VERSION "12.2.7"

NS_ :

BS_:

BU_: AMP CPD EASC HUD MHU XGW_Info PAS_Info PAS_LITE FCAM_Info

BO_ 387 VCU_FS_B: 8 XGW_Info
  SG_ VCU_FS_B_1 : 0|1@0+ (1,0) [0|1] "" MHU
  SG_ VCU_FS_B_2 : 1|1@0+ (1,0) [0|1] "" MHU
  SG_ VCU_FS_B_3 : 2|1@0+ (1,0) [0|1] "" MHU
  SG_ VCU_FS_B_4 : 3|1@0+ (1,0) [0|1] "" MHU
  SG_ VCU_FS_B_5 : 4|1@0+ (1,0) [0|1] "" MHU
  SG_ VCU_FS_B_6 : 5|1@0+ (1,0) [0|1] "" MHU
  SG_ VCU_FS_B_7 : 6|1@0+ (1,0) [0|1] "" MHU
  SG_ VCU_FS_B_8 : 7|1@0+ (1,0) [0|1] "" MHU
  SG_ VCU_FS_B_9 : 8|1@0+ (1,0) [0|1] "" MHU
  SG_ VCU_FS_B_10 : 9|1@0+ (1,0) [0|1] "" MHU
  SG_ VCU_FS_B_11 : 10|1@0+ (1,0) [0|1] "" MHU
  SG_ VCU_FS_B_12 : 11|1@0+ (1,0) [0|1] "" MHU
  SG_ VCU_FS_B_13 : 12|1@0+ (1,0) [0|1] "" MHU
  SG_ VCU_FS_B_14 : 13|1@0+ (1,0) [0|1] "" MHU
  SG_ VCU_FS_B_15 : 14|1@0+ (1,0) [0|1] "" MHU
  SG_ VCU_FS_B_16 : 15|1@0+ (1,0) [0|1] "" MHU
  SG_ VCU_FS_B_17 : 16|1@0+ (1,0) [0|1] "" MHU
  SG_ VCU_FS_B_18 : 17|1@0+ (1,0) [0|1] "" MHU
  SG_ VCU_FS_B_19 : 18|1@0+ (1,0) [0|1] "" MHU
  SG_ VCU_FS_B_20 : 19|1@0+ (1,0) [0|1] "" MHU
  SG_ VCU_FS_B_21 : 20|1@0+ (1,0) [0|1] "" MHU
  SG_ VCU_FS_B_22 : 21|1@0+ (1,0) [0|1] "" MHU
  SG_ VCU_FS_B_23 : 22|1@0+ (1,0) [0|1] "" MHU
  SG_ VCU_FS_B_24 : 23|1@0+ (1,0) [0|1] "" MHU
  SG_ VCU_FS_B_25 : 24|1@0+ (1,0) [0|1] "" MHU
  SG_ VCU_FS_B_26 : 25|1@0+ (1,0) [0|1] "" MHU
  SG_ VCU_FS_B_27 : 26|1@0+ (1,0) [0|1] "" MHU
  SG_ VCU_FS_B_28 : 27|1@0+ (1,0) [0|1] "" MHU
  SG_ VCU_FS_B_29 : 28|1@0+ (1,0) [0|1] "" MHU
  SG_ VCU_FS_B_30 : 29|1@0+ (1,0) [0|1] "" MHU
  SG_ VCU_FS_B_31 : 30|1@0+ (1,0) [0|1] "" MHU
  SG_ VCU_FS_B_32 : 31|1@0+ (1,0) [0|1] "" MHU
  SG_ VCU_FS_B_33 : 32|1@0+ (1,0) [0|1] "" MHU
  SG_ VCU_FS_B_34 : 33|1@0+ (1,0) [0|1] "" MHU
  SG_ VCU_FS_B_35 : 34|1@0+ (1,0) [0|1] "" MHU
  SG_ VCU_FS_B_36 : 35|1@0+ (1,0) [0|1] "" MHU
  SG_ VCU_FS_B_37 : 36|1@0+ (1,0) [0|1] "" MHU
  SG_ VCU_FS_B_38 : 37|1@0+ (1,0) [0|1] "" MHU
  SG_ VCU_FS_B_39 : 38|1@0+ (1,0) [0|1] "" MHU
  SG_ VCU_FS_B_40 : 39|1@0+ (1,0) [0|1] "" MHU
  SG_ VCU_FS_B_41 : 40|1@0+ (1,0) [0|1] "" MHU
  SG_ VCU_FS_B_42 : 41|1@0+ (1,0) [0|1] "" MHU
  SG_ VCU_FS_B_43 : 42|1@0+ (1,0) [0|1] "" MHU
  SG_ VCU_FS_B_44 : 43|1@0+ (1,0) [0|1] "" MHU
  SG_ VCU_FS_B_45 : 44|1@0+ (1,0) [0|1] "" MHU
  SG_ VCU_FS_B_46 : 45|1@0+ (1,0) [0|1] "" MHU
  SG_ VCU_FS_B_47 : 46|1@0+ (1,0) [0|1] "" MHU
  SG_ VCU_FS_B_48 : 47|1@0+ (1,0) [0|1] "" MHU
  SG_ VCU_FS_B_49 : 48|1@0+ (1,0) [0|1] "" MHU
  SG_ VCU_FS_B_50 : 49|1@0+ (1,0) [0|1] "" MHU
  SG_ VCU_FS_B_51 : 50|1@0+ (1,0) [0|1] "" MHU
  SG_ VCU_FS_B_52 : 51|1@0+ (1,0) [0|1] "" MHU
  SG_ VCU_FS_B_53 : 52|1@0+ (1,0) [0|1] "" MHU
  SG_ VCU_FS_B_54 : 53|1@0+ (1,0) [0|1] "" MHU
  SG_ VCU_FS_B_55 : 54|1@0+ (1,0) [0|1] "" MHU
  SG_ VCU_FS_B_56 : 55|1@0+ (1,0) [0|1] "" MHU
  SG_ VCU_FS_B_57 : 56|1@0+ (1,0) [0|1] "" MHU
  SG_ VCU_FS_B_58 : 57|1@0+ (1,0) [0|1] "" MHU
  SG_ VCU_FS_B_59 : 58|1@0+ (1,0) [0|1] "" MHU
  SG_ VCU_FS_B_60 : 59|1@0+ (1,0) [0|1] "" MHU
  SG_ VCU_FS_B_61 : 60|1@0+ (1,0) [0|1] "" MHU
  SG_ VCU_FS_B_62 : 61|1@0+ (1,0) [0|1] "" MHU
  SG_ VCU_FS_B_63 : 62|1@0+ (1,0) [0|1] "" MHU
  SG_ VCU_FS_B_64 : 63|1@0+ (1,0) [0|1] "" MHU

BO_ 388 FCAM_BCM_Status: 8 FCAM_Info
 SG_ CHKSM_FCAM_BCM_Status : 7|8@0+ (1,0) [0|255] ""  XGW_Info
 SG_ ALIVE_FCAM_BCM_Status : 11|4@0+ (1,0) [0|14] ""  XGW_Info
 SG_ FCAM_BCM_IndicatorlightReq : 15|3@0+ (1,0) [0|7] ""  XGW_Info
 SG_ SECCAN_FCAM_BCM_Sts : 63|8@0+ (1,0) [0|255] ""  XGW_Info

BO_ 389 VCU_FS_C: 8 XGW_Info
SG_ VCU_FS_C_1 : 0|1@0+ (1,0) [0|1] ""  MHU
SG_ VCU_FS_C_2 : 1|1@0+ (1,0) [0|1] ""  MHU
SG_ VCU_FS_C_3 : 2|1@0+ (1,0) [0|1] ""  MHU
SG_ VCU_FS_C_4 : 3|1@0+ (1,0) [0|1] ""  MHU
SG_ VCU_FS_C_5 : 4|1@0+ (1,0) [0|1] ""  MHU
SG_ VCU_FS_C_6 : 5|1@0+ (1,0) [0|1] ""  MHU
SG_ VCU_FS_C_7 : 6|1@0+ (1,0) [0|1] ""  MHU
SG_ VCU_FS_C_8 : 7|1@0+ (1,0) [0|1] ""  MHU
SG_ VCU_FS_C_9 : 8|1@0+ (1,0) [0|1] ""  MHU
SG_ VCU_FS_C_10 : 9|1@0+ (1,0) [0|1] ""  MHU
SG_ VCU_FS_C_11 : 10|1@0+ (1,0) [0|1] ""  MHU
SG_ VCU_FS_C_12 : 11|1@0+ (1,0) [0|1] ""  MHU
SG_ VCU_FS_C_13 : 12|1@0+ (1,0) [0|1] ""  MHU
SG_ VCU_FS_C_14 : 13|1@0+ (1,0) [0|1] ""  MHU
SG_ VCU_FS_C_15 : 14|1@0+ (1,0) [0|1] ""  MHU
SG_ VCU_FS_C_16 : 15|1@0+ (1,0) [0|1] ""  MHU
SG_ VCU_FS_C_17 : 16|1@0+ (1,0) [0|1] ""  MHU
SG_ VCU_FS_C_18 : 17|1@0+ (1,0) [0|1] ""  MHU
SG_ VCU_FS_C_19 : 18|1@0+ (1,0) [0|1] ""  MHU
SG_ VCU_FS_C_20 : 19|1@0+ (1,0) [0|1] ""  MHU
SG_ VCU_FS_C_21 : 20|1@0+ (1,0) [0|1] ""  MHU
SG_ VCU_FS_C_22 : 21|1@0+ (1,0) [0|1] ""  MHU
SG_ VCU_FS_C_23 : 22|1@0+ (1,0) [0|1] ""  MHU
SG_ VCU_FS_C_24 : 23|1@0+ (1,0) [0|1] ""  MHU
SG_ VCU_FS_C_25 : 24|1@0+ (1,0) [0|1] ""  MHU
SG_ VCU_FS_C_26 : 25|1@0+ (1,0) [0|1] ""  MHU
SG_ VCU_FS_C_27 : 26|1@0+ (1,0) [0|1] ""  MHU
SG_ VCU_FS_C_28 : 27|1@0+ (1,0) [0|1] ""  MHU
SG_ VCU_FS_C_29 : 28|1@0+ (1,0) [0|1] ""  MHU
SG_ VCU_FS_C_30 : 29|1@0+ (1,0) [0|1] ""  MHU
SG_ VCU_FS_C_31 : 30|1@0+ (1,0) [0|1] ""  MHU
SG_ VCU_FS_C_32 : 31|1@0+ (1,0) [0|1] ""  MHU
SG_ VCU_FS_C_33 : 32|1@0+ (1,0) [0|1] ""  MHU
SG_ VCU_FS_C_34 : 33|1@0+ (1,0) [0|1] ""  MHU
SG_ VCU_FS_C_35 : 34|1@0+ (1,0) [0|1] ""  MHU
SG_ VCU_FS_C_36 : 35|1@0+ (1,0) [0|1] ""  MHU
SG_ VCU_FS_C_37 : 36|1@0+ (1,0) [0|1] ""  MHU
SG_ VCU_FS_C_38 : 37|1@0+ (1,0) [0|1] ""  MHU
SG_ VCU_FS_C_39 : 38|1@0+ (1,0) [0|1] ""  MHU
SG_ VCU_FS_C_40 : 39|1@0+ (1,0) [0|1] ""  MHU
SG_ VCU_FS_C_41 : 40|1@0+ (1,0) [0|1] ""  MHU
SG_ VCU_FS_C_42 : 41|1@0+ (1,0) [0|1] ""  MHU
SG_ VCU_FS_C_43 : 42|1@0+ (1,0) [0|1] ""  MHU
SG_ VCU_FS_C_44 : 43|1@0+ (1,0) [0|1] ""  MHU
SG_ VCU_FS_C_45 : 44|1@0+ (1,0) [0|1] ""  MHU
SG_ VCU_FS_C_46 : 45|1@0+ (1,0) [0|1] ""  MHU
SG_ VCU_FS_C_47 : 46|1@0+ (1,0) [0|1] ""  MHU
SG_ VCU_FS_C_48 : 47|1@0+ (1,0) [0|1] ""  MHU
SG_ VCU_FS_C_49 : 48|1@0+ (1,0) [0|1] ""  MHU
SG_ VCU_FS_C_50 : 49|1@0+ (1,0) [0|1] ""  MHU
SG_ VCU_FS_C_51 : 50|1@0+ (1,0) [0|1] ""  MHU
SG_ VCU_FS_C_52 : 51|1@0+ (1,0) [0|1] ""  MHU
SG_ VCU_FS_C_53 : 52|1@0+ (1,0) [0|1] ""  MHU
SG_ VCU_FS_C_54 : 53|1@0+ (1,0) [0|1] ""  MHU
SG_ VCU_FS_C_55 : 54|1@0+ (1,0) [0|1] ""  MHU
SG_ VCU_FS_C_56 : 55|1@0+ (1,0) [0|1] ""  MHU
SG_ VCU_FS_C_57 : 56|1@0+ (1,0) [0|1] ""  MHU
SG_ VCU_FS_C_58 : 57|1@0+ (1,0) [0|1] ""  MHU
SG_ VCU_FS_C_59 : 58|1@0+ (1,0) [0|1] ""  MHU
SG_ VCU_FS_C_60 : 59|1@0+ (1,0) [0|1] ""  MHU
SG_ VCU_FS_C_61 : 60|1@0+ (1,0) [0|1] ""  MHU
SG_ VCU_FS_C_62 : 61|1@0+ (1,0) [0|1] ""  MHU
SG_ VCU_FS_C_63 : 62|1@0+ (1,0) [0|1] ""  MHU
SG_ VCU_FS_C_64 : 63|1@0+ (1,0) [0|1] ""  MHU

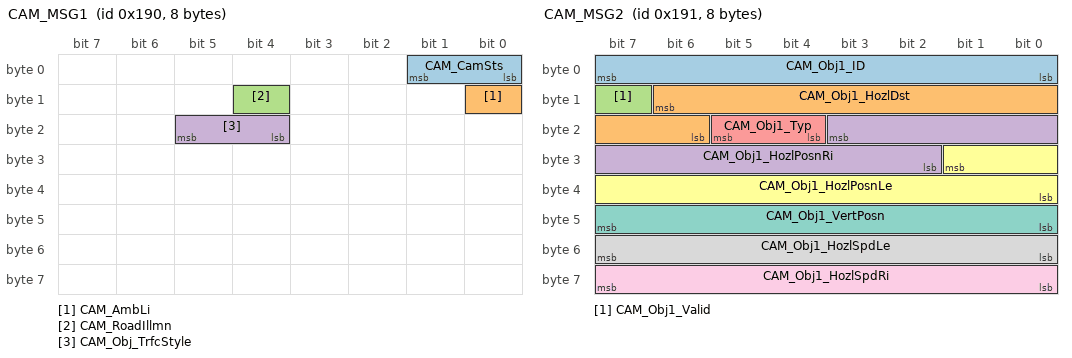
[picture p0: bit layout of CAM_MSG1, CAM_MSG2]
BO_ 400 CAM_MSG1: 8 FCAM_Info
  SG_ CAM_CamSts : 1|2@0+ (1,0) [0|3] ""  XGW_Info
  SG_ CAM_AmbLi : 8|1@0+ (1,0) [0|1] ""  XGW_Info
  SG_ CAM_RoadIllmn : 12|1@0+ (1,0) [0|1] ""  XGW_Info
  SG_ CAM_Obj_TrfcStyle : 21|2@0+ (1,0) [0|3] ""  XGW_Info

BO_ 401 CAM_MSG2: 8 FCAM_Info
  SG_ CAM_Obj1_ID : 7|8@0+ (1,0) [0|255] ""  XGW_Info
  SG_ CAM_Obj1_HozlDst : 14|9@0+ (1,0) [0|511] "m"  XGW_Info
  SG_ CAM_Obj1_Valid : 15|1@0+ (1,0) [0|1] ""  XGW_Info
  SG_ CAM_Obj1_HozlPosnRi : 19|10@0+ (0.08,-40) [-40|40] "degree"  XGW_Info
  SG_ CAM_Obj1_Typ : 21|2@0+ (1,0) [0|3] ""  XGW_Info
  SG_ CAM_Obj1_HozlPosnLe : 25|10@0+ (0.08,-40) [-40|40] "degree"  XGW_Info
  SG_ CAM_Obj1_VertPosn : 47|8@0+ (0.1,-12) [-12|12] "degree"  XGW_Info
  SG_ CAM_Obj1_HozlSpdLe : 55|8@0+ (0.5,-64) [-64|63.5] "degree/s"  XGW_Info
  SG_ CAM_Obj1_HozlSpdRi : 63|8@0+ (0.5,-64) [-64|63.5] "degree/s"  XGW_Info

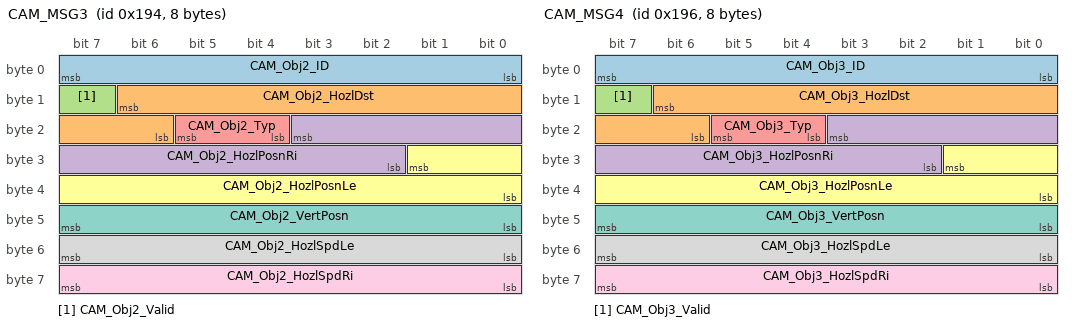
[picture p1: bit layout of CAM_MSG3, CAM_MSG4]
BO_ 404 CAM_MSG3: 8 FCAM_Info
  SG_ CAM_Obj2_ID : 7|8@0+ (1,0) [0|255] ""  XGW_Info
  SG_ CAM_Obj2_HozlDst : 14|9@0+ (1,0) [0|511] "m"  XGW_Info
  SG_ CAM_Obj2_Valid : 15|1@0+ (1,0) [0|1] ""  XGW_Info
  SG_ CAM_Obj2_HozlPosnRi : 19|10@0+ (0.08,-40) [-40|40] "degree"  XGW_Info
  SG_ CAM_Obj2_Typ : 21|2@0+ (1,0) [0|3] ""  XGW_Info
  SG_ CAM_Obj2_HozlPosnLe : 25|10@0+ (0.08,-40) [-40|40] "degree"  XGW_Info
  SG_ CAM_Obj2_VertPosn : 47|8@0+ (0.1,-12) [-12|12] "degree"  XGW_Info
  SG_ CAM_Obj2_HozlSpdLe : 55|8@0+ (0.5,-64) [-64|63.5] "degree/s"  XGW_Info
  SG_ CAM_Obj2_HozlSpdRi : 63|8@0+ (0.5,-64) [-64|63.5] "degree/s"  XGW_Info

BO_ 406 CAM_MSG4: 8 FCAM_Info
  SG_ CAM_Obj3_ID : 7|8@0+ (1,0) [0|255] ""  XGW_Info
  SG_ CAM_Obj3_HozlDst : 14|9@0+ (1,0) [0|511] "m"  XGW_Info
  SG_ CAM_Obj3_Valid : 15|1@0+ (1,0) [0|1] ""  XGW_Info
  SG_ CAM_Obj3_HozlPosnRi : 19|10@0+ (0.08,-40) [-40|40] "degree"  XGW_Info
  SG_ CAM_Obj3_Typ : 21|2@0+ (1,0) [0|3] ""  XGW_Info
  SG_ CAM_Obj3_HozlPosnLe : 25|10@0+ (0.08,-40) [-40|40] "degree"  XGW_Info
  SG_ CAM_Obj3_VertPosn : 47|8@0+ (0.1,-12) [-12|12] "degree"  XGW_Info
  SG_ CAM_Obj3_HozlSpdLe : 55|8@0+ (0.5,-64) [-64|63.5] "degree/s"  XGW_Info
  SG_ CAM_Obj3_HozlSpdRi : 63|8@0+ (0.5,-64) [-64|63.5] "degree/s"  XGW_Info

BO_ 409 VCU_Sts1: 8 XGW_Info
  SG_ CHSKM_VCU_Sts1 : 7|8@0+ (1,0) [0|255] "" MHU
  SG_ ALV_VCU_Sts1 : 11|4@0+ (1,0) [0|14] "" MHU
  SG_ VCU_BMS_HVOnOff_REQ : 19|2@0+ (1,0) [0|1] "" MHU

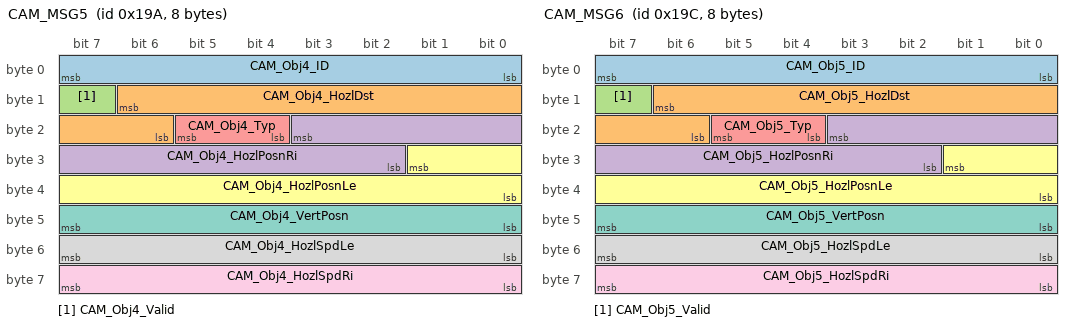
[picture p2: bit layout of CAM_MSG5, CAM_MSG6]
BO_ 410 CAM_MSG5: 8 FCAM_Info
  SG_ CAM_Obj4_ID : 7|8@0+ (1,0) [0|255] ""  XGW_Info
  SG_ CAM_Obj4_HozlDst : 14|9@0+ (1,0) [0|511] "m"  XGW_Info
  SG_ CAM_Obj4_Valid : 15|1@0+ (1,0) [0|1] ""  XGW_Info
  SG_ CAM_Obj4_HozlPosnRi : 19|10@0+ (0.08,-40) [-40|40] "degree"  XGW_Info
  SG_ CAM_Obj4_Typ : 21|2@0+ (1,0) [0|3] ""  XGW_Info
  SG_ CAM_Obj4_HozlPosnLe : 25|10@0+ (0.08,-40) [-40|40] "degree"  XGW_Info
  SG_ CAM_Obj4_VertPosn : 47|8@0+ (0.1,-12) [-12|12] "degree"  XGW_Info
  SG_ CAM_Obj4_HozlSpdLe : 55|8@0+ (0.5,-64) [-64|63.5] "degree/s"  XGW_Info
  SG_ CAM_Obj4_HozlSpdRi : 63|8@0+ (0.5,-64) [-64|63.5] "degree/s"  XGW_Info

BO_ 412 CAM_MSG6: 8 FCAM_Info
  SG_ CAM_Obj5_ID : 7|8@0+ (1,0) [0|255] ""  XGW_Info
  SG_ CAM_Obj5_HozlDst : 14|9@0+ (1,0) [0|511] "m"  XGW_Info
  SG_ CAM_Obj5_Valid : 15|1@0+ (1,0) [0|1] ""  XGW_Info
  SG_ CAM_Obj5_HozlPosnRi : 19|10@0+ (0.08,-40) [-40|40] "degree"  XGW_Info
  SG_ CAM_Obj5_Typ : 21|2@0+ (1,0) [0|3] ""  XGW_Info
  SG_ CAM_Obj5_HozlPosnLe : 25|10@0+ (0.08,-40) [-40|40] "degree"  XGW_Info
  SG_ CAM_Obj5_VertPosn : 47|8@0+ (0.1,-12) [-12|12] "degree"  XGW_Info
  SG_ CAM_Obj5_HozlSpdLe : 55|8@0+ (0.5,-64) [-64|63.5] "degree/s"  XGW_Info
  SG_ CAM_Obj5_HozlSpdRi : 63|8@0+ (0.5,-64) [-64|63.5] "degree/s"  XGW_Info

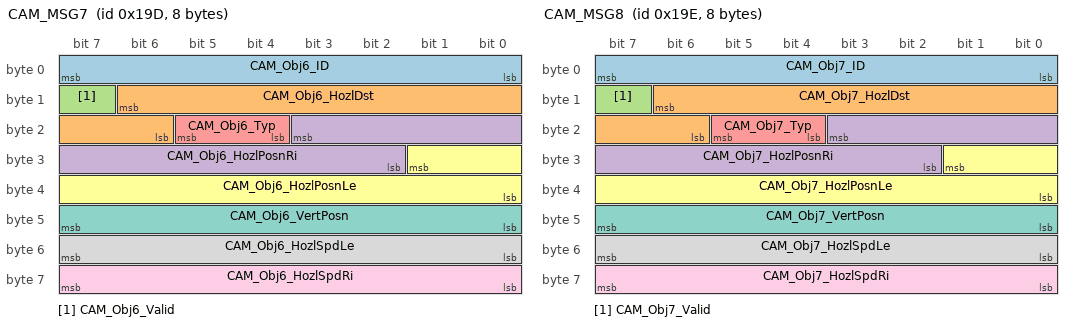
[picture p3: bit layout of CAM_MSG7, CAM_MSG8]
BO_ 413 CAM_MSG7: 8 FCAM_Info
  SG_ CAM_Obj6_ID : 7|8@0+ (1,0) [0|255] ""  XGW_Info
  SG_ CAM_Obj6_HozlDst : 14|9@0+ (1,0) [0|511] "m"  XGW_Info
  SG_ CAM_Obj6_Valid : 15|1@0+ (1,0) [0|1] ""  XGW_Info
  SG_ CAM_Obj6_HozlPosnRi : 19|10@0+ (0.08,-40) [-40|40] "degree"  XGW_Info
  SG_ CAM_Obj6_Typ : 21|2@0+ (1,0) [0|3] ""  XGW_Info
  SG_ CAM_Obj6_HozlPosnLe : 25|10@0+ (0.08,-40) [-40|40] "degree"  XGW_Info
  SG_ CAM_Obj6_VertPosn : 47|8@0+ (0.1,-12) [-12|12] "degree"  XGW_Info
  SG_ CAM_Obj6_HozlSpdLe : 55|8@0+ (0.5,-64) [-64|63.5] "degree/s"  XGW_Info
  SG_ CAM_Obj6_HozlSpdRi : 63|8@0+ (0.5,-64) [-64|63.5] "degree/s"  XGW_Info

BO_ 414 CAM_MSG8: 8 FCAM_Info
  SG_ CAM_Obj7_ID : 7|8@0+ (1,0) [0|255] ""  XGW_Info
  SG_ CAM_Obj7_HozlDst : 14|9@0+ (1,0) [0|511] "m"  XGW_Info
  SG_ CAM_Obj7_Valid : 15|1@0+ (1,0) [0|1] ""  XGW_Info
  SG_ CAM_Obj7_HozlPosnRi : 19|10@0+ (0.08,-40) [-40|40] "degree"  XGW_Info
  SG_ CAM_Obj7_Typ : 21|2@0+ (1,0) [0|3] ""  XGW_Info
  SG_ CAM_Obj7_HozlPosnLe : 25|10@0+ (0.08,-40) [-40|40] "degree"  XGW_Info
  SG_ CAM_Obj7_VertPosn : 47|8@0+ (0.1,-12) [-12|12] "degree"  XGW_Info
  SG_ CAM_Obj7_HozlSpdLe : 55|8@0+ (0.5,-64) [-64|63.5] "degree/s"  XGW_Info
  SG_ CAM_Obj7_HozlSpdRi : 63|8@0+ (0.5,-64) [-64|63.5] "degree/s"  XGW_Info

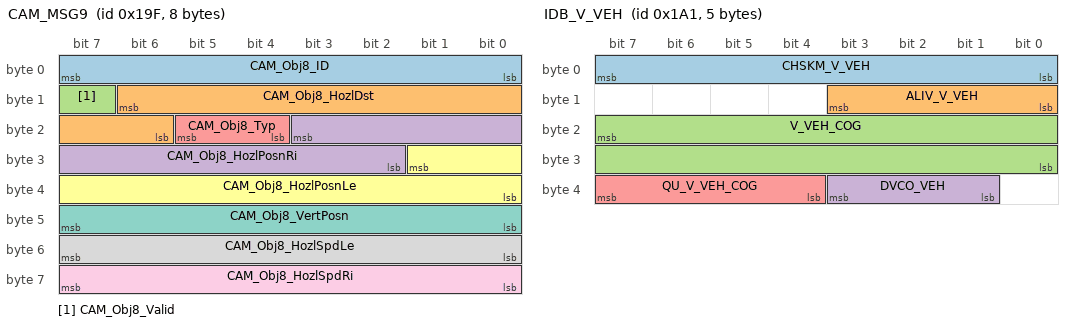
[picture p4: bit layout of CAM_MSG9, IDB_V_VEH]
BO_ 415 CAM_MSG9: 8 FCAM_Info
  SG_ CAM_Obj8_ID : 7|8@0+ (1,0) [0|255] ""  XGW_Info
  SG_ CAM_Obj8_HozlDst : 14|9@0+ (1,0) [0|511] "m"  XGW_Info
  SG_ CAM_Obj8_Valid : 15|1@0+ (1,0) [0|1] ""  XGW_Info
  SG_ CAM_Obj8_HozlPosnRi : 19|10@0+ (0.08,-40) [-40|40] "degree"  XGW_Info
  SG_ CAM_Obj8_Typ : 21|2@0+ (1,0) [0|3] ""  XGW_Info
  SG_ CAM_Obj8_HozlPosnLe : 25|10@0+ (0.08,-40) [-40|40] "degree"  XGW_Info
  SG_ CAM_Obj8_VertPosn : 47|8@0+ (0.1,-12) [-12|12] "degree"  XGW_Info
  SG_ CAM_Obj8_HozlSpdLe : 55|8@0+ (0.5,-64) [-64|63.5] "degree/s"  XGW_Info
  SG_ CAM_Obj8_HozlSpdRi : 63|8@0+ (0.5,-64) [-64|63.5] "degree/s"  XGW_Info

BO_ 417 IDB_V_VEH: 5 XGW_Info
 SG_ CHSKM_V_VEH : 7|8@0+ (1,0) [0|255] ""  MHU,PAS_LITE
 SG_ ALIV_V_VEH : 11|4@0+ (1,0) [0|14] ""  MHU,PAS_LITE
 SG_ V_VEH_COG : 23|16@0+ (0.015625,0) [0|350] "km/h"  MHU
 SG_ DVCO_VEH : 35|3@0+ (1,0) [0|7] ""  MHU,PAS_Info,PAS_LITE
 SG_ QU_V_VEH_COG : 39|4@0+ (1,0) [0|15] ""  MHU

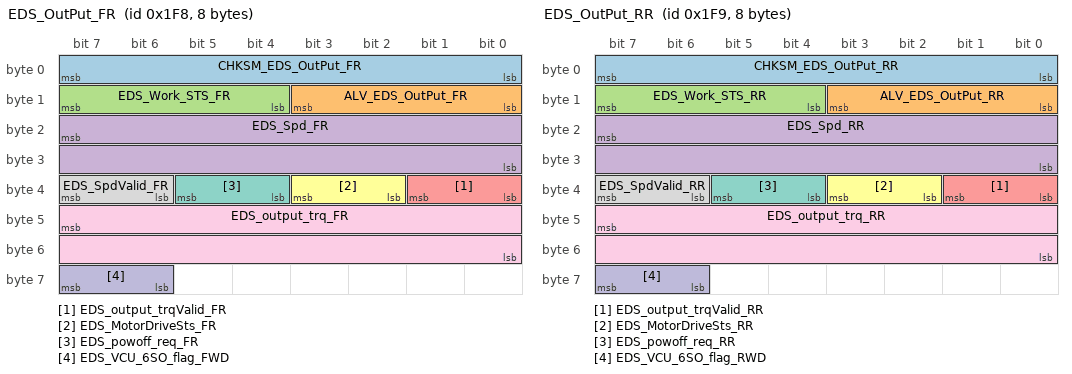
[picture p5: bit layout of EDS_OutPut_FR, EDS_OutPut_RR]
BO_ 504 EDS_OutPut_FR: 8 XGW_Info
  SG_ CHKSM_EDS_OutPut_FR : 7|8@0+ (1,0) [0|255] "" Vector__XXX,AMP,CPD,EASC,HUD,MHU,PAS_Info
  SG_ ALV_EDS_OutPut_FR : 11|4@0+ (1,0) [0|14] "" Vector__XXX,AMP,CPD,EASC,HUD,MHU,PAS_Info
  SG_ EDS_Work_STS_FR : 15|4@0+ (1,0) [0|15] "-" Vector__XXX,AMP,CPD,EASC,HUD,MHU,PAS_Info
  SG_ EDS_Spd_FR : 23|16@0+ (1,-20000) [-20000|20000] "rpm" Vector__XXX,AMP,CPD,EASC,HUD,MHU,PAS_Info
  SG_ EDS_output_trqValid_FR : 33|2@0+ (1,0) [0|1] "" Vector__XXX,AMP,CPD,EASC,HUD,MHU,PAS_Info
  SG_ EDS_MotorDriveSts_FR : 35|2@0+ (1,0) [0|3] "" Vector__XXX,AMP,CPD,EASC,HUD,MHU,PAS_Info
  SG_ EDS_powoff_req_FR : 37|2@0+ (1,0) [0|1] "" Vector__XXX,AMP,CPD,EASC,HUD,MHU,PAS_Info
  SG_ EDS_SpdValid_FR : 39|2@0+ (1,0) [0|1] "" Vector__XXX,AMP,CPD,EASC,HUD,MHU,PAS_Info
  SG_ EDS_output_trq_FR : 47|16@0+ (1,-2000) [-2000|2000] "Nm" Vector__XXX,AMP,CPD,EASC,HUD,MHU,PAS_Info
  SG_ EDS_VCU_6SO_flag_FWD : 63|2@0+ (1,0) [0|1] "" Vector__XXX,AMP,CPD,EASC,HUD,MHU,PAS_Info

BO_ 505 EDS_OutPut_RR: 8 XGW_Info
  SG_ CHKSM_EDS_OutPut_RR : 7|8@0+ (1,0) [0|255] "" Vector__XXX,AMP,CPD,EASC,HUD,MHU,PAS_Info
  SG_ ALV_EDS_OutPut_RR : 11|4@0+ (1,0) [0|14] "" Vector__XXX,AMP,CPD,EASC,HUD,MHU,PAS_Info
  SG_ EDS_Work_STS_RR : 15|4@0+ (1,0) [0|15] "-" Vector__XXX,AMP,CPD,EASC,HUD,MHU,PAS_Info
  SG_ EDS_Spd_RR : 23|16@0+ (1,-20000) [-20000|20000] "rpm" Vector__XXX,AMP,CPD,EASC,HUD,MHU,PAS_Info
  SG_ EDS_output_trqValid_RR : 33|2@0+ (1,0) [0|1] "" Vector__XXX,AMP,CPD,EASC,HUD,MHU,PAS_Info
  SG_ EDS_MotorDriveSts_RR : 35|2@0+ (1,0) [0|3] "" Vector__XXX,AMP,CPD,EASC,HUD,MHU,PAS_Info
  SG_ EDS_powoff_req_RR : 37|2@0+ (1,0) [0|1] "" Vector__XXX,AMP,CPD,EASC,HUD,MHU,PAS_Info
  SG_ EDS_SpdValid_RR : 39|2@0+ (1,0) [0|1] "" Vector__XXX,AMP,CPD,EASC,HUD,MHU,PAS_Info
  SG_ EDS_output_trq_RR : 47|16@0+ (1,-2000) [-2000|2000] "Nm" Vector__XXX,AMP,CPD,EASC,HUD,MHU,PAS_Info
  SG_ EDS_VCU_6SO_flag_RWD : 63|2@0+ (1,0) [0|1] "-" Vector__XXX,AMP,CPD,EASC,HUD,MHU,PAS_Info

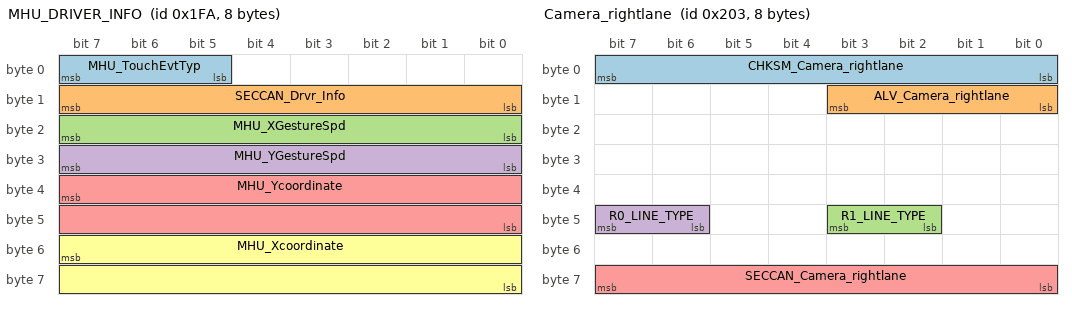
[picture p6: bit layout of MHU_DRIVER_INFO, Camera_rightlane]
BO_ 506 MHU_DRIVER_INFO: 8 MHU
  SG_ MHU_TouchEvtTyp : 7|3@0+ (1,0) [0|7] "-" Vector__XXX,PAS_Info
  SG_ SECCAN_Drvr_Info : 15|8@0+ (1,0) [0|255] "" Vector__XXX,PAS_Info
  SG_ MHU_XGestureSpd : 23|8@0+ (1,0) [0|255] "-" Vector__XXX
  SG_ MHU_YGestureSpd : 31|8@0+ (1,0) [0|255] "-" Vector__XXX
  SG_ MHU_Ycoordinate : 39|16@0+ (1,0) [0|65535] "-" Vector__XXX,PAS_Info
  SG_ MHU_Xcoordinate : 55|16@0+ (1,0) [0|65535] "-" Vector__XXX,PAS_Info

BO_ 515 Camera_rightlane: 8 FCAM_Info
  SG_ CHKSM_Camera_rightlane : 7|8@0+ (1,0) [0|255] "" MHU
  SG_ ALV_Camera_rightlane : 11|4@0+ (1,0) [0|14] "" MHU
  SG_ R1_LINE_TYPE : 43|2@0+ (1,0) [0|3] "-" MHU
  SG_ R0_LINE_TYPE : 47|2@0+ (1,0) [0|3] "-" MHU
  SG_ SECCAN_Camera_rightlane : 63|8@0+ (1,0) [0|255] "" MHU

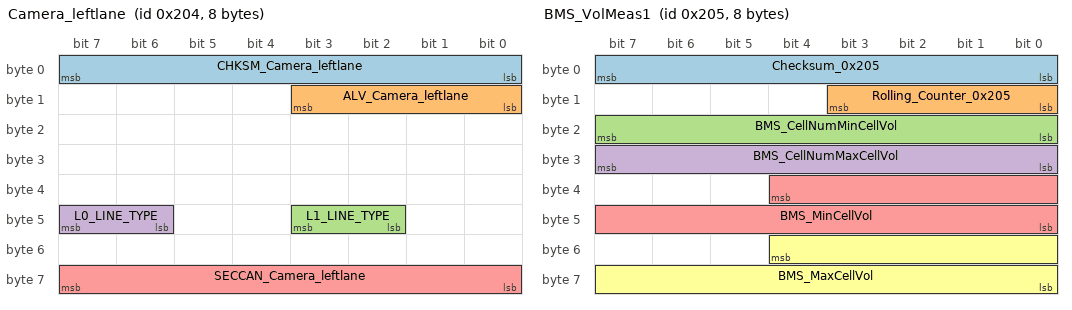
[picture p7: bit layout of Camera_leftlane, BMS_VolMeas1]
BO_ 516 Camera_leftlane: 8 FCAM_Info
  SG_ CHKSM_Camera_leftlane : 7|8@0+ (1,0) [0|255] "" MHU
  SG_ ALV_Camera_leftlane : 11|4@0+ (1,0) [0|14] "" MHU
  SG_ L1_LINE_TYPE : 43|2@0+ (1,0) [0|3] "-" MHU
  SG_ L0_LINE_TYPE : 47|2@0+ (1,0) [0|3] "-" MHU
  SG_ SECCAN_Camera_leftlane : 63|8@0+ (1,0) [0|255] "" MHU

BO_ 517 BMS_VolMeas1: 8 XGW_Info
  SG_ Checksum_0x205 : 7|8@0+ (1,0) [0|255] "" MHU
  SG_ Rolling_Counter_0x205 : 11|4@0+ (1,0) [0|14] "" MHU
  SG_ BMS_CellNumMinCellVol : 23|8@0+ (1,0) [0|255] "" MHU
  SG_ BMS_CellNumMaxCellVol : 31|8@0+ (1,0) [0|255] "" MHU
  SG_ BMS_MinCellVol : 36|13@0+ (0.001,0) [0|6] "V" MHU
  SG_ BMS_MaxCellVol : 52|13@0+ (0.001,0) [0|6] "V" MHU

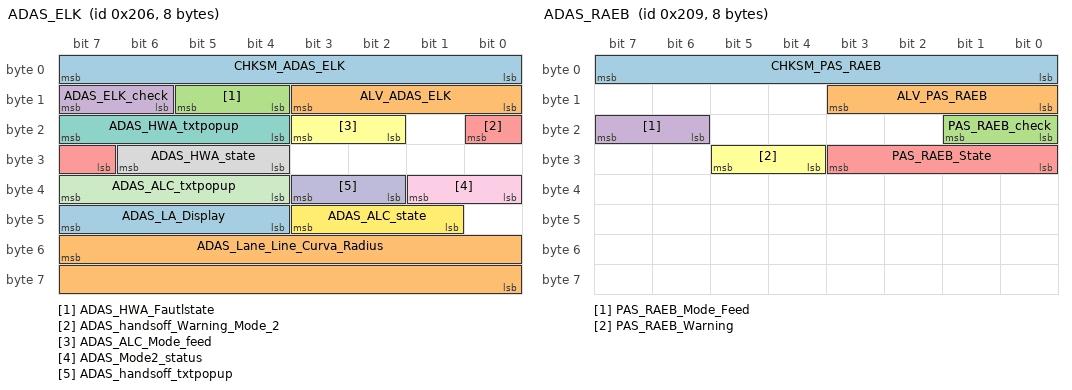
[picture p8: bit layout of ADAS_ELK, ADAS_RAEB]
BO_ 518 ADAS_ELK: 8 FCAM_Info
  SG_ CHKSM_ADAS_ELK : 7|8@0+ (1,0) [0|255] "" HUD,MHU,PAS_Info,XGW_Info
  SG_ ALV_ADAS_ELK : 11|4@0+ (1,0) [0|14] "" HUD,MHU,PAS_Info,XGW_Info
  SG_ ADAS_HWA_Fautlstate : 13|2@0+ (1,0) [0|3] "-" HUD,MHU,XGW_Info
  SG_ ADAS_ELK_check : 15|2@0+ (1,0) [0|3] "-" HUD,MHU,XGW_Info
  SG_ ADAS_handsoff_Warning_Mode_2 : 16|2@0+ (1,0) [0|3] "-" HUD,MHU,XGW_Info
  SG_ ADAS_ALC_Mode_feed : 19|2@0+ (1,0) [0|3] "-" HUD,MHU,XGW_Info
  SG_ ADAS_HWA_txtpopup : 23|4@0+ (1,0) [0|15] "-" HUD,MHU,XGW_Info
  SG_ ADAS_HWA_state : 30|3@0+ (1,0) [0|7] "-" HUD,MHU,XGW_Info,PAS_Info
  SG_ ADAS_Mode2_status : 33|2@0+ (1,0) [0|3] ""  HUD,MHU,XGW_Info
  SG_ ADAS_handsoff_txtpopup : 35|2@0+ (1,0) [0|3] "-" HUD,MHU,XGW_Info
  SG_ ADAS_ALC_txtpopup : 39|4@0+ (1,0) [0|15] "-" HUD,MHU,XGW_Info
  SG_ ADAS_ALC_state : 43|3@0+ (1,0) [0|7] "-" HUD,MHU,XGW_Info
  SG_ ADAS_LA_Display : 47|4@0+ (1,0) [0|15] "-" HUD,MHU,XGW_Info
  SG_ ADAS_Lane_Line_Curva_Radius : 55|16@0- (1,0) [-32768|32767] "m" HUD,MHU,XGW_Info

BO_ 519 BCM_SunroofSts: 8 XGW_Info
  SG_ SR_Undervoltage_Fault_Sts : 0|1@0+ (1,0) [0|1] "" MHU
  SG_ SR_Overvoltage_Fault_Sts : 1|1@0+ (1,0) [0|1] "" MHU
  SG_ SR_SLEEP_RQ : 2|1@0+ (1,0) [0|1] "-" MHU
  SG_ SR_Position : 5|3@0+ (1,0) [0|7] "" CPD,MHU
  SG_ SR_Motor_Running_Sts : 7|2@0+ (1,0) [0|3] "" MHU
  SG_ SR_MotorReverse_Fault_Sts : 8|1@0+ (1,0) [0|1] "" MHU
  SG_ SR_Hall_Fault_Sts : 9|1@0+ (1,0) [0|1] "" MHU
  SG_ SR_Normalisation_Sts : 10|1@0+ (1,0) [0|1] "" MHU
  SG_ SR_Relay_Fault : 11|1@0+ (1,0) [0|1] "" MHU
  SG_ SR_Commu_Fault_Sts : 12|1@0+ (1,0) [0|1] "" MHU
  SG_ SR_Initialisation_Status : 13|1@0+ (1,0) [0|1] "" MHU
  SG_ SR_Ctrl_Result : 15|2@0+ (1,0) [0|3] "" MHU
  SG_ SR_ThermalProtection_Fault_Sts : 16|1@0+ (1,0) [0|1] "-" MHU
  SG_ SR_Posit_Percentage : 23|7@0+ (1,0) [0|100] "%" CPD,MHU
  SG_ SR_Operation_Stat : 27|4@0+ (1,0) [0|8] "-" MHU
  SG_ SR_Error_RSP : 28|1@0+ (1,0) [0|1] "" MHU
  SG_ BCM_AutoSunroof_Sts : 30|2@0+ (1,0) [0|3] ""  MHU

BO_ 520 BCM_SunshadeSts: 8 XGW_Info
  SG_ SS_MotorReverse_Fault_Status : 0|1@0+ (1,0) [0|1] "" MHU
  SG_ SS_Motor_Running_Status : 2|2@0+ (1,0) [0|3] "" MHU
  SG_ SS_Position : 5|3@0+ (1,0) [0|7] "" MHU
  SG_ SS_SLEEP_RQ : 6|1@0+ (1,0) [0|1] "-" MHU
  SG_ SS_Undervoltage_Fault_Status : 7|1@0+ (1,0) [0|1] "" MHU
  SG_ SS_Ctrl_Result : 9|2@0+ (1,0) [0|3] "" MHU
  SG_ SS_Overvoltage_Fault_Status : 10|1@0+ (1,0) [0|1] "" MHU
  SG_ SS_Relay_Fault : 11|1@0+ (1,0) [0|1] "" MHU
  SG_ SS_Normalisation_Status : 12|1@0+ (1,0) [0|1] "" MHU
  SG_ SS_Hall_Fault_Status : 13|1@0+ (1,0) [0|1] "" MHU
  SG_ SS_Commu_Fault_Status : 14|1@0+ (1,0) [0|1] "" MHU
  SG_ SS_Initialisation_Status : 15|1@0+ (1,0) [0|1] "" MHU
  SG_ SS_Posit_Percentage : 22|7@0+ (1,0) [0|100] "%" MHU
  SG_ SS_ThermalProtection_Flt_Sts : 23|1@0+ (1,0) [0|1] "" MHU
  SG_ SS_Operation_State : 31|3@0+ (1,0) [0|7] "" MHU
  SG_ SECCAN_SunshadeSts : 55|8@0+ (1,0) [0|255] "" MHU
  SG_ SS_Error_RSP : 63|1@0+ (1,0) [0|1] "" MHU

BO_ 521 ADAS_RAEB: 8 PAS_Info
 SG_ CHKSM_PAS_RAEB : 7|8@0+ (1,0) [0|255] ""  FCAM_Info,HUD,MHU,XGW_Info
 SG_ ALV_PAS_RAEB : 11|4@0+ (1,0) [0|14] ""  FCAM_Info,HUD,MHU,XGW_Info
 SG_ PAS_RAEB_check : 17|2@0+ (1,0) [0|3] ""  HUD,MHU,XGW_Info
 SG_ PAS_RAEB_Mode_Feed : 23|2@0+ (1,0) [0|3] ""  HUD,MHU
 SG_ PAS_RAEB_State : 27|4@0+ (1,0) [0|15] ""  FCAM_Info,HUD,MHU,XGW_Info
 SG_ PAS_RAEB_Warning : 29|2@0+ (1,0) [0|3] ""  HUD,MHU,XGW_Info

BO_ 522 ETG_STATUS: 8 XGW_Info
  SG_ ETG_Lift_Gate_Status : 2|3@0+ (1,0) [0|7] "-" MHU
  SG_ ETG_Power_Latch_Status : 5|3@0+ (1,0) [0|7] "-" MHU
  SG_ ETG_Latch_Segment : 7|2@0+ (1,0) [0|3] "" MHU
  SG_ ETG_Opening_Percentage : 15|8@0+ (1,0) [0|100] "%" MHU
  SG_ ETG_DSW_Status : 16|1@0+ (1,0) [0|1] "" MHU
  SG_ ETG_GSW_Status : 17|1@0+ (1,0) [0|1] "" MHU
  SG_ ETG_LTS_Status : 18|1@0+ (1,0) [0|1] "-" MHU
  SG_ ETG_RTS_Status : 19|1@0+ (1,0) [0|1] "-" MHU
  SG_ ETG_HAL_Status : 20|1@0+ (1,0) [0|1] "-" MHU
  SG_ ETG_FUL_Status : 21|1@0+ (1,0) [0|1] "-" MHU
  SG_ ETG_AJR_Status : 22|1@0+ (1,0) [0|1] "" MHU
  SG_ ETG_NTL_Status : 23|1@0+ (1,0) [0|1] "-" MHU
  SG_ ETG_ERR_Voltage : 25|2@0+ (1,0) [0|3] "-" MHU
  SG_ ETG_ERR_Left_Motor : 27|2@0+ (1,0) [0|3] "" MHU
  SG_ ETG_ERR_Right_Motor : 29|2@0+ (1,0) [0|3] "-" MHU
  SG_ ETG_ERR_Latch : 31|2@0+ (1,0) [0|3] "-" MHU
  SG_ ETG_ERR_Hall : 33|2@0+ (1,0) [0|3] "" MHU
  SG_ ETG_Lift_Motor_Stall : 34|1@0+ (1,0) [0|1] "" MHU
  SG_ ETG_Lift_Motor_AntiPinch : 35|1@0+ (1,0) [0|1] "-" MHU
  SG_ ETG_Lift_Motor_Thermal : 36|1@0+ (1,0) [0|1] "" MHU
  SG_ ETG_Power_Latch_Thermal : 37|1@0+ (1,0) [0|1] "-" MHU
  SG_ ETG_Abuse_Protection : 38|1@0+ (1,0) [0|1] "" MHU

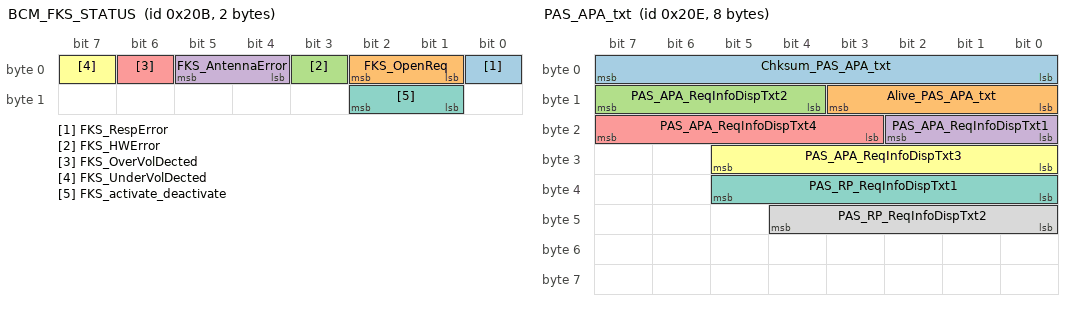
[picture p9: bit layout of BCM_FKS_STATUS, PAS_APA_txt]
BO_ 523 BCM_FKS_STATUS: 2 XGW_Info
  SG_ FKS_RespError : 0|1@0+ (1,0) [0|1] "-" MHU
  SG_ FKS_OpenReq : 2|2@0+ (1,0) [0|3] "" MHU
  SG_ FKS_HWError : 3|1@0+ (1,0) [0|1] "-" MHU
  SG_ FKS_AntennaError : 5|2@0+ (1,0) [0|3] "-" MHU
  SG_ FKS_OverVolDected : 6|1@0+ (1,0) [0|1] "-" MHU
  SG_ FKS_UnderVolDected : 7|1@0+ (1,0) [0|1] "-" MHU
  SG_ FKS_activate_deactivate : 10|2@0+ (1,0) [0|3] "-" MHU

BO_ 524 IC_ODO: 8 MHU
  SG_ CHKSM_IC_ODO : 7|8@0+ (1,0) [0|255] "" HUD,XGW_Info,FCAM_Info,PAS_LITE
  SG_ ALIV_IC_ODO : 11|4@0+ (1,0) [0|14] "" HUD,XGW_Info,FCAM_Info,PAS_LITE
  SG_ MHU_Odometer_IC : 23|20@0+ (1,0) [0|999999] "km" HUD,XGW_Info,FCAM_Info,PAS_LITE

BO_ 525 IDB_STATUS: 8 XGW_Info
  SG_ CHKSM_IDB_STATUS : 7|8@0+ (1,0) [0|255] "" Vector__XXX,AMP,CPD,EASC,HUD,MHU,PAS_LITE
  SG_ ALV_IDB_STATUS : 11|4@0+ (1,0) [0|14] "" Vector__XXX,AMP,CPD,EASC,HUD,MHU,PAS_LITE
  SG_ ESPTransRequestType : 13|2@0+ (1,0) [0|3] "" Vector__XXX,AMP,CPD,EASC,HUD,MHU
  SG_ ABSFault : 14|1@0+ (1,0) [0|1] "" Vector__XXX,AMP,CPD,EASC,HUD,MHU
  SG_ ABSActive : 15|1@0+ (1,0) [0|1] "" Vector__XXX,AMP,CPD,EASC,HUD,MHU
  SG_ VehicleSpd : 23|13@0+ (0.05625,0) [0|300] "km/h" Vector__XXX,AMP,CPD,EASC,HUD,MHU,PAS_LITE
  SG_ ESC_VehicleStandstill : 24|1@0+ (1,0) [0|1] "" Vector__XXX,AMP,CPD,EASC,HUD,MHU
  SG_ MCPressureSts : 25|1@0+ (1,0) [0|1] "" Vector__XXX,AMP,CPD,EASC,HUD,MHU
  SG_ VehicleSpdSts : 26|1@0+ (1,0) [0|1] "" Vector__XXX,AMP,CPD,EASC,HUD,MHU,PAS_LITE
  SG_ MCPressure : 39|8@0+ (2,-42.5) [-42.5|465.5] "bar" Vector__XXX,AMP,CPD,EASC,HUD,MHU
  SG_ ESC_Braking_effort : 40|1@0+ (1,0) [0|1] "" Vector__XXX,AMP,CPD,EASC,HUD,MHU
  SG_ BRAKE_LightonRequestEPBi : 42|2@0+ (1,0) [0|3] "" Vector__XXX,AMP,CPD,EASC,HUD,MHU
  SG_ VDCActive : 43|1@0+ (1,0) [0|1] "" Vector__XXX,AMP,CPD,EASC,HUD,MHU
  SG_ TCSActive : 44|1@0+ (1,0) [0|1] "" Vector__XXX,AMP,CPD,EASC,HUD,MHU
  SG_ TCSAvailable : 45|1@0+ (1,0) [0|1] "" Vector__XXX,AMP,CPD,EASC,HUD,MHU
  SG_ IDBActive : 46|1@0+ (1,0) [0|1] "" Vector__XXX,AMP,CPD,EASC,HUD,MHU
  SG_ IDBFault : 47|1@0+ (1,0) [0|1] "" Vector__XXX,AMP,CPD,EASC,HUD,MHU
  SG_ ESC_VehicleHoldStat : 51|2@0+ (1,0) [0|3] "" Vector__XXX,AMP,CPD,EASC,HUD,MHU
  SG_ IDB_Power_Stage : 55|4@0+ (1,0) [0|15] "" Vector__XXX,AMP,CPD,EASC,HUD,MHU
  SG_ ESC_BrakeReleasedFailsafe : 56|1@0+ (1,0) [0|1] "" Vector__XXX,AMP,CPD,EASC,HUD,MHU

BO_ 526 PAS_APA_txt: 8 PAS_Info
  SG_ Chksum_PAS_APA_txt : 7|8@0+ (1,0) [0|255] ""  MHU
  SG_ Alive_PAS_APA_txt : 11|4@0+ (1,0) [0|14] ""  MHU
  SG_ PAS_APA_ReqInfoDispTxt2 : 15|4@0+ (1,0) [0|15] ""  MHU
  SG_ PAS_APA_ReqInfoDispTxt1 : 18|3@0+ (1,0) [0|7] ""  MHU
  SG_ PAS_APA_ReqInfoDispTxt4 : 23|5@0+ (1,0) [0|31] ""  MHU
  SG_ PAS_APA_ReqInfoDispTxt3 : 29|6@0+ (1,0) [0|63] ""  MHU
  SG_ PAS_RP_ReqInfoDispTxt1 : 37|6@0+ (1,0) [0|63] ""  MHU
  SG_ PAS_RP_ReqInfoDispTxt2 : 44|5@0+ (1,0) [0|31] ""  MHU

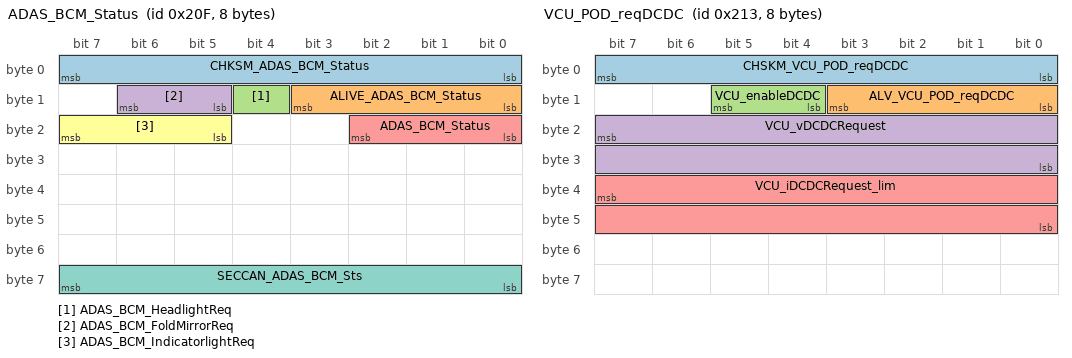
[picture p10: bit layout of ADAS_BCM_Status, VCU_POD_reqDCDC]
BO_ 527 ADAS_BCM_Status: 8 PAS_Info
  SG_ CHKSM_ADAS_BCM_Status : 7|8@0+ (1,0) [0|255] ""  XGW_Info
  SG_ ALIVE_ADAS_BCM_Status : 11|4@0+ (1,0) [0|14] ""  XGW_Info
  SG_ ADAS_BCM_HeadlightReq : 12|1@0+ (1,0) [0|1] ""  XGW_Info
  SG_ ADAS_BCM_FoldMirrorReq : 14|2@0+ (1,0) [0|3] ""  XGW_Info
  SG_ ADAS_BCM_Status : 18|3@0+ (1,0) [0|7] ""  XGW_Info
  SG_ ADAS_BCM_IndicatorlightReq : 23|3@0+ (1,0) [0|7] ""  XGW_Info
  SG_ SECCAN_ADAS_BCM_Sts : 63|8@0+ (1,0) [0|255] ""  XGW_Info

BO_ 531 VCU_POD_reqDCDC: 8 XGW_Info
  SG_ CHSKM_VCU_POD_reqDCDC : 7|8@0+ (1,0) [0|255] "" MHU
  SG_ ALV_VCU_POD_reqDCDC : 11|4@0+ (1,0) [0|14] "" MHU
  SG_ VCU_enableDCDC : 13|2@0+ (1,0) [0|3] "" MHU
  SG_ VCU_vDCDCRequest : 23|16@0+ (0.0625,0) [9|16] "V" MHU
  SG_ VCU_iDCDCRequest_lim : 39|16@0+ (0.0625,0) [0|300] "A" MHU

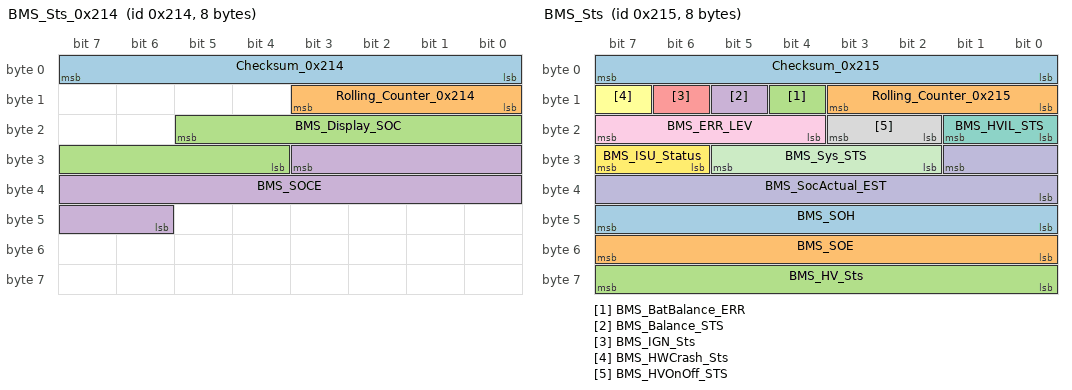
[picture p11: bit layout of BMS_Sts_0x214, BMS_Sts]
BO_ 532 BMS_Sts_0x214: 8 XGW_Info
  SG_ Checksum_0x214 : 7|8@0+ (1,0) [0|255] "" MHU
  SG_ Rolling_Counter_0x214 : 11|4@0+ (1,0) [0|14] "" MHU
  SG_ BMS_Display_SOC : 21|10@0+ (0.1,0) [0|100] "%" MHU
  SG_ BMS_SOCE : 27|14@0+ (0.01,0) [0|100] "%" MHU

BO_ 533 BMS_Sts: 8 XGW_Info
  SG_ Checksum_0x215 : 7|8@0+ (1,0) [0|255] "" HUD,MHU
  SG_ Rolling_Counter_0x215 : 11|4@0+ (1,0) [0|14] "" HUD,MHU
  SG_ BMS_BatBalance_ERR : 12|1@0+ (1,0) [0|1] "" HUD,MHU
  SG_ BMS_Balance_STS : 13|1@0+ (1,0) [0|1] "" HUD,MHU
  SG_ BMS_IGN_Sts : 14|1@0+ (1,0) [0|1] "" HUD,MHU
  SG_ BMS_HWCrash_Sts : 15|1@0+ (1,0) [0|1] "" HUD,MHU
  SG_ BMS_HVIL_STS : 17|2@0+ (1,0) [0|3] "" HUD,MHU
  SG_ BMS_HVOnOff_STS : 19|2@0+ (1,0) [0|3] "" HUD,MHU
  SG_ BMS_ERR_LEV : 23|4@0+ (1,0) [0|7] "-" HUD,MHU
  SG_ BMS_SocActual_EST : 25|10@0+ (0.1,0) [0|100] "%" HUD,MHU
  SG_ BMS_Sys_STS : 29|4@0+ (1,0) [0|15] "" HUD,MHU
  SG_ BMS_ISU_Status : 31|2@0+ (1,0) [0|3] "" HUD,MHU
  SG_ BMS_SOH : 47|8@0+ (0.5,0) [0|100] "%" HUD,MHU
  SG_ BMS_SOE : 55|8@0+ (0.5,0) [0|100] "%" HUD,MHU
  SG_ BMS_HV_Sts : 63|8@0+ (1,0) [0|255] "" HUD,MHU

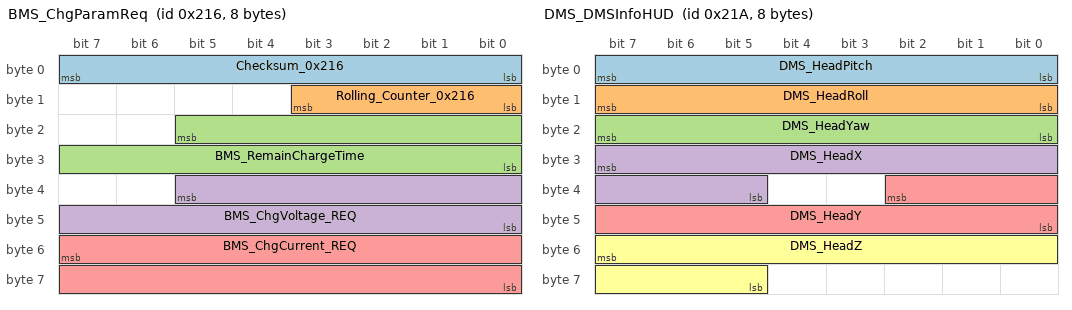
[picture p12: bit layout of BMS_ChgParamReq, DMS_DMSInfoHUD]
BO_ 534 BMS_ChgParamReq: 8 XGW_Info
  SG_ Checksum_0x216 : 7|8@0+ (1,0) [0|255] "" MHU
  SG_ Rolling_Counter_0x216 : 11|4@0+ (1,0) [0|14] "" MHU
  SG_ BMS_RemainChargeTime : 21|14@0+ (1,0) [0|16383] "min" MHU
  SG_ BMS_ChgVoltage_REQ : 37|14@0+ (0.1,0) [0|800] "V" MHU
  SG_ BMS_ChgCurrent_REQ : 55|16@0+ (0.1,0) [0|1500] "A" MHU

BO_ 538 DMS_DMSInfoHUD: 8 MHU
 SG_ DMS_HeadPitch : 7|8@0+ (1,0) [-45|45] "degree"  Vector__XXX
 SG_ DMS_HeadRoll : 15|8@0+ (1,0) [-45|45] "degree"  Vector__XXX
 SG_ DMS_HeadYaw : 23|8@0+ (1,0) [-75|180] "degree"  Vector__XXX
 SG_ DMS_HeadX : 31|11@0+ (1,0) [-500|1547] "mm"  Vector__XXX
 SG_ DMS_HeadY : 34|11@0+ (1,0) [-500|1547] "mm"  Vector__XXX
 SG_ DMS_HeadZ : 55|11@0+ (1,0) [-500|1547] "mm"  Vector__XXX

BO_ 539 BMS_FaultInfo: 8 XGW_Info
 SG_ BMS_faultnumber : 7|64@0+ (1,0) [0|1.84467E+019] ""  MHU

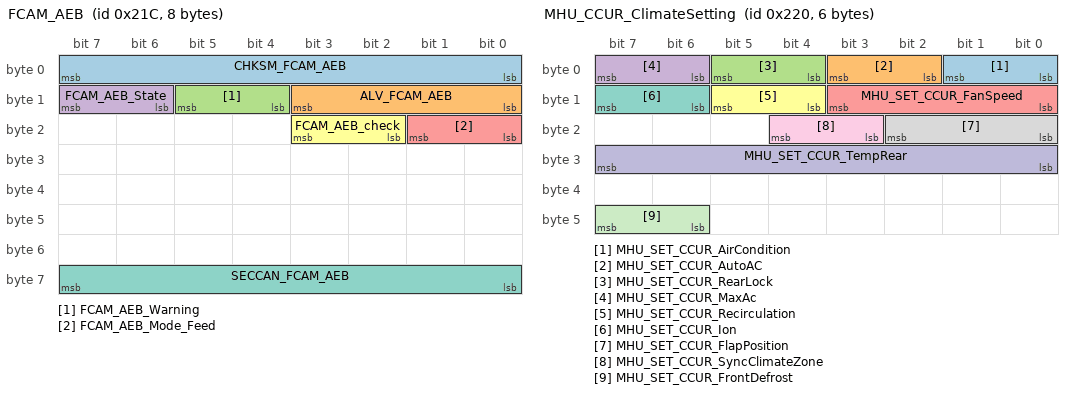
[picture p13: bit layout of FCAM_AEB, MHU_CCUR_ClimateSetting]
BO_ 540 FCAM_AEB: 8 FCAM_Info
 SG_ CHKSM_FCAM_AEB : 7|8@0+ (1,0) [0|255] ""  HUD,MHU
 SG_ ALV_FCAM_AEB : 11|4@0+ (1,0) [0|14] ""  HUD,MHU
 SG_ FCAM_AEB_Warning : 13|2@0+ (1,0) [0|3] ""  HUD,MHU,XGW_Info
 SG_ FCAM_AEB_State : 15|2@0+ (1,0) [0|3] ""  HUD,MHU,PAS_Info,XGW_Info
 SG_ FCAM_AEB_Mode_Feed : 17|2@0+ (1,0) [0|3] ""  HUD,MHU
 SG_ FCAM_AEB_check : 19|2@0+ (1,0) [0|3] ""  HUD,MHU,XGW_Info
 SG_ SECCAN_FCAM_AEB : 63|8@0+ (1,0) [0|255] ""  HUD,MHU

BO_ 544 MHU_CCUR_ClimateSetting: 6 MHU
  SG_ MHU_SET_CCUR_AirCondition : 1|2@0+ (1,0) [0|3] "-" XGW_Info
  SG_ MHU_SET_CCUR_AutoAC : 3|2@0+ (1,0) [0|3] "-" XGW_Info
  SG_ MHU_SET_CCUR_RearLock : 5|2@0+ (1,0) [0|3] "-" XGW_Info
  SG_ MHU_SET_CCUR_MaxAc : 7|2@0+ (1,0) [0|3] "" XGW_Info
  SG_ MHU_SET_CCUR_FanSpeed : 11|4@0+ (1,0) [0|7] "-" XGW_Info
  SG_ MHU_SET_CCUR_Recirculation : 13|2@0+ (1,0) [0|3] "-" XGW_Info
  SG_ MHU_SET_CCUR_Ion : 15|2@0+ (1,0) [0|3] "" XGW_Info
  SG_ MHU_SET_CCUR_FlapPosition : 18|3@0+ (1,0) [0|7] "-" XGW_Info
  SG_ MHU_SET_CCUR_SyncClimateZone : 20|2@0+ (1,0) [0|3] "-" XGW_Info
  SG_ MHU_SET_CCUR_TempRear : 31|8@0+ (0.5,0) [16|32] "Degree C" XGW_Info
  SG_ MHU_SET_CCUR_FrontDefrost : 47|2@0+ (1,0) [0|3] "" XGW_Info

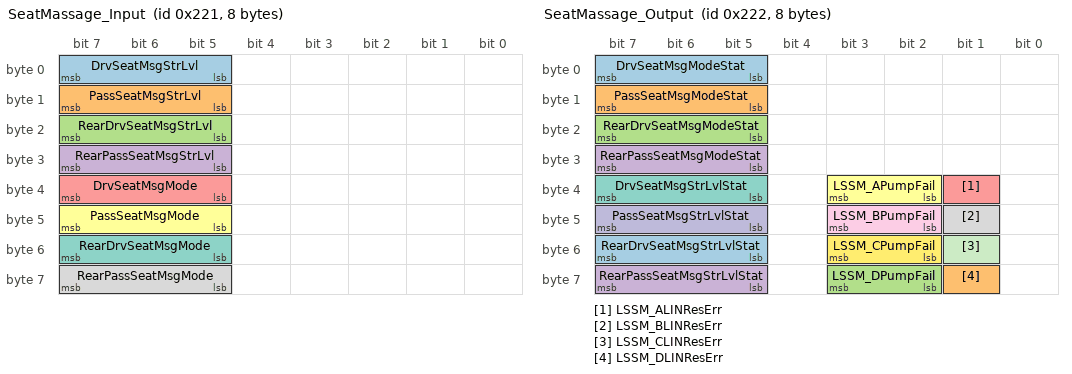
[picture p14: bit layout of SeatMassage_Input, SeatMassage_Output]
BO_ 545 SeatMassage_Input: 8 MHU
  SG_ DrvSeatMsgStrLvl : 7|3@0+ (1,0) [0|7] "" XGW_Info
  SG_ PassSeatMsgStrLvl : 15|3@0+ (1,0) [0|7] "" XGW_Info
  SG_ RearDrvSeatMsgStrLvl : 23|3@0+ (1,0) [0|7] "-" XGW_Info
  SG_ RearPassSeatMsgStrLvl : 31|3@0+ (1,0) [0|7] "" XGW_Info
  SG_ DrvSeatMsgMode : 39|3@0+ (1,0) [0|7] "" XGW_Info
  SG_ PassSeatMsgMode : 47|3@0+ (1,0) [0|7] "" XGW_Info
  SG_ RearDrvSeatMsgMode : 55|3@0+ (1,0) [0|7] "" XGW_Info
  SG_ RearPassSeatMsgMode : 63|3@0+ (1,0) [0|7] "-" XGW_Info

BO_ 546 SeatMassage_Output: 8 XGW_Info
  SG_ DrvSeatMsgModeStat : 7|3@0+ (1,0) [0|7] "" MHU
  SG_ PassSeatMsgModeStat : 15|3@0+ (1,0) [0|7] "" MHU
  SG_ RearDrvSeatMsgModeStat : 23|3@0+ (1,0) [0|7] "" MHU
  SG_ RearPassSeatMsgModeStat : 31|3@0+ (1,0) [0|7] "" MHU
  SG_ LSSM_ALINResErr : 33|1@0+ (1,0) [0|1] "" MHU
  SG_ LSSM_APumpFail : 35|2@0+ (1,0) [0|3] "" MHU
  SG_ DrvSeatMsgStrLvlStat : 39|3@0+ (1,0) [0|7] "" MHU
  SG_ LSSM_BLINResErr : 41|1@0+ (1,0) [0|1] "" MHU
  SG_ LSSM_BPumpFail : 43|2@0+ (1,0) [0|3] "" MHU
  SG_ PassSeatMsgStrLvlStat : 47|3@0+ (1,0) [0|7] "-" MHU
  SG_ LSSM_CLINResErr : 49|1@0+ (1,0) [0|1] "" MHU
  SG_ LSSM_CPumpFail : 51|2@0+ (1,0) [0|3] "-" MHU
  SG_ RearDrvSeatMsgStrLvlStat : 55|3@0+ (1,0) [0|7] "-" MHU
  SG_ LSSM_DLINResErr : 57|1@0+ (1,0) [0|1] "" MHU
  SG_ LSSM_DPumpFail : 59|2@0+ (1,0) [0|3] "-" MHU
  SG_ RearPassSeatMsgStrLvlStat : 63|3@0+ (1,0) [0|7] "" MHU

BO_ 549 BMS_FaultMgr_0x225: 8 XGW_Info
  SG_ Checksum_0x225 : 7|8@0+ (1,0) [0|255] "" MHU
  SG_ Rolling_Counter_0x225 : 11|4@0+ (1,0) [0|14] "" MHU
  SG_ CDM_bAcvCanComStblMon : 12|1@0+ (1,0) [0|1] "" MHU
  SG_ FRMo_bErrHvbatStReqExtMon : 13|1@0+ (1,0) [0|1] "" MHU
  SG_ FRMo_bErrChrgnAllwdExtMon : 14|1@0+ (1,0) [0|1] "" MHU
  SG_ FRMo_bErrVehCrashStExtMon : 15|1@0+ (1,0) [0|1] "" MHU
  SG_ CDM_bErrComctnLossCanMon : 16|1@0+ (1,0) [0|1] "" MHU
  SG_ CTCMon_bErrCtctrSopcMon : 17|1@0+ (1,0) [0|1] "" MHU
  SG_ CTCMon_bInvldCtctrHisdIFbMon : 18|1@0+ (1,0) [0|1] "" MHU
  SG_ CTCMon_bInvldCtctrLosdUFbMon : 19|1@0+ (1,0) [0|1] "" MHU
  SG_ CTM_bErrCellTDifMaxMon : 20|1@0+ (1,0) [0|1] "" MHU
  SG_ CTM_bErrCellTMaxMon : 21|1@0+ (1,0) [0|1] "" MHU
  SG_ CTM_bErrCellTMinMon : 22|1@0+ (1,0) [0|1] "" MHU
  SG_ CTM_bErrThrwyPredMon : 23|1@0+ (1,0) [0|1] "" MHU
  SG_ CUM_bErrCellUDifMaxMon : 24|1@0+ (1,0) [0|1] "" MHU
  SG_ CUM_bErrCellUMaxMon : 25|1@0+ (1,0) [0|1] "" MHU
  SG_ CUM_bErrCellUMinMon : 26|1@0+ (1,0) [0|1] "" MHU
  SG_ CUM_bErrCellUProtnMaxNvMon : 27|1@0+ (1,0) [0|1] "" MHU
  SG_ CUM_bErrCellUProtnMinNvMon : 28|1@0+ (1,0) [0|1] "" MHU
  SG_ CUM_bErrPackUImplyMon : 29|1@0+ (1,0) [0|1] "" MHU
  SG_ EHPMon_bRdyHvilMon : 30|1@0+ (1,0) [0|1] "" MHU
  SG_ EHPMon_bErrWlddNegNvMon : 31|1@0+ (1,0) [0|1] "" MHU
  SG_ EHPMon_bErrWlddPosNvMon : 32|1@0+ (1,0) [0|1] "" MHU
  SG_ EHPMon_bErrWlddPrechNvMon : 33|1@0+ (1,0) [0|1] "" MHU
  SG_ EHPMon_bErrHvilMon : 34|1@0+ (1,0) [0|1] "" MHU
  SG_ EHPMon_bErrHvilShoMon : 35|1@0+ (1,0) [0|1] "" MHU
  SG_ EHPMon_bErrPackIslnRNvMon : 36|1@0+ (1,0) [0|1] "" MHU
  SG_ EHPMon_bErrVehCrashNvMon : 37|1@0+ (1,0) [0|1] "" MHU
  SG_ EHPMon_bErrVehIslnRNvMon : 38|1@0+ (1,0) [0|1] "" MHU
  SG_ FRMo_bErrMemStorgNvMon : 39|1@0+ (1,0) [0|1] "" MHU
  SG_ L1IM_bErrClmp30MaxMonInp : 40|1@0+ (1,0) [0|1] "" MHU
  SG_ L1IM_bErrClmp30MinMonInp : 41|1@0+ (1,0) [0|1] "" MHU
  SG_ L1IM_bErrCtctrDtrtMonInp : 42|1@0+ (1,0) [0|1] "" MHU
  SG_ L1IM_bErrUActImplyMonInp : 43|1@0+ (1,0) [0|1] "" MHU
  SG_ MCCM_bAcvMdulCtlrStsMon : 44|1@0+ (1,0) [0|1] "" MHU
  SG_ MCCM_bErrLntecSngFltMon : 45|1@0+ (1,0) [0|1] "" MHU
  SG_ MCCM_bErrLntecLtntFltMon : 46|1@0+ (1,0) [0|1] "" MHU
  SG_ MCCM_bErrMdulCellSnsrCfgMon : 47|1@0+ (1,0) [0|1] "" MHU
  SG_ MCCM_bErrMdulCtlrComMon : 48|1@0+ (1,0) [0|1] "" MHU
  SG_ MCCM_bErrSnsrTEltlMon : 49|1@0+ (1,0) [0|1] "" MHU
  SG_ MCCM_bWarnSnsrTEltlMon : 50|1@0+ (1,0) [0|1] "" MHU
  SG_ PCM_bRdySnsrIMon : 51|1@0+ (1,0) [0|1] "" MHU
  SG_ PCM_bErrPackEFlowMaxLimMon : 52|1@0+ (1,0) [0|1] "" MHU
  SG_ PCM_bErrPackIChDchaMaxLimMon : 53|1@0+ (1,0) [0|1] "" MHU
  SG_ PCM_bErrSnsrIImplyMon : 54|1@0+ (1,0) [0|1] "" MHU
  SG_ FRMo_bErrSnsrI1ExtMon : 55|1@0+ (1,0) [0|1] "" MHU
  SG_ PCM_bInvldSnsrI1Mon : 56|1@0+ (1,0) [0|1] "" MHU
  SG_ PCM_bInvldSnsrI2Mon : 57|1@0+ (1,0) [0|1] "" MHU
  SG_ FRMo_bErrSopcLvl3Mon : 58|1@0+ (1,0) [0|1] "" MHU
  SG_ BMS_FRMo_Reserved_1 : 59|1@0+ (1,0) [0|1] "" MHU
  SG_ BMS_FRMo_Reserved_2 : 60|1@0+ (1,0) [0|1] "" MHU
  SG_ BMS_FRMo_Reserved_3 : 61|1@0+ (1,0) [0|1] "" MHU
  SG_ BMS_FRMo_Reserved_4 : 62|1@0+ (1,0) [0|1] "" MHU
  SG_ BMS_FRMo_Reserved_5 : 63|1@0+ (1,0) [0|1] "" MHU

BO_ 561 DoorFLStatus: 8 XGW_Info
  SG_ NDoorFLOutsideHandleFailure : 26|3@0+ (1,0) [0|7] "" MHU
  SG_ NDoorLatchFLFailure : 55|6@0+ (1,0) [0|63] "" MHU

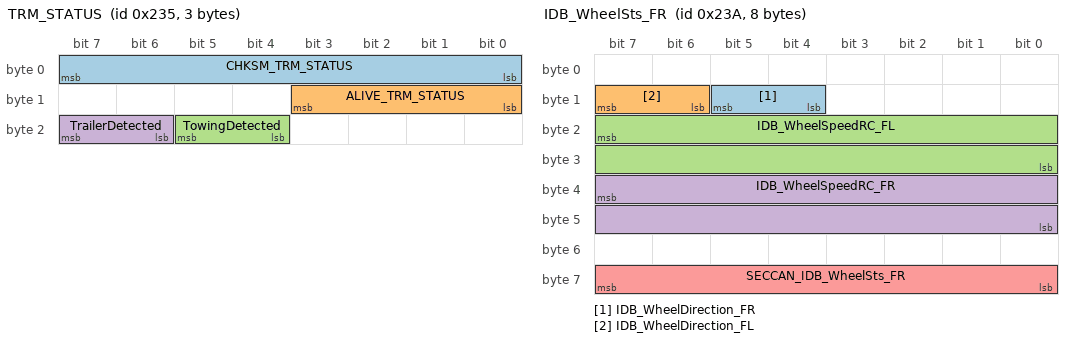
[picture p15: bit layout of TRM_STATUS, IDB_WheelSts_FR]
BO_ 565 TRM_STATUS: 3 XGW_Info
  SG_ CHKSM_TRM_STATUS : 7|8@0+ (1,0) [0|255] "" HUD,MHU,PAS_Info,FCAM_Info,PAS_LITE
  SG_ ALIVE_TRM_STATUS : 11|4@0+ (1,0) [0|14] "" HUD,MHU,PAS_Info,FCAM_Info,PAS_LITE
  SG_ TowingDetected : 21|2@0+ (1,0) [0|3] "" HUD,MHU,PAS_Info,FCAM_Info,PAS_LITE
  SG_ TrailerDetected : 23|2@0+ (1,0) [0|3] "" HUD,MHU,PAS_Info,FCAM_Info,PAS_LITE

BO_ 569 DoorRRStatus: 8 XGW_Info
  SG_ NDoorRROutsideHandleFailure : 26|3@0+ (1,0) [0|7] "" MHU
  SG_ NDoorLatchRRFailure : 55|6@0+ (1,0) [0|63] "" MHU

BO_ 570 IDB_WheelSts_FR: 8 XGW_Info
 SG_ IDB_WheelDirection_FR : 13|2@0+ (1,0) [0|3] ""  PAS_LITE
 SG_ IDB_WheelDirection_FL : 15|2@0+ (1,0) [0|3] ""  PAS_LITE
 SG_ IDB_WheelSpeedRC_FL : 23|16@0+ (1,0) [0|65534] ""  PAS_LITE
 SG_ IDB_WheelSpeedRC_FR : 39|16@0+ (1,0) [0|65534] ""  PAS_LITE
 SG_ SECCAN_IDB_WheelSts_FR : 63|8@0+ (1,0) [0|255] ""  Vector__XXX

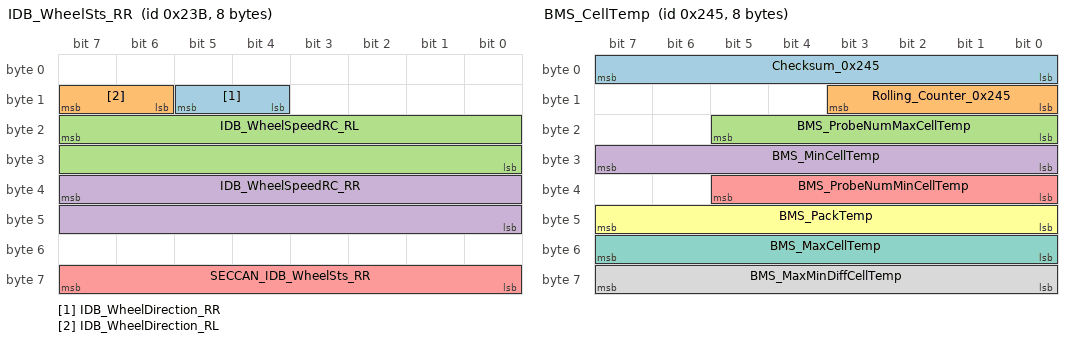
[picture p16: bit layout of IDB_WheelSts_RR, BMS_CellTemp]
BO_ 571 IDB_WheelSts_RR: 8 XGW_Info
 SG_ IDB_WheelDirection_RR : 13|2@0+ (1,0) [0|3] ""  PAS_LITE
 SG_ IDB_WheelDirection_RL : 15|2@0+ (1,0) [0|3] ""  PAS_LITE
 SG_ IDB_WheelSpeedRC_RL : 23|16@0+ (1,0) [0|65534] ""  PAS_LITE
 SG_ IDB_WheelSpeedRC_RR : 39|16@0+ (1,0) [0|65534] ""  PAS_LITE
 SG_ SECCAN_IDB_WheelSts_RR : 63|8@0+ (1,0) [0|255] ""  Vector__XXX

BO_ 581 BMS_CellTemp: 8 XGW_Info
  SG_ Checksum_0x245 : 7|8@0+ (1,0) [0|255] "" MHU
  SG_ Rolling_Counter_0x245 : 11|4@0+ (1,0) [0|14] "" MHU
  SG_ BMS_ProbeNumMaxCellTemp : 21|6@0+ (1,0) [0|63] "" MHU
  SG_ BMS_MinCellTemp : 31|8@0+ (1,-40) [-40|215] "°C" MHU
  SG_ BMS_ProbeNumMinCellTemp : 37|6@0+ (1,0) [0|63] "" MHU
  SG_ BMS_PackTemp : 47|8@0+ (1,-40) [-40|215] "°C" MHU
  SG_ BMS_MaxCellTemp : 55|8@0+ (1,-40) [-40|215] "°C" MHU
  SG_ BMS_MaxMinDiffCellTemp : 63|8@0+ (1,-40) [-40|215] "°C" MHU

BO_ 584 DoorFRStatus: 8 XGW_Info
  SG_ NDoorFROutsideHandleFailure : 26|3@0+ (1,0) [0|7] "" MHU
  SG_ NDoorLatchFRFailure : 55|6@0+ (1,0) [0|63] "" MHU

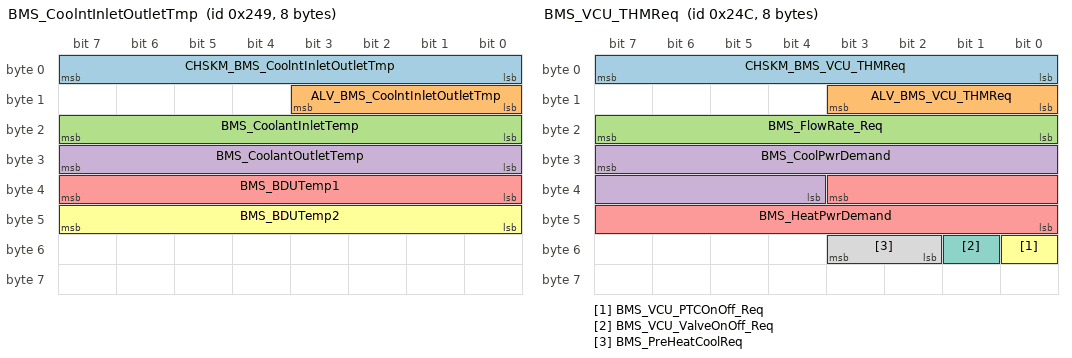
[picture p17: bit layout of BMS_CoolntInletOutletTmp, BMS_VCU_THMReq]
BO_ 585 BMS_CoolntInletOutletTmp: 8 XGW_Info
  SG_ CHSKM_BMS_CoolntInletOutletTmp : 7|8@0+ (1,0) [0|255] "" MHU
  SG_ ALV_BMS_CoolntInletOutletTmp : 11|4@0+ (1,0) [0|14] "" MHU
  SG_ BMS_CoolantInletTemp : 23|8@0+ (1,-40) [-40|215] "°C" MHU
  SG_ BMS_CoolantOutletTemp : 31|8@0+ (1,-40) [-40|215] "°C" MHU
  SG_ BMS_BDUTemp1 : 39|8@0+ (1,-40) [-40|215] "°C" MHU
  SG_ BMS_BDUTemp2 : 47|8@0+ (1,-40) [-40|215] "°C" Vector__XXX

BO_ 588 BMS_VCU_THMReq: 8 XGW_Info
  SG_ CHSKM_BMS_VCU_THMReq : 7|8@0+ (1,0) [0|255] "" MHU
  SG_ ALV_BMS_VCU_THMReq : 11|4@0+ (1,0) [0|14] "" MHU
  SG_ BMS_FlowRate_Req : 23|8@0+ (1,0) [0|50] "l/min"  Vector__XXX
  SG_ BMS_CoolPwrDemand : 31|12@0+ (0.1,0) [0|10] "kW" MHU
  SG_ BMS_HeatPwrDemand : 35|12@0+ (0.1,0) [0|10] "kW"  Vector__XXX
  SG_ BMS_VCU_PTCOnOff_Req : 48|1@0+ (1,0) [0|1] ""  Vector__XXX
  SG_ BMS_VCU_ValveOnOff_Req : 49|1@0+ (1,0) [0|1] ""  Vector__XXX
  SG_ BMS_PreHeatCoolReq : 51|2@0+ (1,0) [0|3] "" MHU

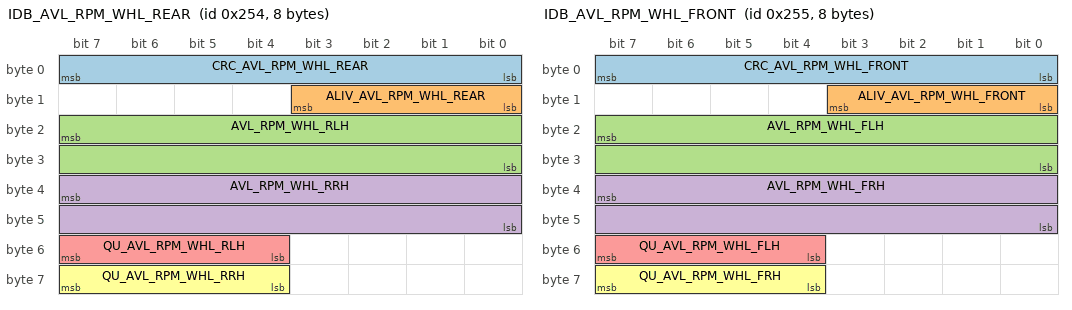
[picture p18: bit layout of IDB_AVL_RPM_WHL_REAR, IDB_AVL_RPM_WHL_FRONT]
BO_ 596 IDB_AVL_RPM_WHL_REAR: 8 XGW_Info
  SG_ CRC_AVL_RPM_WHL_REAR : 7|8@0+ (1,0) [0|255] "" MHU,PAS_LITE
  SG_ ALIV_AVL_RPM_WHL_REAR : 11|4@0+ (1,0) [0|14] "" MHU,PAS_LITE
  SG_ AVL_RPM_WHL_RLH : 23|16@0+ (0.0156,-511.9844) [-400|400] "rad/s" MHU
  SG_ AVL_RPM_WHL_RRH : 39|16@0+ (0.0156,-511.9844) [-400|400] "rad/s" MHU
  SG_ QU_AVL_RPM_WHL_RLH : 55|4@0+ (1,0) [0|15] "Bit" MHU,PAS_LITE
  SG_ QU_AVL_RPM_WHL_RRH : 63|4@0+ (1,0) [0|15] "Bit" MHU,PAS_LITE

BO_ 597 IDB_AVL_RPM_WHL_FRONT: 8 XGW_Info
  SG_ CRC_AVL_RPM_WHL_FRONT : 7|8@0+ (1,0) [0|255] "" MHU,PAS_LITE
  SG_ ALIV_AVL_RPM_WHL_FRONT : 11|4@0+ (1,0) [0|14] "" MHU,PAS_LITE
  SG_ AVL_RPM_WHL_FLH : 23|16@0+ (0.0156,-511.9844) [-400|400] "rad/s" MHU
  SG_ AVL_RPM_WHL_FRH : 39|16@0+ (0.0156,-511.9844) [-400|400] "rad/s" MHU
  SG_ QU_AVL_RPM_WHL_FLH : 55|4@0+ (1,0) [0|15] "Bit" MHU,PAS_LITE
  SG_ QU_AVL_RPM_WHL_FRH : 63|4@0+ (1,0) [0|15] "Bit" MHU,PAS_LITE

BO_ 620 HU_MEBSet_SecOC1: 8 MHU
 SG_ HU_PASDirSel : 15|4@0+ (1,0) [0|15] ""  PAS_Info
 SG_ HU_AutPrkgSlotSel : 18|3@0+ (1,0) [0|7] ""  PAS_Info

BO_ 640 ANRC_PSDisRi02: 8 PAS_Info
 SG_ ANRC_PrkgRiSlotDst2_Y : 7|12@0+ (1,-2047) [-2047|2047] "cm"  MHU
 SG_ ANRC_PrkgRiSlot2_VehAngal : 8|9@0+ (1,0) [0|511] "degree"  MHU
 SG_ ANRC_PrkgRiSlotDst2_X : 31|12@0+ (1,-2047) [-2047|2047] "cm"  MHU

BO_ 641 DoorRLStatus: 8 XGW_Info
  SG_ NDoorRLOutsideHandleFailure : 26|3@0+ (1,0) [0|7] "" MHU
  SG_ NDoorLatchRLFailure : 55|6@0+ (1,0) [0|63] "" MHU

BO_ 642 ANRC_PSDisLe01: 8 PAS_Info
 SG_ ANRC_PrkgLeSlotDst1_Y : 7|12@0+ (1,-2047) [-2047|2047] "cm"  MHU
 SG_ ANRC_PrkgLeSlot1_VehAngal : 8|9@0+ (1,0) [0|511] "degree"  MHU
 SG_ ANRC_PrkgLeSlotDst1_X : 31|12@0+ (1,-2047) [-2047|2047] "cm"  MHU

BO_ 643 ANRC_PSDisLe02: 8 PAS_Info
 SG_ ANRC_PrkgLeSlotDst2_Y : 7|12@0+ (1,-2047) [-2047|2047] "cm"  MHU
 SG_ ANRC_PrkgLeSlot2_VehAngal : 8|9@0+ (1,0) [0|511] "degree"  MHU
 SG_ ANRC_PrkgLeSlotDst2_X : 31|12@0+ (1,-2047) [-2047|2047] "cm"  MHU

BO_ 644 ANRC_PSDisRi03: 8 PAS_Info
 SG_ ANRC_PrkgRiSlotDst3_Y : 7|12@0+ (1,-2047) [-2047|2047] "cm"  MHU
 SG_ ANRC_PrkgRiSlot3_VehAngal : 8|9@0+ (1,0) [0|511] "degree"  MHU
 SG_ ANRC_PrkgRiSlotDst3_X : 31|12@0+ (1,-2047) [-2047|2047] "cm"  MHU

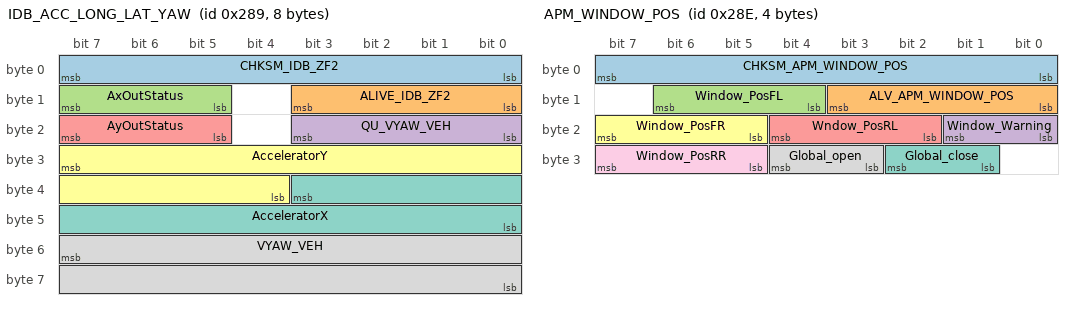
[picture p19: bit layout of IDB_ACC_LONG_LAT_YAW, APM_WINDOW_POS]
BO_ 649 IDB_ACC_LONG_LAT_YAW: 8 XGW_Info
 SG_ CHKSM_IDB_ZF2 : 7|8@0+ (1,0) [0|255] ""  MHU
 SG_ ALIVE_IDB_ZF2 : 11|4@0+ (1,0) [0|14] ""  MHU
 SG_ AxOutStatus : 15|3@0+ (1,0) [0|7] ""  MHU
 SG_ QU_VYAW_VEH : 19|4@0+ (1,0) [0|15] ""  Vector__XXX
 SG_ AyOutStatus : 23|3@0+ (1,0) [0|7] ""  MHU
 SG_ AcceleratorY : 31|12@0+ (0.02713,-21.5928) [-21.593|21.5928] "m/s²"  MHU
 SG_ AcceleratorX : 35|12@0+ (0.02713,-21.5928) [-21.593|21.5928] "m/s²"  MHU
 SG_ VYAW_VEH : 55|16@0+ (0.005,-163.84) [-163.84|163.83] "°/s"  MHU

BO_ 654 APM_WINDOW_POS: 4 XGW_Info
  SG_ CHKSM_APM_WINDOW_POS : 7|8@0+ (1,0) [0|255] "" CPD,MHU
  SG_ ALV_APM_WINDOW_POS : 11|4@0+ (1,0) [0|14] "" CPD,MHU
  SG_ Window_PosFL : 14|3@0+ (1,0) [0|7] "-" CPD,MHU
  SG_ Window_Warning : 17|2@0+ (1,0) [0|3] "" CPD,MHU
  SG_ Wndow_PosRL : 20|3@0+ (1,0) [0|7] "" CPD,MHU
  SG_ Window_PosFR : 23|3@0+ (1,0) [0|7] "" CPD,MHU
  SG_ Global_close : 26|2@0+ (1,0) [0|3] "" CPD,MHU
  SG_ Global_open : 28|2@0+ (1,0) [0|3] "" CPD,MHU
  SG_ Window_PosRR : 31|3@0+ (1,0) [0|7] "-" CPD,MHU

CM_ BO_ 400 "CAM_Status";
CM_ BO_ 401 "CAM Obj 1";
CM_ BO_ 404 "CAM_Obj2";
CM_ BO_ 406 "CAM_Obj3";
CM_ BO_ 409 "VCU Status 1";
CM_ BO_ 410 "CAM_Obj4";
CM_ BO_ 412 "CAM_Obj5";
CM_ BO_ 413 "CAM_Obj6";
CM_ BO_ 414 "CAM_Obj7";
CM_ BO_ 415 "CAM_Obj8";
CM_ BO_ 417 "Vehicle speed";
CM_ BO_ 504 "MCU OutPut FR";
CM_ BO_ 505 "MCU OutPut RR";
CM_ BO_ 506 "MHU Driver info signals";
CM_ BO_ 515 "Camera right lane signals";
CM_ BO_ 516 "Camera Left lane signals";
CM_ BO_ 517 "BMS detail voltage 1";
CM_ BO_ 518 "ADAS_ELK";
CM_ BO_ 519 "Sunroof status";
CM_ BO_ 520 "Sunshade status";
CM_ BO_ 522 "Rear Lift Gate Status";
CM_ BO_ 523 "Foot Kick Senor Status";
CM_ BO_ 524 "IC ODO";
CM_ BO_ 525 "IDB status";
CM_ BO_ 531 "VCU Command";
CM_ BO_ 533 "BMS status";
CM_ BO_ 534 "BMS Charging profile";
CM_ BO_ 544 "MHU Climate Setting";
CM_ BO_ 545 "Drv Seat massage";
CM_ BO_ 546 "Drv Seat Mode Massage";
CM_ BO_ 549 "BMS Fault Management";
CM_ BO_ 561 "Door Front Latch Status";
CM_ BO_ 565 "Trailer Status";
CM_ BO_ 569 "Door Front Right Latch Status";
CM_ BO_ 570 "IDB Front Wheel Status";
CM_ BO_ 571 "IDB Rear Wheel Status";
CM_ BO_ 581 "BMS Temperature";
CM_ BO_ 584 "Door Front Right Latch Status";
CM_ BO_ 585 "BMS Coolant water temperature";
CM_ BO_ 588 "BMS thermal request";
CM_ BO_ 596 "Wheel Speed Rear";
CM_ BO_ 597 "Wheel Speed Front";
CM_ BO_ 641 "Door Front Right Latch Status";
CM_ BO_ 649 "Acc Long Lat yaw";
CM_ BO_ 654 "APM window position";
CM_ SG_ 387 VCU_FS_B_1 "L2 Rear EDS power off request Confirmed Error";
CM_ SG_ 387 VCU_FS_B_2 "L2 Front EDS HVIL Status Confirmed Error during driving";
CM_ SG_ 387 VCU_FS_B_3 "L2 Front EDS HVIL Status Confirmed Error during charging";
CM_ SG_ 387 VCU_FS_B_4 "L2 Front EDS HVIL Status Confirmed Error during standstill";
CM_ SG_ 387 VCU_FS_B_5 "L2 Rear EDS HVIL Status Confirmed Error during driving";
CM_ SG_ 387 VCU_FS_B_6 "L2 Rear EDS HVIL Status Confirmed Error during charging";
CM_ SG_ 387 VCU_FS_B_7 "L2 Rear EDS HVIL Status Confirmed Error during standstill";
CM_ SG_ 387 VCU_FS_B_8 "L2 Front EDS Discharge Status Confirmed Error";
CM_ SG_ 387 VCU_FS_B_9 "L2 Rear EDS Discharge Status Confirmed Error";
CM_ SG_ 387 VCU_FS_B_10 "L2 Front EDS FuSa and Epark Status Confirmed Error";
CM_ SG_ 387 VCU_FS_B_11 "L2 Rear EDS FuSa and Epark Status Confirmed Error";
CM_ SG_ 387 VCU_FS_B_12 "L2 Front EDS FuSa and Epark Confirmed Error";
CM_ SG_ 387 VCU_FS_B_13 "L2 Rear EDS FuSa and Epark Confirmed Error";
CM_ SG_ 387 VCU_FS_B_14 "L2 Front EDS Epark confirmed error";
CM_ SG_ 387 VCU_FS_B_15 "L2 Rear EDS Epark confirmed error";
CM_ SG_ 387 VCU_FS_B_16 "L2 DCDC Output Voltage Confirmed Error";
CM_ SG_ 387 VCU_FS_B_17 "L2 DCDC Output Current Confirmed Error";
CM_ SG_ 387 VCU_FS_B_18 "L2 BMS Battery Voltage or Current Request Error During AC Charging Confirmed Error";
CM_ SG_ 387 VCU_FS_B_19 "L2 BMS Battery Voltage or Current Request Error During DC Charging Confirmed Error";
CM_ SG_ 387 VCU_FS_B_20 "L2 Front EDS Fail Grade Error 5 confirmed error";
CM_ SG_ 387 VCU_FS_B_21 "L2 Rear EDS Fail Grade Error 5 confirmed error";
CM_ SG_ 387 VCU_FS_B_22 "L2 AWD - Front EDS Fail Grade Error 4 confirmed error";
CM_ SG_ 387 VCU_FS_B_23 "L2 AWD - Rear EDS Fail Grade Error 4 confirmed error";
CM_ SG_ 387 VCU_FS_B_24 "L2 FWD EDS Fail Grade Error 4 confirmed error";
CM_ SG_ 387 VCU_FS_B_25 "L2 RWD EDS Fail Grade Error 4 confirmed error";
CM_ SG_ 387 VCU_FS_B_26 "L2 Front EDS Fail Grade Error 4 with ASC confirmed error";
CM_ SG_ 387 VCU_FS_B_27 "L2 Rear EDS Fail Grade Error 4 with ASC confirmed error";
CM_ SG_ 387 VCU_FS_B_28 "L2 Front EDS Fail Grade Error 4 confirmed error";
CM_ SG_ 387 VCU_FS_B_29 "L2 Rear EDS Fail Grade Error 4 confirmed error";
CM_ SG_ 387 VCU_FS_B_30 "L2 Front EDS Fail Grade or FuSa Error  confirmed error";
CM_ SG_ 387 VCU_FS_B_31 "L2 Rear EDS Fail Grade or FuSa Error  confirmed error";
CM_ SG_ 387 VCU_FS_B_32 "L2 BMS status confirmed error";
CM_ SG_ 387 VCU_FS_B_33 "L2 HV Power Monitoring confirmed error";
CM_ SG_ 387 VCU_FS_B_34 "L2 OBC Status confirmed error";
CM_ SG_ 387 VCU_FS_B_35 "L2 DCDC Fault confirmed error";
CM_ SG_ 387 VCU_FS_B_36 "L2 Invalid OBC status confirmed error";
CM_ SG_ 387 VCU_FS_B_37 "L2 Invalid OBC charger values confirmed error";
CM_ SG_ 387 VCU_FS_B_38 "L2 OBC Error level 3 charging confirmed error";
CM_ SG_ 387 VCU_FS_B_39 "L2 OBC Error level 4 charging confirmed error";
CM_ SG_ 387 VCU_FS_B_40 "L2 OBC Error level 5 charging confirmed error";
CM_ SG_ 387 VCU_FS_B_41 "L2 DCDC Error level 4 charging confirmed error";
CM_ SG_ 387 VCU_FS_B_42 "L2 DCDC Error level 5 charging confirmed error";
CM_ SG_ 387 VCU_FS_B_43 "L2 Fast Charge Contactor Welded Status Confirmed Error";
CM_ SG_ 387 VCU_FS_B_44 "L2 Fast Charge Contactor Not Available Status Confirmed Error";
CM_ SG_ 387 VCU_FS_B_45 "L2 Invalid DC Contactor Status Confirmed Error";
CM_ SG_ 387 VCU_FS_B_46 "L2 BMS maximum allowable charging current Confirmed Error during AC charging";
CM_ SG_ 387 VCU_FS_B_47 "L2 BMS maximum allowable charging current Confirmed Error during DC charging";
CM_ SG_ 387 VCU_FS_B_48 "L2 BMS maximum allowable charging current Confirmed Error during driving";
CM_ SG_ 387 VCU_FS_B_49 "L2 BMS System Status Confirmed Error during stationary";
CM_ SG_ 387 VCU_FS_B_50 "L2 BMS System Status Confirmed Error during driving";
CM_ SG_ 387 VCU_FS_B_51 "L2 BMS Error Message Confirmed Error during stationary";
CM_ SG_ 387 VCU_FS_B_52 "L2 BMS Error Message Confirmed Error during driving";
CM_ SG_ 387 VCU_FS_B_53 "L2 BMS System Status Confirmed Error during AC charging";
CM_ SG_ 387 VCU_FS_B_54 "L2 BMS System Status Confirmed Error during DC charging";
CM_ SG_ 387 VCU_FS_B_55 "L2 BMS Error Message Confirmed Error during AC charging";
CM_ SG_ 387 VCU_FS_B_56 "L2 BMS Error Message Confirmed Error during DC charging";
CM_ SG_ 387 VCU_FS_B_57 "L2 BMS System Status and Error Message Confirmed Error";
CM_ SG_ 387 VCU_FS_B_58 "L2 DCDC status 6 confirmed error";
CM_ SG_ 387 VCU_FS_B_59 "L2 DCDC status 5 confirmed error";
CM_ SG_ 387 VCU_FS_B_60 "L2 OBC status 6 confirmed error";
CM_ SG_ 387 VCU_FS_B_61 "L2 OBC status 5 confirmed error";
CM_ SG_ 387 VCU_FS_B_62 "L2 OBC status 4 confirmed error";
CM_ SG_ 387 VCU_FS_B_63 "L2 Accelerator pedal sensor 1 and 2 ADC confirmed error";
CM_ SG_ 387 VCU_FS_B_64 "L2 AC charge gun connection confirmed error";
CM_ SG_ 388 CHKSM_FCAM_BCM_Status "Checksum";
CM_ SG_ 388 ALIVE_FCAM_BCM_Status "Alive counter";
CM_ SG_ 388 FCAM_BCM_IndicatorlightReq "FCAM request BCM to light up these light";
CM_ SG_ 388 SECCAN_FCAM_BCM_Sts "Seed generated from Secure CAN algorithm";
CM_ SG_ 389 VCU_FS_C_1 "L2 DC charge gun connection confirmed error";
CM_ SG_ 389 VCU_FS_C_2 "L2 Cruise control activation confirmed error";
CM_ SG_ 389 VCU_FS_C_3 "L2 BCM door status invalid confirmed error";
CM_ SG_ 389 VCU_FS_C_4 "L2 MHU EV Settings confirmed error during driving";
CM_ SG_ 389 VCU_FS_C_5 "L2 MHU EV Settings confirmed error during charging";
CM_ SG_ 389 VCU_FS_C_6 "L2 Key invalid status confirmed error";
CM_ SG_ 389 VCU_FS_C_7 "L2 ESC Longitudinal acceleration invalid confirmed error";
CM_ SG_ 389 VCU_FS_C_8 "L2 Accelerator pedal sensors creep confirmed error";
CM_ SG_ 389 VCU_FS_C_9 "L2 Invalid BCM battery voltage confirmed error";
CM_ SG_ 389 VCU_FS_C_10 "L2 Below threshold BCM battery voltage confirmed error";
CM_ SG_ 389 VCU_FS_C_11 "L2 Powertrain Activation Comparison Confirmed Error during driving";
CM_ SG_ 389 VCU_FS_C_12 "L2 Front EDS Invalid HVIL status Confirmed Error during driving";
CM_ SG_ 389 VCU_FS_C_13 "L2 Front EDS Invalid HVIL status Confirmed Error during charging";
CM_ SG_ 389 VCU_FS_C_14 "L2 Front EDS Invalid HVIL status Confirmed Error during stationary";
CM_ SG_ 389 VCU_FS_C_15 "L2 Rear EDS Invalid HVIL status Confirmed Error during driving";
CM_ SG_ 389 VCU_FS_C_16 "L2 Rear EDS Invalid HVIL status Confirmed Error during charging";
CM_ SG_ 389 VCU_FS_C_17 "L2 Rear EDS Invalid HVIL status Confirmed Error during stationary";
CM_ SG_ 389 VCU_FS_C_18 "L2 DCDC invalid output values confirmed error during driving";
CM_ SG_ 389 VCU_FS_C_19 "L2 DCDC invalid output status confirmed error during driving";
CM_ SG_ 389 VCU_FS_C_20 "L2 DCFC Error Level 2 confirmed error";
CM_ SG_ 389 VCU_FS_C_21 "L2 DCFC Error Level 3 confirmed error";
CM_ SG_ 389 VCU_FS_C_22 "L2 EPB Invalid confirmed error";
CM_ SG_ 389 VCU_FS_C_23 "L2 EPB Parking Status Invalid";
CM_ SG_ 389 VCU_FS_C_24 "L2 EDS IGBT Invalid Driving confirmed error";
CM_ SG_ 389 VCU_FS_C_25 "L2 EDS IGBT Invalid confirmed error";
CM_ SG_ 389 VCU_FS_C_26 "L2 Vehicle Speed Invalid confirmed error";
CM_ SG_ 389 VCU_FS_C_27 "L2 Regen brake Invalid confirmed error";
CM_ SG_ 389 VCU_FS_C_28 "L2 Regen brake torque request confirmed error";
CM_ SG_ 389 VCU_FS_C_29 "L2 DCDC disable request comparison confirmed error";
CM_ SG_ 389 VCU_FS_C_30 "L2 DCDC not available status confirmed error";
CM_ SG_ 389 VCU_FS_C_31 "L2 DCDC enable request comparison confirmed error";
CM_ SG_ 389 VCU_FS_C_32 "L2 ESC torque intervention increase confirmed error";
CM_ SG_ 389 VCU_FS_C_33 "L2 ESC torque intervention decrease confirmed error";
CM_ SG_ 389 VCU_FS_C_34 "L2 IDB torque request increase stat confirmed error";
CM_ SG_ 389 VCU_FS_C_35 "L2 IDB torque request decrease drv confirmed error";
CM_ SG_ 389 VCU_FS_C_36 "L2 accelerator pedal sensor 1 intermittent confirmed error";
CM_ SG_ 389 VCU_FS_C_37 "L2 accelerator pedal sensor 2 intermittent confirmed error";
CM_ SG_ 389 VCU_FS_C_38 "L2 DCDC status comparison confirmed error";
CM_ SG_ 389 VCU_FS_C_39 "L2 ADAS - RP mode invalid message confirmed error";
CM_ SG_ 389 VCU_FS_C_40 "L2 Front EDS motor status confirmed error";
CM_ SG_ 389 VCU_FS_C_41 "L2 Rear EDS motor status confirmed error";
CM_ SG_ 389 VCU_FS_C_42 "L2 crash detection confirmed error during charging";
CM_ SG_ 389 VCU_FS_C_43 "L2 crash invalid status confirmed error";
CM_ SG_ 389 VCU_FS_C_44 "L2 DCDC error level failed confirmed error";
CM_ SG_ 389 VCU_FS_C_45 "L2 OBC error level failed confirmed error";
CM_ SG_ 389 VCU_FS_C_46 "L2 DCFC error level failed confirmed error";
CM_ SG_ 389 VCU_FS_C_47 "L2 Spare 1";
CM_ SG_ 389 VCU_FS_C_48 "L2 Spare 2";
CM_ SG_ 389 VCU_FS_C_49 "L2 Spare 3";
CM_ SG_ 389 VCU_FS_C_50 "L2 Spare 4";
CM_ SG_ 389 VCU_FS_C_51 "L2 Spare 5";
CM_ SG_ 389 VCU_FS_C_52 "L2 Spare 6";
CM_ SG_ 389 VCU_FS_C_53 "L2 Spare 7";
CM_ SG_ 389 VCU_FS_C_54 "L2 Spare 8";
CM_ SG_ 389 VCU_FS_C_55 "L2 Spare 9";
CM_ SG_ 389 VCU_FS_C_56 "L2 Spare 10";
CM_ SG_ 389 VCU_FS_C_57 "L2 Spare 11";
CM_ SG_ 389 VCU_FS_C_58 "L2 Spare 12";
CM_ SG_ 389 VCU_FS_C_59 "L2 Spare 13";
CM_ SG_ 389 VCU_FS_C_60 "L2 Spare 14";
CM_ SG_ 389 VCU_FS_C_61 "L2 Spare 15";
CM_ SG_ 389 VCU_FS_C_62 "L2 Spare 16";
CM_ SG_ 389 VCU_FS_C_63 "L2 Spare 17";
CM_ SG_ 389 VCU_FS_C_64 "L2 Spare 18";
CM_ SG_ 400 CAM_CamSts "Camera Status ";
CM_ SG_ 400 CAM_AmbLi "Ambient brightness";
CM_ SG_ 400 CAM_RoadIllmn "Road lamp detection";
CM_ SG_ 400 CAM_Obj_TrfcStyle "Traffic type ";
CM_ SG_ 401 CAM_Obj1_ID "ID of object 1
Light object ID. Range is 1-255, while 0 indicates that the field in unfilled.";
CM_ SG_ 401 CAM_Obj1_HozlDst "Horizontal distance in X axis direction  of object 1
0x000-0x1FE: valid
0x1FF: NotAvailable";
CM_ SG_ 401 CAM_Obj1_Valid "Valid of object 1";
CM_ SG_ 401 CAM_Obj1_HozlPosnRi "Horizontal right edge of object 1
0x000-0x3E8: valid
0x3E9-0x3FD: Reserved
0x3FF: NotAvailable";
CM_ SG_ 401 CAM_Obj1_Typ "Type of object 1";
CM_ SG_ 401 CAM_Obj1_HozlPosnLe "Horizontal left edge of object 1
0x000-0x3E8: valid
0x3E9-0x3FD: Reserved
0x3FF: NotAvailable";
CM_ SG_ 401 CAM_Obj1_VertPosn "Vertical lower boundary of object 1
-10 to 10 degree";
CM_ SG_ 401 CAM_Obj1_HozlSpdLe "Horizontal angular velocity of left edge of object 1 (Left��negative and Right positive )
";
CM_ SG_ 401 CAM_Obj1_HozlSpdRi "Horizontal angular velocity of right edge of object 1 (Left��negative and Right positive )
";
CM_ SG_ 404 CAM_Obj2_ID "ID of object 2
Light object ID. Range is 1-255, while 0 indicates that the field in unfilled.";
CM_ SG_ 404 CAM_Obj2_HozlDst "Horizontal distance in X axis direction  of object 2
0x000-0x1FE: valid
0x1FF: NotAvailable";
CM_ SG_ 404 CAM_Obj2_Valid "Valid of object 2";
CM_ SG_ 404 CAM_Obj2_HozlPosnRi "Horizontal right edge of object 2
0x000-0x3E8: valid
0x3E9-0x3FD: Reserved
0x3FF: NotAvailable";
CM_ SG_ 404 CAM_Obj2_Typ "Type of object 2";
CM_ SG_ 404 CAM_Obj2_HozlPosnLe "Horizontal left edge of object 2
0x000-0x3E8: valid
0x3E9-0x3FD: Reserved
0x3FF: NotAvailable";
CM_ SG_ 404 CAM_Obj2_VertPosn "Vertical lower boundary of object  2
-10 to 10 degree";
CM_ SG_ 404 CAM_Obj2_HozlSpdLe "Horizontal angular velocity of left edge of object 2 (Left��negative and Right positive )
";
CM_ SG_ 404 CAM_Obj2_HozlSpdRi "Horizontal angular velocity of right edge of object 2 (Left��negative and Right positive )
";
CM_ SG_ 406 CAM_Obj3_ID "ID of object 3
Light object ID. Range is 1-255, while 0 indicates that the field in unfilled.";
CM_ SG_ 406 CAM_Obj3_HozlDst "Horizontal distance in X axis direction  of object 3
0x000-0x1FE: valid
0x1FF: NotAvailable";
CM_ SG_ 406 CAM_Obj3_Valid "Valid of object 3";
CM_ SG_ 406 CAM_Obj3_HozlPosnRi "Horizontal right edge of object 3
0x000-0x3E8: valid
0x3E9-0x3FD: Reserved
0x3FF: NotAvailable";
CM_ SG_ 406 CAM_Obj3_Typ "Type of object 3";
CM_ SG_ 406 CAM_Obj3_HozlPosnLe "Horizontal left edge of object 3
0x000-0x3E8: valid
0x3E9-0x3FD: Reserved
0x3FF: NotAvailable";
CM_ SG_ 406 CAM_Obj3_VertPosn "Vertical lower boundary of object  3
-10 to 10 degree";
CM_ SG_ 406 CAM_Obj3_HozlSpdLe "Horizontal angular velocity of left edge of object 3 (Left��negative and Right positive )
";
CM_ SG_ 406 CAM_Obj3_HozlSpdRi "Horizontal angular velocity of right edge of object 3 (Left��negative and Right positive )
";
CM_ SG_ 409 CHSKM_VCU_Sts1 "Checksum";
CM_ SG_ 409 ALV_VCU_Sts1 "Alive Counter";
CM_ SG_ 409 VCU_BMS_HVOnOff_REQ "BMS decides whether to close or disconnect the primary and negative relays by judging this command";
CM_ SG_ 410 CAM_Obj4_ID "ID of object 4
Light object ID. Range is 1-255, while 0 indicates that the field in unfilled.";
CM_ SG_ 410 CAM_Obj4_HozlDst "Horizontal distance in X axis direction  of object 4
0x000-0x1FE: valid
0x1FF: NotAvailable";
CM_ SG_ 410 CAM_Obj4_Valid "Valid of object 4";
CM_ SG_ 410 CAM_Obj4_HozlPosnRi "Horizontal right edge of object 4
0x000-0x3E8: valid
0x3E9-0x3FD: Reserved
0x3FF: NotAvailable";
CM_ SG_ 410 CAM_Obj4_Typ "Type of object 4";
CM_ SG_ 410 CAM_Obj4_HozlPosnLe "Horizontal left edge of object 4
0x000-0x3E8: valid
0x3E9-0x3FD: Reserved
0x3FF: NotAvailable";
CM_ SG_ 410 CAM_Obj4_VertPosn "Vertical lower boundary of object  4
-10 to 10 degree";
CM_ SG_ 410 CAM_Obj4_HozlSpdLe "Horizontal angular velocity of left edge of object 4 (Left��negative and Right positive )
";
CM_ SG_ 410 CAM_Obj4_HozlSpdRi "Horizontal angular velocity of right edge of object 4 (Left��negative and Right positive )
";
CM_ SG_ 412 CAM_Obj5_ID "ID of object 5
Light object ID. Range is 1-255, while 0 indicates that the field in unfilled.";
CM_ SG_ 412 CAM_Obj5_HozlDst "Horizontal distance in X axis direction  of object 5
0x000-0x1FE: valid
0x1FF: NotAvailable";
CM_ SG_ 412 CAM_Obj5_Valid "Valid of object 5";
CM_ SG_ 412 CAM_Obj5_HozlPosnRi "Horizontal right edge of object 5
0x000-0x3E8: valid
0x3E9-0x3FD: Reserved
0x3FF: NotAvailable";
CM_ SG_ 412 CAM_Obj5_Typ "Type of object 5";
CM_ SG_ 412 CAM_Obj5_HozlPosnLe "Horizontal left edge of object 5
0x000-0x3E8: valid
0x3E9-0x3FD: Reserved
0x3FF: NotAvailable";
CM_ SG_ 412 CAM_Obj5_VertPosn "Vertical lower boundary of object  5
-10 to 10 degree";
CM_ SG_ 412 CAM_Obj5_HozlSpdLe "Horizontal angular velocity of left edge of object 5 (Left��negative and Right positive )
";
CM_ SG_ 412 CAM_Obj5_HozlSpdRi "Horizontal angular velocity of right edge of object 5 (Left��negative and Right positive )
";
CM_ SG_ 413 CAM_Obj6_ID "ID of object 6
Light object ID. Range is 1-255, while 0 indicates that the field in unfilled.";
CM_ SG_ 413 CAM_Obj6_HozlDst "Horizontal distance in X axis direction  of object 6
0x000-0x1FE: valid
0x1FF: NotAvailable";
CM_ SG_ 413 CAM_Obj6_Valid "Valid of object 6";
CM_ SG_ 413 CAM_Obj6_HozlPosnRi "Horizontal right edge of object 6
0x000-0x3E8: valid
0x3E9-0x3FD: Reserved
0x3FF: NotAvailable";
CM_ SG_ 413 CAM_Obj6_Typ "Type of object 6";
CM_ SG_ 413 CAM_Obj6_HozlPosnLe "Horizontal left edge of object 6
0x000-0x3E8: valid
0x3E9-0x3FD: Reserved
0x3FF: NotAvailable";
CM_ SG_ 413 CAM_Obj6_VertPosn "Vertical lower boundary of object  6
-10 to 10 degree";
CM_ SG_ 413 CAM_Obj6_HozlSpdLe "Horizontal angular velocity of left edge of object 6 (Left��negative and Right positive )
";
CM_ SG_ 413 CAM_Obj6_HozlSpdRi "Horizontal angular velocity of right edge of object 6 (Left��negative and Right positive )
";
CM_ SG_ 414 CAM_Obj7_ID "ID of object 7
Light object ID. Range is 1-255, while 0 indicates that the field in unfilled.";
CM_ SG_ 414 CAM_Obj7_HozlDst "Horizontal distance in X axis direction  of object 7
0x000-0x1FE: valid
0x1FF: NotAvailable";
CM_ SG_ 414 CAM_Obj7_Valid "Valid of object 7";
CM_ SG_ 414 CAM_Obj7_HozlPosnRi "Horizontal right edge of object 7
0x000-0x3E8: valid
0x3E9-0x3FD: Reserved
0x3FF: NotAvailable";
CM_ SG_ 414 CAM_Obj7_Typ "Type of object 7";
CM_ SG_ 414 CAM_Obj7_HozlPosnLe "Horizontal left edge of object 7
0x000-0x3E8: valid
0x3E9-0x3FD: Reserved
0x3FF: NotAvailable";
CM_ SG_ 414 CAM_Obj7_VertPosn "Vertical lower boundary of object  7
-10 to 10 degree";
CM_ SG_ 414 CAM_Obj7_HozlSpdLe "Horizontal angular velocity of left edge of object 7 (Left��negative and Right positive )
";
CM_ SG_ 414 CAM_Obj7_HozlSpdRi "Horizontal angular velocity of right edge of object 7 (Left��negative and Right positive )
";
CM_ SG_ 415 CAM_Obj8_ID "ID of object 8 Light object ID. Range is 1-255, while 0 indicates that the field in unfilled.";
CM_ SG_ 415 CAM_Obj8_HozlDst "Horizontal distance in X axis direction  of object 8
0x000-0x1FE: valid
0x1FF: NotAvailable";
CM_ SG_ 415 CAM_Obj8_Valid "Valid of object 8";
CM_ SG_ 415 CAM_Obj8_HozlPosnRi "Horizontal right edge of object 8
0x000-0x3E8: valid
0x3E9-0x3FD: Reserved
0x3FF: NotAvailable";
CM_ SG_ 415 CAM_Obj8_Typ "Type of object 8";
CM_ SG_ 415 CAM_Obj8_HozlPosnLe "Horizontal left edge of object 8
0x000-0x3E8: valid
0x3E9-0x3FD: Reserved
0x3FF: NotAvailable";
CM_ SG_ 415 CAM_Obj8_VertPosn "Vertical lower boundary of object 8 -10 to 10 degree";
CM_ SG_ 415 CAM_Obj8_HozlSpdLe "Horizontal angular velocity of left edge of object 8 (Left��negative and Right positive )";
CM_ SG_ 415 CAM_Obj8_HozlSpdRi "Horizontal angular velocity of right edge of object 8 (Left��negative and Right positive )";
CM_ SG_ 417 CHSKM_V_VEH "Checksum";
CM_ SG_ 417 ALIV_V_VEH "Alive counter";
CM_ SG_ 417 V_VEH_COG "Vehicle speed for powertrain";
CM_ SG_ 417 DVCO_VEH "Driving condition";
CM_ SG_ 417 QU_V_VEH_COG "Vehicle speed valid";
CM_ SG_ 504 CHKSM_EDS_OutPut_FR "Check sum";
CM_ SG_ 504 ALV_EDS_OutPut_FR "Alive Counter";
CM_ SG_ 504 EDS_Work_STS_FR "EDS Work status ";
CM_ SG_ 504 EDS_Spd_FR "Current motor speed";
CM_ SG_ 504 EDS_output_trqValid_FR "Indicate the valid flag of current motor torque";
CM_ SG_ 504 EDS_MotorDriveSts_FR "The drive state of EDS";
CM_ SG_ 504 EDS_powoff_req_FR "If there is a serious failure in the running process of EDS, the high voltage of VCU will be requested ";
CM_ SG_ 504 EDS_SpdValid_FR "Indicate the valid flag of current motor speed";
CM_ SG_ 504 EDS_output_trq_FR "Actual output torque of current EDS";
CM_ SG_ 504 EDS_VCU_6SO_flag_FWD "Indicate the valid flag of current front motor 6SO possible";
CM_ SG_ 505 CHKSM_EDS_OutPut_RR "Check sum";
CM_ SG_ 505 ALV_EDS_OutPut_RR "Alive Counter";
CM_ SG_ 505 EDS_Work_STS_RR "Rear EDS Work status ";
CM_ SG_ 505 EDS_Spd_RR "current rear motor speed";
CM_ SG_ 505 EDS_output_trqValid_RR "Indicate the valid flag of current rear motor torque";
CM_ SG_ 505 EDS_MotorDriveSts_RR "The drive state of rear EDS";
CM_ SG_ 505 EDS_powoff_req_RR " If there is a serious failure in the running process of rear EDS, the high voltage of VCU will be requested ";
CM_ SG_ 505 EDS_SpdValid_RR "Indicate the valid flag of current rear motor speed";
CM_ SG_ 505 EDS_output_trq_RR "Actual output torque of current Rear motor ";
CM_ SG_ 505 EDS_VCU_6SO_flag_RWD "Indicate the valid flag of current rear motor 6SO possible";
CM_ SG_ 506 MHU_TouchEvtTyp "touch screen event type";
CM_ SG_ 506 SECCAN_Drvr_Info "Seed portion from Secure CAN algorithm";
CM_ SG_ 506 MHU_XGestureSpd "MHU_XGestureSpd";
CM_ SG_ 506 MHU_YGestureSpd "MHU_YGestureSpd";
CM_ SG_ 506 MHU_Ycoordinate "MHU_Ycoordinate";
CM_ SG_ 506 MHU_Xcoordinate "MHU_Xcoordinate";
CM_ SG_ 515 CHKSM_Camera_rightlane "Checksum";
CM_ SG_ 515 ALV_Camera_rightlane "Alive Counter";
CM_ SG_ 515 R1_LINE_TYPE "Right right lane line type
";
CM_ SG_ 515 R0_LINE_TYPE "Right lane line type";
CM_ SG_ 515 SECCAN_Camera_rightlane "Secret portion from Secure CAN algorithm";
CM_ SG_ 516 CHKSM_Camera_leftlane "Checksum";
CM_ SG_ 516 ALV_Camera_leftlane "Alive Counter";
CM_ SG_ 516 L1_LINE_TYPE "Left letf lane line type
";
CM_ SG_ 516 L0_LINE_TYPE "Left lane line type";
CM_ SG_ 516 SECCAN_Camera_leftlane "Secret portion from Secure CAN algorithm";
CM_ SG_ 517 Checksum_0x205 "Checksum";
CM_ SG_ 517 Rolling_Counter_0x205 "Rolling Counter";
CM_ SG_ 517 BMS_CellNumMinCellVol "Cell Number of Min Cell Voltage ";
CM_ SG_ 517 BMS_CellNumMaxCellVol "Cell Number of Max Cell Voltage ";
CM_ SG_ 517 BMS_MinCellVol "Min Cell Voltage ";
CM_ SG_ 517 BMS_MaxCellVol "Max Cell Voltage ";
CM_ SG_ 518 CHKSM_ADAS_ELK "Checksum";
CM_ SG_ 518 ALV_ADAS_ELK "Alive Counter";
CM_ SG_ 518 ADAS_HWA_Fautlstate "HWA fault status";
CM_ SG_ 518 ADAS_ELK_check "Emergency Lane Keeping check";
CM_ SG_ 518 ADAS_handsoff_Warning_Mode_2 "Hands off warning level";
CM_ SG_ 518 ADAS_HWA_txtpopup "HWA Text Popups Based on system states- functional cases";
CM_ SG_ 518 ADAS_HWA_state "HWA state";
CM_ SG_ 518 ADAS_Mode2_status "System mode: Mode 1 & 2";
CM_ SG_ 518 ADAS_ALC_Mode_feed "ALCA feedback status";
CM_ SG_ 518 ADAS_handsoff_txtpopup "Hands off warning popup text";
CM_ SG_ 518 ADAS_ALC_txtpopup "ALC Text Popups Based on system states- functional cases";
CM_ SG_ 518 ADAS_ALC_state "ALC state";
CM_ SG_ 518 ADAS_LA_Display "Lane assist function and lane display ";
CM_ SG_ 518 ADAS_Lane_Line_Curva_Radius "Lane line curvature redius (minus for left curve, plus for right curve, radius > 1000m, display as straight curve";
CM_ SG_ 519 SR_Undervoltage_Fault_Sts "Sunroof under voltage status";
CM_ SG_ 519 SR_Overvoltage_Fault_Sts "Sunroof over voltage ";
CM_ SG_ 519 SR_SLEEP_RQ "Sunroof sleep request";
CM_ SG_ 519 SR_Position "Sunroof position";
CM_ SG_ 519 SR_Motor_Running_Sts "Sunroof motor running status";
CM_ SG_ 519 SR_MotorReverse_Fault_Sts "Sunroof motor reverse status";
CM_ SG_ 519 SR_Hall_Fault_Sts "SR Hall Fault Sts";
CM_ SG_ 519 SR_Normalisation_Sts "SR Normalisation Sts";
CM_ SG_ 519 SR_Relay_Fault "SR Relay Fault";
CM_ SG_ 519 SR_Commu_Fault_Sts "Sunroof comminication status";
CM_ SG_ 519 SR_Initialisation_Status "SR_Initialisation_Status";
CM_ SG_ 519 SR_Ctrl_Result "Sunroof control result";
CM_ SG_ 519 SR_ThermalProtection_Fault_Sts "Sunroof thermal protection status";
CM_ SG_ 519 SR_Posit_Percentage "Sunroof position in percentage";
CM_ SG_ 519 SR_Operation_Stat "Sunroof operating state ";
CM_ SG_ 519 SR_Error_RSP "Sunroof error";
CM_ SG_ 519 BCM_AutoSunroof_Sts "Auto Sunroof setting feedback";
CM_ SG_ 520 SS_MotorReverse_Fault_Status "Sunshade MotorReverse Fault Status";
CM_ SG_ 520 SS_Motor_Running_Status "Sunshade Motor Running Status";
CM_ SG_ 520 SS_Position "Sunshade Position";
CM_ SG_ 520 SS_SLEEP_RQ "Sunshade SLEEP RQ";
CM_ SG_ 520 SS_Undervoltage_Fault_Status "Sunshade Undervoltage Fault Status";
CM_ SG_ 520 SS_Ctrl_Result "Sunshade Ctrl Result";
CM_ SG_ 520 SS_Overvoltage_Fault_Status "Sunshade Overvoltage Fault Status";
CM_ SG_ 520 SS_Relay_Fault "SS_Relay_Fault";
CM_ SG_ 520 SS_Normalisation_Status "SS_Normalisation_Status";
CM_ SG_ 520 SS_Hall_Fault_Status "Sunshade Driver Fault Status";
CM_ SG_ 520 SS_Commu_Fault_Status "Sunshade Commu Fault Status";
CM_ SG_ 520 SS_Initialisation_Status "SS_Initialisation_Status";
CM_ SG_ 520 SS_Posit_Percentage "Sunshade Posit Percentage";
CM_ SG_ 520 SS_ThermalProtection_Flt_Sts "Sunshade ThermalProtection Fault Status";
CM_ SG_ 520 SS_Operation_State "Sunshade Operation State";
CM_ SG_ 520 SECCAN_SunshadeSts "Secret portion from Secure CAN algorithm";
CM_ SG_ 520 SS_Error_RSP "Sunshade Error RSP";
CM_ SG_ 521 CHKSM_PAS_RAEB "Checksum.";
CM_ SG_ 521 ALV_PAS_RAEB "Alive Counter.
";
CM_ SG_ 521 PAS_RAEB_check "Rear Automatic Emergency Brake Check.";
CM_ SG_ 521 PAS_RAEB_Mode_Feed "Rear Automatic Emergency Brake Mode select.";
CM_ SG_ 521 PAS_RAEB_State "Rear Automatic Emergency Brake State.";
CM_ SG_ 521 PAS_RAEB_Warning "Rear Automatic Emergency Brake warning.";
CM_ SG_ 522 ETG_Lift_Gate_Status "The working status of rear lift gate";
CM_ SG_ 522 ETG_Power_Latch_Status "The working status of power latch";
CM_ SG_ 522 ETG_Latch_Segment "The segment of power latch";
CM_ SG_ 522 ETG_Opening_Percentage "The opening percentage of rear lift gate";
CM_ SG_ 522 ETG_DSW_Status "The status of driver switch";
CM_ SG_ 522 ETG_GSW_Status "The status of gate switch";
CM_ SG_ 522 ETG_LTS_Status "The status of left touch sensor";
CM_ SG_ 522 ETG_RTS_Status "The status of right touch sensor";
CM_ SG_ 522 ETG_HAL_Status "The level status of latch's half switch";
CM_ SG_ 522 ETG_FUL_Status "The level status of latch's full switch";
CM_ SG_ 522 ETG_AJR_Status "The level status of latch's AJAR switch";
CM_ SG_ 522 ETG_NTL_Status "The level status of latch's neutral switch";
CM_ SG_ 522 ETG_ERR_Voltage "The error status of ETG voltage";
CM_ SG_ 522 ETG_ERR_Left_Motor "The error status of left lift motor";
CM_ SG_ 522 ETG_ERR_Right_Motor "The error status of right lift motor";
CM_ SG_ 522 ETG_ERR_Latch "The error status of power latch";
CM_ SG_ 522 ETG_ERR_Hall "The error status of hall signal";
CM_ SG_ 522 ETG_Lift_Motor_Stall "The stall protection status of lift motor";
CM_ SG_ 522 ETG_Lift_Motor_AntiPinch "The antipinch protection status of lift motor";
CM_ SG_ 522 ETG_Lift_Motor_Thermal "The thermal protection status of lift motor";
CM_ SG_ 522 ETG_Power_Latch_Thermal "The thermal protection status of power latch";
CM_ SG_ 522 ETG_Abuse_Protection "The abuse protection status of ETG";
CM_ SG_ 523 FKS_RespError "FMS Error Status";
CM_ SG_ 523 FKS_OpenReq "Hands Free Access Operation Request";
CM_ SG_ 523 FKS_HWError "HW Error is set if error in RAM, ROM or NVRAM is detected.";
CM_ SG_ 523 FKS_AntennaError "Error for Bottom and Top Electrode is set if electrode is not connected, connection is broken or electrod is shorted to GND/VSUP.";
CM_ SG_ 523 FKS_OverVolDected "Over voltage error";
CM_ SG_ 523 FKS_UnderVolDected "Under voltage error";
CM_ SG_ 523 FKS_activate_deactivate "feedback activate or deactivate ";
CM_ SG_ 524 CHKSM_IC_ODO "Checksum";
CM_ SG_ 524 ALIV_IC_ODO "Alive Counter";
CM_ SG_ 524 MHU_Odometer_IC "Odometer information.";
CM_ SG_ 525 CHKSM_IDB_STATUS "Checksum";
CM_ SG_ 525 ALV_IDB_STATUS "Alive counter";
CM_ SG_ 525 ESPTransRequestType "ESP Request Type";
CM_ SG_ 525 ABSFault "ABS Fault Status";
CM_ SG_ 525 ABSActive "Further details when which bit will be set are defined within attached Excel file: Functions_Interventions File is at the moment under review at Bosch IDB side";
CM_ SG_ 525 VehicleSpd "Vehicle Speed";
CM_ SG_ 525 ESC_VehicleStandstill "Vehicle stationary detected";
CM_ SG_ 525 MCPressureSts "Main Cilinder Pressure Status";
CM_ SG_ 525 VehicleSpdSts "Vehicle Speed Status";
CM_ SG_ 525 MCPressure "MC Pressure";
CM_ SG_ 525 ESC_Braking_effort "Status of braking effort on wheel (used to know when the ESC need to apply a brake effort to ensure the deceleration)";
CM_ SG_ 525 BRAKE_LightonRequestEPBi "Brake lights on equested by EPBi";
CM_ SG_ 525 VDCActive "Vehicle dynamic control activation";
CM_ SG_ 525 TCSActive "Traction control system activation";
CM_ SG_ 525 TCSAvailable "Traction control system available";
CM_ SG_ 525 IDBActive "IDB activation";
CM_ SG_ 525 IDBFault "IDB fault ";
CM_ SG_ 525 ESC_VehicleHoldStat "Set if vehicle stationary for ACC is detected";
CM_ SG_ 525 IDB_Power_Stage "interchange prevention signal ";
CM_ SG_ 525 ESC_BrakeReleasedFailsafe "ESC has detected a skidding away and as a consequence is releasing the brakes. Driver is to be informed to take control over.";
CM_ SG_ 526 Chksum_PAS_APA_txt "Checksum";
CM_ SG_ 526 Alive_PAS_APA_txt "Alive Counter";
CM_ SG_ 526 PAS_APA_ReqInfoDispTxt2 "Parking process text reminder";
CM_ SG_ 526 PAS_APA_ReqInfoDispTxt1 "the reason of APA can not Active";
CM_ SG_ 526 PAS_APA_ReqInfoDispTxt4 "searching progress infomation reminder";
CM_ SG_ 526 PAS_APA_ReqInfoDispTxt3 "Parking process abnormal reminder";
CM_ SG_ 526 PAS_RP_ReqInfoDispTxt1 "ADAS RP Req Info Txt1";
CM_ SG_ 526 PAS_RP_ReqInfoDispTxt2 "self check remind user";
CM_ BO_ 527 "ADAS_BCM_Status";
CM_ SG_ 527 CHKSM_ADAS_BCM_Status "Checksum";
CM_ SG_ 527 ALIVE_ADAS_BCM_Status "Alive counter";
CM_ SG_ 527 ADAS_BCM_HeadlightReq "ADAS_request BCM to light up headlight lowbeam";
CM_ SG_ 527 ADAS_BCM_FoldMirrorReq "ADAS_request BCM to fold rearview mirror";
CM_ SG_ 527 ADAS_BCM_Status "ADAS_Status";
CM_ SG_ 527 ADAS_BCM_IndicatorlightReq "ADAS_request BCM to light up these light";
CM_ SG_ 527 SECCAN_ADAS_BCM_Sts "Secret portion from Secure CAN algorithm";
CM_ SG_ 531 CHSKM_VCU_POD_reqDCDC "Check sum";
CM_ SG_ 531 ALV_VCU_POD_reqDCDC "Alive counter";
CM_ SG_ 531 VCU_enableDCDC "Requests DCDC to turn on";
CM_ SG_ 531 VCU_vDCDCRequest "voltage output request for DCDC";
CM_ SG_ 531 VCU_iDCDCRequest_lim "This signal indicates limit value for output current, calculated basing on 12V power management strategy and limitted by POD_DCDC_Max_Current_Out.";
CM_ SG_ 532 Checksum_0x214 "Checksum";
CM_ SG_ 532 Rolling_Counter_0x214 "Rolling Counter";
CM_ SG_ 532 BMS_Display_SOC "Display SOC ";
CM_ SG_ 532 BMS_SOCE "State of certified energy ";
CM_ SG_ 533 Checksum_0x215 "Checksum";
CM_ SG_ 533 Rolling_Counter_0x215 "Rolling Counter";
CM_ SG_ 533 BMS_BatBalance_ERR "Battery Balance Error indicates Balancing switch is short or open";
CM_ SG_ 533 BMS_Balance_STS "BMS Balance Status ";
CM_ SG_ 533 BMS_IGN_Sts "the ignition signal status (on/off)";
CM_ SG_ 533 BMS_HWCrash_Sts "Battery Pack Hardware Crash signal Status";
CM_ SG_ 533 BMS_HVIL_STS "The HVIL state of BMS";
CM_ SG_ 533 BMS_HVOnOff_STS "Status of the High Voltage";
CM_ SG_ 533 BMS_ERR_LEV "BMS requesting VCU to operate at the limited operating strategy (LOS)";
CM_ SG_ 533 BMS_SocActual_EST "Actual SOC ";
CM_ SG_ 533 BMS_Sys_STS "BMS_Status(Self-test after BMS wake-up) BMS VCU";
CM_ SG_ 533 BMS_ISU_Status "Pack Insulation Status";
CM_ SG_ 533 BMS_SOH "BMS State Of Health ";
CM_ SG_ 533 BMS_SOE "BMS State Of Enegy ";
CM_ SG_ 533 BMS_HV_Sts "HV Status";
CM_ SG_ 534 Checksum_0x216 "Checksum";
CM_ SG_ 534 Rolling_Counter_0x216 "Rolling Counter";
CM_ SG_ 534 BMS_RemainChargeTime "Remain Charge Time send to other ECU (XGW - IPC)";
CM_ SG_ 534 BMS_ChgVoltage_REQ "Charge Voltage Request";
CM_ SG_ 534 BMS_ChgCurrent_REQ "Charge Current Request";
CM_ SG_ 538 DMS_HeadPitch "Head pitch angle.";
CM_ SG_ 538 DMS_HeadRoll "Head roll angle.";
CM_ SG_ 538 DMS_HeadYaw "Head yaw angle.";
CM_ SG_ 538 DMS_HeadX "Distance of X axis between head and camera.";
CM_ SG_ 538 DMS_HeadY "Distance of Y axis between head and camera.";
CM_ SG_ 538 DMS_HeadZ "Distance of Z axis between head and camera.";
CM_ SG_ 540 CHKSM_FCAM_AEB "Checksum";
CM_ SG_ 540 ALV_FCAM_AEB "Alive Counter";
CM_ SG_ 540 FCAM_AEB_Warning "Automatic Emergency Brake Warning Mode ";
CM_ SG_ 540 FCAM_AEB_State "Automatic Emergency Brake State";
CM_ SG_ 540 FCAM_AEB_Mode_Feed "AEB Mode feedback";
CM_ SG_ 540 FCAM_AEB_check "Automatic Emergency Brake Check";
CM_ SG_ 540 SECCAN_FCAM_AEB "Seed generated from Secure CAN algorithm";
CM_ SG_ 544 MHU_SET_CCUR_AirCondition "On Off Air Condition";
CM_ SG_ 544 MHU_SET_CCUR_AutoAC "On Off Auto Air Condition";
CM_ SG_ 544 MHU_SET_CCUR_RearLock "Lock the Rear AC";
CM_ SG_ 544 MHU_SET_CCUR_MaxAc "On Off Max Air Condition for 2 zone";
CM_ SG_ 544 MHU_SET_CCUR_FanSpeed "Adjust Fan speed with 6 level";
CM_ SG_ 544 MHU_SET_CCUR_Recirculation "Change recirculation mode inside, ouside, auto";
CM_ SG_ 544 MHU_SET_CCUR_Ion "On Off Air ionizer";
CM_ SG_ 544 MHU_SET_CCUR_FlapPosition "Change Flap position Face, Feet, Front defrost";
CM_ SG_ 544 MHU_SET_CCUR_SyncClimateZone "On Off sync temperature between zone";
CM_ SG_ 544 MHU_SET_CCUR_TempRear "change rear zone temperature";
CM_ SG_ 544 MHU_SET_CCUR_FrontDefrost "Change Flap poition to Front Defrost";
CM_ SG_ 545 DrvSeatMsgStrLvl "Drv Seat Message Str Lvl";
CM_ SG_ 545 PassSeatMsgStrLvl "Pass Seat Message Str Lvl";
CM_ SG_ 545 RearDrvSeatMsgStrLvl "Rear Drv Sea tMessage St rLvl";
CM_ SG_ 545 RearPassSeatMsgStrLvl "Rear Pass Seat Message Str Lvl";
CM_ SG_ 545 DrvSeatMsgMode "DrvSeatMsgMode";
CM_ SG_ 545 PassSeatMsgMode "PassSeatMsgMode";
CM_ SG_ 545 RearDrvSeatMsgMode "RearDrvSeatMsgMode";
CM_ SG_ 545 RearPassSeatMsgMode "RearPassSeatMsgMode";
CM_ SG_ 546 DrvSeatMsgModeStat "DrvSeatMsgModeStat";
CM_ SG_ 546 PassSeatMsgModeStat "PassSeatMsgModeStat";
CM_ SG_ 546 RearDrvSeatMsgModeStat "RearDrvSeatMsgModeStat";
CM_ SG_ 546 RearPassSeatMsgModeStat "RearPassSeatMsgModeStat";
CM_ SG_ 546 LSSM_ALINResErr "LSSM_A DrvSeat LINResErr";
CM_ SG_ 546 LSSM_APumpFail "LSSM_A DrvSeat PumpFail";
CM_ SG_ 546 DrvSeatMsgStrLvlStat "DrvSeatMsgStrLvlStat";
CM_ SG_ 546 LSSM_BLINResErr "LSSM_B PassSeat LINResErr";
CM_ SG_ 546 LSSM_BPumpFail "LSSM_B PassSeat PumpFail";
CM_ SG_ 546 PassSeatMsgStrLvlStat "PassSeatMsgStrLvlStat";
CM_ SG_ 546 LSSM_CLINResErr "LSSM_C RearDrvSeat LINResErr";
CM_ SG_ 546 LSSM_CPumpFail "LSSM_C RearDrvSeat PumpFail";
CM_ SG_ 546 RearDrvSeatMsgStrLvlStat "RearDrvSeatMsgStrLvlStat";
CM_ SG_ 546 LSSM_DLINResErr "LSSM_D RearPassSeat LINResErr";
CM_ SG_ 546 LSSM_DPumpFail "LSSM_D RearPassSeat PumpFail";
CM_ SG_ 546 RearPassSeatMsgStrLvlStat "RearPassSeatMsgStrLvlStat";
CM_ SG_ 549 Checksum_0x225 "Checksum";
CM_ SG_ 549 Rolling_Counter_0x225 "Rolling Counter";
CM_ SG_ 549 CDM_bAcvCanComStblMon "Monitored flag indicating active stable CAN communication.";
CM_ SG_ 549 FRMo_bErrHvbatStReqExtMon "Collective error flag indicating HV battery state request E2E fault.";
CM_ SG_ 549 FRMo_bErrChrgnAllwdExtMon "Collective error flag indicating charging allowed E2E fault.";
CM_ SG_ 549 FRMo_bErrVehCrashStExtMon "Collective error flag indicating vehicle crash state E2E fault.";
CM_ SG_ 549 CDM_bErrComctnLossCanMon "Error flag indicating total loss of CAN communication fault";
CM_ SG_ 549 CTCMon_bErrCtctrSopcMon "Error flag indicating contactor switch-off path test fault.";
CM_ SG_ 549 CTCMon_bInvldCtctrHisdIFbMon "Error flag indicating high-side feedback current invalidity.";
CM_ SG_ 549 CTCMon_bInvldCtctrLosdUFbMon "Error flag indicating low-side feedback voltage invalidity.";
CM_ SG_ 549 CTM_bErrCellTDifMaxMon "Error flag indicating maximum cell temperature difference fault.";
CM_ SG_ 549 CTM_bErrCellTMaxMon "Error flag indicating maximum cell temperature limit fault.";
CM_ SG_ 549 CTM_bErrCellTMinMon "Error flag indicating minimum cell temperature limit fault.";
CM_ SG_ 549 CTM_bErrThrwyPredMon "Error flag indicating thermal runaway fault.";
CM_ SG_ 549 CUM_bErrCellUDifMaxMon "Error flag indicating maximum cell voltage difference fault.";
CM_ SG_ 549 CUM_bErrCellUMaxMon "Error flag indicating cell overvoltage fault.";
CM_ SG_ 549 CUM_bErrCellUMinMon "Error flag indicating cell undervoltage fault.";
CM_ SG_ 549 CUM_bErrCellUProtnMaxNvMon "Non-volatile error flag indicating cell overvoltage protection limit fault.";
CM_ SG_ 549 CUM_bErrCellUProtnMinNvMon "Non-volatile error flag indicating cell undervoltage protection limit fault.";
CM_ SG_ 549 CUM_bErrPackUImplyMon "Error flag indicating pack voltage implausibility.";
CM_ SG_ 549 EHPMon_bRdyHvilMon "Ready flag indicating operational HVIL circuit.";
CM_ SG_ 549 EHPMon_bErrWlddNegNvMon "Non-volatile error flag indicating welded negative contactor fault.";
CM_ SG_ 549 EHPMon_bErrWlddPosNvMon "Non-volatile error flag indicating welded positive contactor fault.";
CM_ SG_ 549 EHPMon_bErrWlddPrechNvMon "Non-volatile error flag indicating welded precharge contactor fault.";
CM_ SG_ 549 EHPMon_bErrHvilMon "Error flag indicating HVIL open line fault.";
CM_ SG_ 549 EHPMon_bErrHvilShoMon "Error flag indicating HVIL invalidity (ScG/ScB) fault.";
CM_ SG_ 549 EHPMon_bErrPackIslnRNvMon "Non-volatile error flag indicating pack level isolation resistance fault.";
CM_ SG_ 549 EHPMon_bErrVehCrashNvMon "Non-volatile error flag indicating vehicle crash fault.";
CM_ SG_ 549 EHPMon_bErrVehIslnRNvMon "Non-volatile error flag indicating vehicle level isolation resistance fault.";
CM_ SG_ 549 FRMo_bErrMemStorgNvMon "Error flag indicating storage fault in the non-volatile memory.";
CM_ SG_ 549 L1IM_bErrClmp30MaxMonInp "Error flag indicating Level 1 KL30 overvoltage fault.";
CM_ SG_ 549 L1IM_bErrClmp30MinMonInp "Error flag indicating Level 1 KL30 undervoltage fault.";
CM_ SG_ 549 L1IM_bErrCtctrDtrtMonInp "Error flag indicating Level 1 contactor deterioration";
CM_ SG_ 549 L1IM_bErrUActImplyMonInp "Error flag indicating Level 1 high voltage implausibility.";
CM_ SG_ 549 MCCM_bAcvMdulCtlrStsMon "Active flag indicating operational module controller status.";
CM_ SG_ 549 MCCM_bErrLntecSngFltMon "Error flag indicating single-point safety mechanism fault of the Multi-Stack Battery Monitor.";
CM_ SG_ 549 MCCM_bErrLntecLtntFltMon "Error flag indicating latent safety mechanism fault of the Multi-Stack Battery Monitor.";
CM_ SG_ 549 MCCM_bErrMdulCellSnsrCfgMon "Error flag indicating module/cell/temperature sensor configuration fault.";
CM_ SG_ 549 MCCM_bErrMdulCtlrComMon "Error flag indicating module controller communication status fault.";
CM_ SG_ 549 MCCM_bErrSnsrTEltlMon "Error flag indicating multiple temperature sensor in a module fault.";
CM_ SG_ 549 MCCM_bWarnSnsrTEltlMon "Error flag indicating single temperature sensor in a module fault.";
CM_ SG_ 549 PCM_bRdySnsrIMon "Ready flag indicating operational current sensors.";
CM_ SG_ 549 PCM_bErrPackEFlowMaxLimMon "Error flag indicating energy flow limit fault.";
CM_ SG_ 549 PCM_bErrPackIChDchaMaxLimMon "Error flag indicating pack current charging/discharging limit fault.";
CM_ SG_ 549 PCM_bErrSnsrIImplyMon "Error flag indicating current sensor implausibility fault.";
CM_ SG_ 549 FRMo_bErrSnsrI1ExtMon "Collective error flag indicating current sensor 1 (CAN-based shunt sensor) E2E fault.";
CM_ SG_ 549 PCM_bInvldSnsrI1Mon "Error flag indicating current sensor 1 invalidity fault.";
CM_ SG_ 549 PCM_bInvldSnsrI2Mon "Error flag indicating current sensor 2 invalidity fault.";
CM_ SG_ 549 FRMo_bErrSopcLvl3Mon "Error flag indicating Level 3 switch-off path test fault. ";
CM_ SG_ 549 BMS_FRMo_Reserved_1 "Fault monitor signal";
CM_ SG_ 549 BMS_FRMo_Reserved_2 "Fault monitor signal";
CM_ SG_ 549 BMS_FRMo_Reserved_3 "Fault monitor signal";
CM_ SG_ 549 BMS_FRMo_Reserved_4 "Fault monitor signal";
CM_ SG_ 549 BMS_FRMo_Reserved_5 "Fault monitor signal";
CM_ SG_ 561 NDoorFLOutsideHandleFailure "Front Left Door Outside Handle Failure";
CM_ SG_ 561 NDoorLatchFLFailure "Front Left Door Status Message Counter";
CM_ SG_ 565 CHKSM_TRM_STATUS "Checksum";
CM_ SG_ 565 ALIVE_TRM_STATUS "Alive counter";
CM_ SG_ 565 TowingDetected "Towing status ( reserved )";
CM_ SG_ 565 TrailerDetected "Trailer Detected status";
CM_ SG_ 569 NDoorRROutsideHandleFailure "Rear Right Door Outside Handle Failure";
CM_ SG_ 569 NDoorLatchRRFailure "Rear Right Door Status Message Counter";
CM_ SG_ 570 IDB_WheelDirection_FR "IDB Front Right Wheel Direction";
CM_ SG_ 570 IDB_WheelDirection_FL "IDB Front Left Wheel Direction";
CM_ SG_ 570 IDB_WheelSpeedRC_FL "IDB Front Left Wheel Speed Pulse";
CM_ SG_ 570 IDB_WheelSpeedRC_FR "IDB Front Right Wheel Speed Pulse";
CM_ SG_ 570 SECCAN_IDB_WheelSts_FR "Seed portion from Secure CAN algorithm.";
CM_ SG_ 571 IDB_WheelDirection_RR "IDB Rear Right Wheel Direction";
CM_ SG_ 571 IDB_WheelDirection_RL "IDB Rear Left Wheel Direction";
CM_ SG_ 571 IDB_WheelSpeedRC_RL "IDB Rear Left Wheel Speed Pulse";
CM_ SG_ 571 IDB_WheelSpeedRC_RR "IDB Rear Right Wheel Speed Pulse";
CM_ SG_ 571 SECCAN_IDB_WheelSts_RR "Seed portion from Secure CAN algorithm.";
CM_ SG_ 581 Checksum_0x245 "Checksum";
CM_ SG_ 581 Rolling_Counter_0x245 "Rolling Counter";
CM_ SG_ 581 BMS_ProbeNumMaxCellTemp "Probe Number of Max Cell Temperature ";
CM_ SG_ 581 BMS_MinCellTemp "Min Cell Temperature ";
CM_ SG_ 581 BMS_ProbeNumMinCellTemp "Probe Number of Min Cell Temperature ";
CM_ SG_ 581 BMS_PackTemp "Pack Temperature ";
CM_ SG_ 581 BMS_MaxCellTemp "Max Cell Temperature ";
CM_ SG_ 581 BMS_MaxMinDiffCellTemp "max and min cell temperature differences ";
CM_ SG_ 584 NDoorFROutsideHandleFailure "Front Right Door Outside Handle Failure";
CM_ SG_ 584 NDoorLatchFRFailure "Front Right Door Status Message Counter";
CM_ SG_ 585 CHSKM_BMS_CoolntInletOutletTmp "Check sum";
CM_ SG_ 585 ALV_BMS_CoolntInletOutletTmp "Alive counter";
CM_ SG_ 585 BMS_CoolantInletTemp "Temperature of Battery Coolant Inlet";
CM_ SG_ 585 BMS_CoolantOutletTemp "Temperature of Battery Coolant Outlet";
CM_ SG_ 585 BMS_BDUTemp1 "BDU Temperature ";
CM_ SG_ 585 BMS_BDUTemp2 "BDU Temperature ";
CM_ SG_ 588 CHSKM_BMS_VCU_THMReq "Check sum";
CM_ SG_ 588 ALV_BMS_VCU_THMReq "Alive counter";
CM_ SG_ 588 BMS_FlowRate_Req "Flow rate required";
CM_ SG_ 588 BMS_CoolPwrDemand "requesting the cooling power required fro the battery pack";
CM_ SG_ 588 BMS_HeatPwrDemand "requesting the heating power required fro the battery pack";
CM_ SG_ 588 BMS_VCU_PTCOnOff_Req "PTC Heater turn on and off request";
CM_ SG_ 588 BMS_VCU_ValveOnOff_Req "requesting VCU to turn on and off the valve";
CM_ SG_ 588 BMS_PreHeatCoolReq "Battery pack precondition information";
CM_ SG_ 596 CRC_AVL_RPM_WHL_REAR "Checksum";
CM_ SG_ 596 ALIV_AVL_RPM_WHL_REAR "Alive Counter";
CM_ SG_ 596 AVL_RPM_WHL_RLH "Measured speed of the rear left single wheel.";
CM_ SG_ 596 AVL_RPM_WHL_RRH "Measured speed of the rear right single wheel.";
CM_ SG_ 596 QU_AVL_RPM_WHL_RLH "status qualifier to signal actual-value_RPM_wheel_HL.";
CM_ SG_ 596 QU_AVL_RPM_WHL_RRH "status qualifier to signal actual-value_RPM_wheel_HR.";
CM_ SG_ 597 CRC_AVL_RPM_WHL_FRONT "Checksum";
CM_ SG_ 597 ALIV_AVL_RPM_WHL_FRONT "Alive Counter";
CM_ SG_ 597 AVL_RPM_WHL_FLH "Measured speed of the front left single wheel.";
CM_ SG_ 597 AVL_RPM_WHL_FRH "Measured speed of the front right single wheel.";
CM_ SG_ 597 QU_AVL_RPM_WHL_FLH "status qualifier to signal actual-value_RPM_wheel_VL.";
CM_ SG_ 620 HU_PASDirSel "PAS Pull-Out Direction Selection";
CM_ SG_ 620 HU_AutPrkgSlotSel "Auto Partking ParkSlot Selection";
CM_ SG_ 597 QU_AVL_RPM_WHL_FRH "status qualifier to signal actual-value_RPM_wheel_VL.";
CM_ SG_ 640 ANRC_PrkgRiSlotDst2_Y "Indicate the distance in Y between vehicle and Right2 slot";
CM_ SG_ 640 ANRC_PrkgRiSlot2_VehAngal "Indicate the angal  between vehicle and Right2 slot";
CM_ SG_ 640 ANRC_PrkgRiSlotDst2_X "Indicate the distance between vehicle and Right2 slot";
CM_ SG_ 641 NDoorRLOutsideHandleFailure "Rear Left Door Outside Handle Failure";
CM_ SG_ 641 NDoorLatchRLFailure "Rear Left Door Status Message Counter";
CM_ SG_ 642 ANRC_PrkgLeSlotDst1_Y "Indicate the distance in Y between vehicle and Left1 slot.";
CM_ SG_ 642 ANRC_PrkgLeSlot1_VehAngal "Indicate the angal  between vehicle and Left1 slot.";
CM_ SG_ 642 ANRC_PrkgLeSlotDst1_X "Indicate the distance between vehicle and Left1 slot.";
CM_ SG_ 643 ANRC_PrkgLeSlotDst2_Y "Indicate the distance in Y between vehicle and Left2 slot.";
CM_ SG_ 643 ANRC_PrkgLeSlot2_VehAngal "Indicate the angal  between vehicle and Left2 slot.";
CM_ SG_ 643 ANRC_PrkgLeSlotDst2_X "Indicate the distance between vehicle and Left2 slot.";
CM_ SG_ 644 ANRC_PrkgRiSlotDst3_Y "Indicate the distance in Y between vehicle and Right3 slot.";
CM_ SG_ 644 ANRC_PrkgRiSlot3_VehAngal "Indicate the angal between vehicle and Right3 slot.";
CM_ SG_ 644 ANRC_PrkgRiSlotDst3_X "Indicate the distance between vehicle and Right3 slot.";
CM_ SG_ 649 CHKSM_IDB_ZF2 "Checksum";
CM_ SG_ 649 ALIVE_IDB_ZF2 "Alive counter";
CM_ SG_ 649 AxOutStatus "Longitudinal acceleration status";
CM_ SG_ 649 QU_VYAW_VEH "Qualifier yaw velocity vehicle. All not defined values are reserved.";
CM_ SG_ 649 AyOutStatus "Lateral acceleration status";
CM_ SG_ 649 AcceleratorY "Lateral acceleration";
CM_ SG_ 649 AcceleratorX "Longitudinal acceleration";
CM_ SG_ 649 VYAW_VEH "Yaw velocity vehicle";
CM_ SG_ 654 CHKSM_APM_WINDOW_POS "Checksum";
CM_ SG_ 654 ALV_APM_WINDOW_POS "Alive counter";
CM_ SG_ 654 Window_PosFL "Front left window position";
CM_ SG_ 654 Window_Warning "Warning for window not closed";
CM_ SG_ 654 Wndow_PosRL "Rear left window position";
CM_ SG_ 654 Window_PosFR "Front right window position";
CM_ SG_ 654 Global_close "All windows close";
CM_ SG_ 654 Global_open "All windows open";
CM_ SG_ 654 Window_PosRR "Rear right window position";

BA_DEF_ BO_  "GenMsgSendType" ENUM "Cyclic","NotUsed","NotUsed","NotUsed","NotUsed","NotUsed","NotUsed","IfActive","NoMsgSendType","NotUsed";
BA_DEF_ BO_  "GenMsgILSupport" ENUM "No","Yes";
BA_DEF_ BO_  "DiagResponse" ENUM "No","Yes";
BA_DEF_ BO_  "DiagRequest" ENUM "No","Yes";
BA_DEF_ BO_  "NmAsrMessage" ENUM "No","Yes";
BA_DEF_ BO_  "DiagState" ENUM "No","Yes";
BA_DEF_ BO_  "DiagUudtResponse" ENUM "False","True";
BA_DEF_ BO_  "GenMsgStartDelayTime" INT 0 65535;
BA_DEF_ BO_  "GenMsgDelayTime" INT 0 0;
BA_DEF_ BO_  "GenMsgNrOfRepetition" INT 0 0;
BA_DEF_ BO_  "GenMsgCycleTimeFast" INT 0 0;
BA_DEF_ BO_  "GenMsgCycleTime" INT 0 0;
BA_DEF_ SG_  "GenSigSendType" ENUM "Cyclic","OnWrite","OnWriteWithRepetition","OnChange","OnChangeWithRepetition","IfActive","IfActiveWithRepetition","NoSigSendType","NotUsed","NotUsed","NotUsed","NotUsed","NotUsed";
BA_DEF_ SG_  "InvalidValue" STRING;
BA_DEF_ SG_  "GenSigStartValue" INT 0 0;
BA_DEF_ SG_  "GenSigTimeoutTime_ALL" INT 0 65535;
BA_DEF_DEF_  "DiagRequest" "No";
BA_DEF_DEF_  "DiagResponse" "No";
BA_DEF_DEF_  "DiagState" "No";
BA_DEF_DEF_  "DiagUudtResponse" "False";
BA_DEF_DEF_  "GenMsgCycleTime" 0;
BA_DEF_DEF_  "GenMsgCycleTimeFast" 0;
BA_DEF_DEF_  "GenMsgDelayTime" 0;
BA_DEF_DEF_  "GenMsgILSupport" "Yes";
BA_DEF_DEF_  "GenMsgNrOfRepetition" 0;
BA_DEF_DEF_  "GenMsgSendType" "NoMsgSendType";
BA_DEF_DEF_  "GenMsgStartDelayTime" 0;
BA_DEF_DEF_  "GenSigSendType" "Cyclic";
BA_DEF_DEF_  "GenSigStartValue" 0;
BA_DEF_DEF_  "GenSigTimeoutTime_ALL" 0;
BA_DEF_DEF_  "NmAsrMessage" "No";
BA_ "GenMsgCycleTime" BO_ 387 100;
BA_ "GenMsgSendType" BO_ 387 0;
BA_ "GenMsgSendType" BO_ 388 0;
BA_ "GenMsgCycleTime" BO_ 388 50;
BA_ "GenMsgCycleTime" BO_ 389 100;
BA_ "GenMsgSendType" BO_ 389 0;
BA_ "GenMsgCycleTime" BO_ 400 40;
BA_ "GenMsgSendType" BO_ 400 0;
BA_ "GenMsgCycleTime" BO_ 401 40;
BA_ "GenMsgSendType" BO_ 401 0;
BA_ "GenMsgCycleTime" BO_ 404 40;
BA_ "GenMsgSendType" BO_ 404 0;
BA_ "GenMsgCycleTime" BO_ 406 40;
BA_ "GenMsgSendType" BO_ 406 0;
BA_ "GenMsgCycleTime" BO_ 409 1000;
BA_ "GenMsgILSupport" BO_ 409 0;
BA_ "GenMsgSendType" BO_ 409 0;
BA_ "GenMsgCycleTime" BO_ 410 40;
BA_ "GenMsgSendType" BO_ 410 0;
BA_ "GenMsgCycleTime" BO_ 412 40;
BA_ "GenMsgSendType" BO_ 412 0;
BA_ "GenMsgCycleTime" BO_ 413 40;
BA_ "GenMsgSendType" BO_ 413 0;
BA_ "GenMsgCycleTime" BO_ 414 40;
BA_ "GenMsgSendType" BO_ 414 0;
BA_ "GenMsgCycleTime" BO_ 415 40;
BA_ "GenMsgSendType" BO_ 415 0;
BA_ "GenMsgCycleTime" BO_ 417 100;
BA_ "GenMsgSendType" BO_ 417 0;
BA_ "GenMsgCycleTime" BO_ 504 40;
BA_ "GenMsgSendType" BO_ 504 0;
BA_ "GenMsgCycleTime" BO_ 505 40;
BA_ "GenMsgSendType" BO_ 505 0;
BA_ "GenMsgCycleTime" BO_ 515 100;
BA_ "GenMsgSendType" BO_ 515 0;
BA_ "GenMsgCycleTime" BO_ 516 100;
BA_ "GenMsgSendType" BO_ 516 0;
BA_ "GenMsgCycleTime" BO_ 517 20;
BA_ "GenMsgILSupport" BO_ 517 0;
BA_ "GenMsgSendType" BO_ 517 0;
BA_ "GenMsgCycleTime" BO_ 518 50;
BA_ "GenMsgSendType" BO_ 518 0;
BA_ "GenMsgCycleTime" BO_ 519 100;
BA_ "GenMsgSendType" BO_ 519 0;
BA_ "GenMsgCycleTime" BO_ 520 100;
BA_ "GenMsgSendType" BO_ 520 0;
BA_ "GenMsgSendType" BO_ 521 0;
BA_ "GenMsgCycleTime" BO_ 521 100;
BA_ "GenMsgCycleTime" BO_ 522 100;
BA_ "GenMsgSendType" BO_ 522 0;
BA_ "GenMsgCycleTime" BO_ 523 100;
BA_ "GenMsgSendType" BO_ 523 0;
BA_ "GenMsgCycleTime" BO_ 524 100;
BA_ "GenMsgSendType" BO_ 524 0;
BA_ "GenMsgCycleTime" BO_ 525 40;
BA_ "GenMsgSendType" BO_ 525 0;
BA_ "GenMsgSendType" BO_ 526 0;
BA_ "GenMsgCycleTime" BO_ 526 50;
BA_ "GenMsgCycleTime" BO_ 527 50;
BA_ "GenMsgSendType" BO_ 527 0;
BA_ "GenMsgCycleTime" BO_ 531 100;
BA_ "GenMsgSendType" BO_ 531 0;
BA_ "GenMsgCycleTime" BO_ 532 50;
BA_ "GenMsgSendType" BO_ 532 0;
BA_ "GenMsgCycleTime" BO_ 533 50;
BA_ "GenMsgSendType" BO_ 533 0;
BA_ "GenMsgCycleTime" BO_ 534 50;
BA_ "GenMsgSendType" BO_ 534 0;
BA_ "GenMsgSendType" BO_ 538 0;
BA_ "GenMsgCycleTime" BO_ 538 100;
BA_ "GenMsgSendType" BO_ 539 0;
BA_ "GenMsgCycleTime" BO_ 539 10000;
BA_ "GenMsgSendType" BO_ 540 0;
BA_ "GenMsgCycleTime" BO_ 540 100;
BA_ "GenMsgCycleTimeFast" BO_ 544 50;
BA_ "GenMsgNrOfRepetition" BO_ 544 3;
BA_ "GenMsgCycleTime" BO_ 545 80;
BA_ "GenMsgSendType" BO_ 545 0;
BA_ "GenMsgCycleTime" BO_ 546 80;
BA_ "GenMsgSendType" BO_ 546 0;
BA_ "GenMsgCycleTime" BO_ 549 100;
BA_ "GenMsgILSupport" BO_ 549 0;
BA_ "GenMsgSendType" BO_ 549 0;
BA_ "GenMsgCycleTime" BO_ 561 80;
BA_ "GenMsgSendType" BO_ 561 0;
BA_ "GenMsgCycleTime" BO_ 565 100;
BA_ "GenMsgSendType" BO_ 565 0;
BA_ "GenMsgCycleTime" BO_ 569 80;
BA_ "GenMsgSendType" BO_ 569 0;
BA_ "GenMsgSendType" BO_ 570 0;
BA_ "GenMsgCycleTime" BO_ 570 100;
BA_ "GenMsgSendType" BO_ 571 0;
BA_ "GenMsgCycleTime" BO_ 571 100;
BA_ "GenMsgCycleTime" BO_ 581 150;
BA_ "GenMsgSendType" BO_ 581 0;
BA_ "GenMsgCycleTime" BO_ 584 80;
BA_ "GenMsgSendType" BO_ 584 0;
BA_ "GenMsgCycleTime" BO_ 585 10000;
BA_ "GenMsgILSupport" BO_ 585 0;
BA_ "GenMsgSendType" BO_ 585 0;
BA_ "GenMsgCycleTime" BO_ 588 10000;
BA_ "GenMsgILSupport" BO_ 588 0;
BA_ "GenMsgSendType" BO_ 588 0;
BA_ "GenMsgCycleTime" BO_ 596 100;
BA_ "GenMsgSendType" BO_ 596 0;
BA_ "GenMsgCycleTime" BO_ 597 100;
BA_ "GenMsgSendType" BO_ 597 0;
BA_ "GenMsgSendType" BO_ 620 0;
BA_ "GenMsgCycleTime" BO_ 620 100;
BA_ "GenMsgSendType" BO_ 640 0;
BA_ "GenMsgCycleTime" BO_ 640 50;
BA_ "GenMsgCycleTime" BO_ 641 80;
BA_ "GenMsgSendType" BO_ 641 0;
BA_ "GenMsgSendType" BO_ 642 0;
BA_ "GenMsgCycleTime" BO_ 642 50;
BA_ "GenMsgSendType" BO_ 643 0;
BA_ "GenMsgCycleTime" BO_ 643 50;
BA_ "GenMsgSendType" BO_ 644 0;
BA_ "GenMsgCycleTime" BO_ 644 50;
BA_ "GenMsgSendType" BO_ 649 0;
BA_ "GenMsgCycleTime" BO_ 649 20;
BA_ "GenMsgCycleTime" BO_ 654 100;
BA_ "GenMsgSendType" BO_ 654 0;
BA_ "GenSigTimeoutTime_ALL" SG_ 387 VCU_FS_B_1 1000;
BA_ "InvalidValue" SG_ 387 VCU_FS_B_1 "1h";
BA_ "GenSigTimeoutTime_ALL" SG_ 387 VCU_FS_B_2 1000;
BA_ "InvalidValue" SG_ 387 VCU_FS_B_2 "1h";
BA_ "GenSigTimeoutTime_ALL" SG_ 387 VCU_FS_B_3 1000;
BA_ "InvalidValue" SG_ 387 VCU_FS_B_3 "1h";
BA_ "GenSigTimeoutTime_ALL" SG_ 387 VCU_FS_B_4 1000;
BA_ "InvalidValue" SG_ 387 VCU_FS_B_4 "1h";
BA_ "GenSigTimeoutTime_ALL" SG_ 387 VCU_FS_B_5 1000;
BA_ "InvalidValue" SG_ 387 VCU_FS_B_5 "1h";
BA_ "GenSigTimeoutTime_ALL" SG_ 387 VCU_FS_B_6 1000;
BA_ "InvalidValue" SG_ 387 VCU_FS_B_6 "1h";
BA_ "GenSigTimeoutTime_ALL" SG_ 387 VCU_FS_B_7 1000;
BA_ "InvalidValue" SG_ 387 VCU_FS_B_7 "1h";
BA_ "GenSigTimeoutTime_ALL" SG_ 387 VCU_FS_B_8 1000;
BA_ "InvalidValue" SG_ 387 VCU_FS_B_8 "1h";
BA_ "GenSigTimeoutTime_ALL" SG_ 387 VCU_FS_B_9 1000;
BA_ "InvalidValue" SG_ 387 VCU_FS_B_9 "1h";
BA_ "GenSigTimeoutTime_ALL" SG_ 387 VCU_FS_B_10 1000;
BA_ "InvalidValue" SG_ 387 VCU_FS_B_10 "1h";
BA_ "GenSigTimeoutTime_ALL" SG_ 387 VCU_FS_B_11 1000;
BA_ "InvalidValue" SG_ 387 VCU_FS_B_11 "1h";
BA_ "GenSigTimeoutTime_ALL" SG_ 387 VCU_FS_B_12 1000;
BA_ "InvalidValue" SG_ 387 VCU_FS_B_12 "1h";
BA_ "GenSigTimeoutTime_ALL" SG_ 387 VCU_FS_B_13 1000;
BA_ "InvalidValue" SG_ 387 VCU_FS_B_13 "1h";
BA_ "GenSigTimeoutTime_ALL" SG_ 387 VCU_FS_B_14 1000;
BA_ "InvalidValue" SG_ 387 VCU_FS_B_14 "1h";
BA_ "GenSigTimeoutTime_ALL" SG_ 387 VCU_FS_B_15 1000;
BA_ "InvalidValue" SG_ 387 VCU_FS_B_15 "1h";
BA_ "GenSigTimeoutTime_ALL" SG_ 387 VCU_FS_B_16 1000;
BA_ "InvalidValue" SG_ 387 VCU_FS_B_16 "1h";
BA_ "GenSigTimeoutTime_ALL" SG_ 387 VCU_FS_B_17 1000;
BA_ "InvalidValue" SG_ 387 VCU_FS_B_17 "1h";
BA_ "GenSigTimeoutTime_ALL" SG_ 387 VCU_FS_B_18 1000;
BA_ "InvalidValue" SG_ 387 VCU_FS_B_18 "1h";
BA_ "GenSigTimeoutTime_ALL" SG_ 387 VCU_FS_B_19 1000;
BA_ "InvalidValue" SG_ 387 VCU_FS_B_19 "1h";
BA_ "GenSigTimeoutTime_ALL" SG_ 387 VCU_FS_B_20 1000;
BA_ "InvalidValue" SG_ 387 VCU_FS_B_20 "1h";
BA_ "GenSigTimeoutTime_ALL" SG_ 387 VCU_FS_B_21 1000;
BA_ "InvalidValue" SG_ 387 VCU_FS_B_21 "1h";
BA_ "GenSigTimeoutTime_ALL" SG_ 387 VCU_FS_B_22 1000;
BA_ "InvalidValue" SG_ 387 VCU_FS_B_22 "1h";
BA_ "GenSigTimeoutTime_ALL" SG_ 387 VCU_FS_B_23 1000;
BA_ "InvalidValue" SG_ 387 VCU_FS_B_23 "1h";
BA_ "GenSigTimeoutTime_ALL" SG_ 387 VCU_FS_B_24 1000;
BA_ "InvalidValue" SG_ 387 VCU_FS_B_24 "1h";
BA_ "GenSigTimeoutTime_ALL" SG_ 387 VCU_FS_B_25 1000;
BA_ "InvalidValue" SG_ 387 VCU_FS_B_25 "1h";
BA_ "GenSigTimeoutTime_ALL" SG_ 387 VCU_FS_B_26 1000;
BA_ "InvalidValue" SG_ 387 VCU_FS_B_26 "1h";
BA_ "GenSigTimeoutTime_ALL" SG_ 387 VCU_FS_B_27 1000;
BA_ "InvalidValue" SG_ 387 VCU_FS_B_27 "1h";
BA_ "GenSigTimeoutTime_ALL" SG_ 387 VCU_FS_B_28 1000;
BA_ "InvalidValue" SG_ 387 VCU_FS_B_28 "1h";
BA_ "GenSigTimeoutTime_ALL" SG_ 387 VCU_FS_B_29 1000;
BA_ "InvalidValue" SG_ 387 VCU_FS_B_29 "1h";
BA_ "GenSigTimeoutTime_ALL" SG_ 387 VCU_FS_B_30 1000;
BA_ "InvalidValue" SG_ 387 VCU_FS_B_30 "1h";
BA_ "GenSigTimeoutTime_ALL" SG_ 387 VCU_FS_B_31 1000;
BA_ "InvalidValue" SG_ 387 VCU_FS_B_31 "1h";
BA_ "GenSigTimeoutTime_ALL" SG_ 387 VCU_FS_B_32 1000;
BA_ "InvalidValue" SG_ 387 VCU_FS_B_32 "1h";
BA_ "GenSigTimeoutTime_ALL" SG_ 387 VCU_FS_B_33 1000;
BA_ "InvalidValue" SG_ 387 VCU_FS_B_33 "1h";
BA_ "GenSigTimeoutTime_ALL" SG_ 387 VCU_FS_B_34 1000;
BA_ "InvalidValue" SG_ 387 VCU_FS_B_34 "1h";
BA_ "GenSigTimeoutTime_ALL" SG_ 387 VCU_FS_B_35 1000;
BA_ "InvalidValue" SG_ 387 VCU_FS_B_35 "1h";
BA_ "GenSigTimeoutTime_ALL" SG_ 387 VCU_FS_B_36 1000;
BA_ "InvalidValue" SG_ 387 VCU_FS_B_36 "1h";
BA_ "GenSigTimeoutTime_ALL" SG_ 387 VCU_FS_B_37 1000;
BA_ "InvalidValue" SG_ 387 VCU_FS_B_37 "1h";
BA_ "GenSigTimeoutTime_ALL" SG_ 387 VCU_FS_B_38 1000;
BA_ "InvalidValue" SG_ 387 VCU_FS_B_38 "1h";
BA_ "GenSigTimeoutTime_ALL" SG_ 387 VCU_FS_B_39 1000;
BA_ "InvalidValue" SG_ 387 VCU_FS_B_39 "1h";
BA_ "GenSigTimeoutTime_ALL" SG_ 387 VCU_FS_B_40 1000;
BA_ "InvalidValue" SG_ 387 VCU_FS_B_40 "1h";
BA_ "GenSigTimeoutTime_ALL" SG_ 387 VCU_FS_B_41 1000;
BA_ "InvalidValue" SG_ 387 VCU_FS_B_41 "1h";
BA_ "GenSigTimeoutTime_ALL" SG_ 387 VCU_FS_B_42 1000;
BA_ "InvalidValue" SG_ 387 VCU_FS_B_42 "1h";
BA_ "GenSigTimeoutTime_ALL" SG_ 387 VCU_FS_B_43 1000;
BA_ "InvalidValue" SG_ 387 VCU_FS_B_43 "1h";
BA_ "GenSigTimeoutTime_ALL" SG_ 387 VCU_FS_B_44 1000;
BA_ "InvalidValue" SG_ 387 VCU_FS_B_44 "1h";
BA_ "GenSigTimeoutTime_ALL" SG_ 387 VCU_FS_B_45 1000;
BA_ "InvalidValue" SG_ 387 VCU_FS_B_45 "1h";
BA_ "GenSigTimeoutTime_ALL" SG_ 387 VCU_FS_B_46 1000;
BA_ "InvalidValue" SG_ 387 VCU_FS_B_46 "1h";
BA_ "GenSigTimeoutTime_ALL" SG_ 387 VCU_FS_B_47 1000;
BA_ "InvalidValue" SG_ 387 VCU_FS_B_47 "1h";
BA_ "GenSigTimeoutTime_ALL" SG_ 387 VCU_FS_B_48 1000;
BA_ "InvalidValue" SG_ 387 VCU_FS_B_48 "1h";
BA_ "GenSigTimeoutTime_ALL" SG_ 387 VCU_FS_B_49 1000;
BA_ "InvalidValue" SG_ 387 VCU_FS_B_49 "1h";
BA_ "GenSigTimeoutTime_ALL" SG_ 387 VCU_FS_B_50 1000;
BA_ "InvalidValue" SG_ 387 VCU_FS_B_50 "1h";
BA_ "GenSigTimeoutTime_ALL" SG_ 387 VCU_FS_B_51 1000;
BA_ "InvalidValue" SG_ 387 VCU_FS_B_51 "1h";
BA_ "GenSigTimeoutTime_ALL" SG_ 387 VCU_FS_B_52 1000;
BA_ "InvalidValue" SG_ 387 VCU_FS_B_52 "1h";
BA_ "GenSigTimeoutTime_ALL" SG_ 387 VCU_FS_B_53 1000;
BA_ "InvalidValue" SG_ 387 VCU_FS_B_53 "1h";
BA_ "GenSigTimeoutTime_ALL" SG_ 387 VCU_FS_B_54 1000;
BA_ "InvalidValue" SG_ 387 VCU_FS_B_54 "1h";
BA_ "GenSigTimeoutTime_ALL" SG_ 387 VCU_FS_B_55 1000;
BA_ "InvalidValue" SG_ 387 VCU_FS_B_55 "1h";
BA_ "GenSigTimeoutTime_ALL" SG_ 387 VCU_FS_B_56 1000;
BA_ "InvalidValue" SG_ 387 VCU_FS_B_56 "1h";
BA_ "GenSigTimeoutTime_ALL" SG_ 387 VCU_FS_B_57 1000;
BA_ "InvalidValue" SG_ 387 VCU_FS_B_57 "1h";
BA_ "GenSigTimeoutTime_ALL" SG_ 387 VCU_FS_B_58 1000;
BA_ "InvalidValue" SG_ 387 VCU_FS_B_58 "1h";
BA_ "GenSigTimeoutTime_ALL" SG_ 387 VCU_FS_B_59 1000;
BA_ "InvalidValue" SG_ 387 VCU_FS_B_59 "1h";
BA_ "GenSigTimeoutTime_ALL" SG_ 387 VCU_FS_B_60 1000;
BA_ "InvalidValue" SG_ 387 VCU_FS_B_60 "1h";
BA_ "GenSigTimeoutTime_ALL" SG_ 387 VCU_FS_B_61 1000;
BA_ "InvalidValue" SG_ 387 VCU_FS_B_61 "1h";
BA_ "GenSigTimeoutTime_ALL" SG_ 387 VCU_FS_B_62 1000;
BA_ "InvalidValue" SG_ 387 VCU_FS_B_62 "1h";
BA_ "GenSigTimeoutTime_ALL" SG_ 387 VCU_FS_B_63 1000;
BA_ "InvalidValue" SG_ 387 VCU_FS_B_63 "1h";
BA_ "GenSigTimeoutTime_ALL" SG_ 387 VCU_FS_B_64 1000;
BA_ "InvalidValue" SG_ 387 VCU_FS_B_64 "1h";
BA_ "GenSigTimeoutTime_ALL" SG_ 388 CHKSM_FCAM_BCM_Status 500;
BA_ "GenSigTimeoutTime_ALL" SG_ 388 ALIVE_FCAM_BCM_Status 500;
BA_ "InvalidValue" SG_ 388 ALIVE_FCAM_BCM_Status "Fh";
BA_ "GenSigTimeoutTime_ALL" SG_ 388 FCAM_BCM_IndicatorlightReq 500;
BA_ "GenSigTimeoutTime_ALL" SG_ 388 SECCAN_FCAM_BCM_Sts 500;
BA_ "GenSigTimeoutTime_ALL" SG_ 389 VCU_FS_C_1 1000;
BA_ "GenSigTimeoutTime_ALL" SG_ 389 VCU_FS_C_2 1000;
BA_ "GenSigTimeoutTime_ALL" SG_ 389 VCU_FS_C_3 1000;
BA_ "GenSigTimeoutTime_ALL" SG_ 389 VCU_FS_C_4 1000;
BA_ "GenSigTimeoutTime_ALL" SG_ 389 VCU_FS_C_5 1000;
BA_ "GenSigTimeoutTime_ALL" SG_ 389 VCU_FS_C_6 1000;
BA_ "GenSigTimeoutTime_ALL" SG_ 389 VCU_FS_C_7 1000;
BA_ "GenSigTimeoutTime_ALL" SG_ 389 VCU_FS_C_8 1000;
BA_ "GenSigTimeoutTime_ALL" SG_ 389 VCU_FS_C_9 1000;
BA_ "GenSigTimeoutTime_ALL" SG_ 389 VCU_FS_C_10 1000;
BA_ "GenSigTimeoutTime_ALL" SG_ 389 VCU_FS_C_11 1000;
BA_ "GenSigTimeoutTime_ALL" SG_ 389 VCU_FS_C_12 1000;
BA_ "GenSigTimeoutTime_ALL" SG_ 389 VCU_FS_C_13 1000;
BA_ "GenSigTimeoutTime_ALL" SG_ 389 VCU_FS_C_14 1000;
BA_ "GenSigTimeoutTime_ALL" SG_ 389 VCU_FS_C_15 1000;
BA_ "GenSigTimeoutTime_ALL" SG_ 389 VCU_FS_C_16 1000;
BA_ "GenSigTimeoutTime_ALL" SG_ 389 VCU_FS_C_17 1000;
BA_ "GenSigTimeoutTime_ALL" SG_ 389 VCU_FS_C_18 1000;
BA_ "GenSigTimeoutTime_ALL" SG_ 389 VCU_FS_C_19 1000;
BA_ "GenSigTimeoutTime_ALL" SG_ 389 VCU_FS_C_20 1000;
BA_ "GenSigTimeoutTime_ALL" SG_ 389 VCU_FS_C_21 1000;
BA_ "GenSigTimeoutTime_ALL" SG_ 389 VCU_FS_C_22 1000;
BA_ "GenSigTimeoutTime_ALL" SG_ 389 VCU_FS_C_23 1000;
BA_ "GenSigTimeoutTime_ALL" SG_ 389 VCU_FS_C_24 1000;
BA_ "GenSigTimeoutTime_ALL" SG_ 389 VCU_FS_C_25 1000;
BA_ "GenSigTimeoutTime_ALL" SG_ 389 VCU_FS_C_26 1000;
BA_ "GenSigTimeoutTime_ALL" SG_ 389 VCU_FS_C_27 1000;
BA_ "GenSigTimeoutTime_ALL" SG_ 389 VCU_FS_C_28 1000;
BA_ "GenSigTimeoutTime_ALL" SG_ 389 VCU_FS_C_29 1000;
BA_ "GenSigTimeoutTime_ALL" SG_ 389 VCU_FS_C_30 1000;
BA_ "GenSigTimeoutTime_ALL" SG_ 389 VCU_FS_C_31 1000;
BA_ "GenSigTimeoutTime_ALL" SG_ 389 VCU_FS_C_32 1000;
BA_ "GenSigTimeoutTime_ALL" SG_ 389 VCU_FS_C_33 1000;
BA_ "GenSigTimeoutTime_ALL" SG_ 389 VCU_FS_C_34 1000;
BA_ "GenSigTimeoutTime_ALL" SG_ 389 VCU_FS_C_35 1000;
BA_ "GenSigTimeoutTime_ALL" SG_ 389 VCU_FS_C_36 1000;
BA_ "GenSigTimeoutTime_ALL" SG_ 389 VCU_FS_C_37 1000;
BA_ "GenSigTimeoutTime_ALL" SG_ 389 VCU_FS_C_38 1000;
BA_ "GenSigTimeoutTime_ALL" SG_ 389 VCU_FS_C_39 1000;
BA_ "GenSigTimeoutTime_ALL" SG_ 389 VCU_FS_C_40 1000;
BA_ "GenSigTimeoutTime_ALL" SG_ 389 VCU_FS_C_41 1000;
BA_ "GenSigTimeoutTime_ALL" SG_ 389 VCU_FS_C_42 1000;
BA_ "GenSigTimeoutTime_ALL" SG_ 389 VCU_FS_C_43 1000;
BA_ "GenSigTimeoutTime_ALL" SG_ 389 VCU_FS_C_44 1000;
BA_ "GenSigTimeoutTime_ALL" SG_ 389 VCU_FS_C_45 1000;
BA_ "GenSigTimeoutTime_ALL" SG_ 389 VCU_FS_C_46 1000;
BA_ "GenSigTimeoutTime_ALL" SG_ 389 VCU_FS_C_47 1000;
BA_ "GenSigTimeoutTime_ALL" SG_ 389 VCU_FS_C_48 1000;
BA_ "GenSigTimeoutTime_ALL" SG_ 389 VCU_FS_C_49 1000;
BA_ "GenSigTimeoutTime_ALL" SG_ 389 VCU_FS_C_50 1000;
BA_ "GenSigTimeoutTime_ALL" SG_ 389 VCU_FS_C_51 1000;
BA_ "GenSigTimeoutTime_ALL" SG_ 389 VCU_FS_C_52 1000;
BA_ "GenSigTimeoutTime_ALL" SG_ 389 VCU_FS_C_53 1000;
BA_ "GenSigTimeoutTime_ALL" SG_ 389 VCU_FS_C_54 1000;
BA_ "GenSigTimeoutTime_ALL" SG_ 389 VCU_FS_C_55 1000;
BA_ "GenSigTimeoutTime_ALL" SG_ 389 VCU_FS_C_56 1000;
BA_ "GenSigTimeoutTime_ALL" SG_ 389 VCU_FS_C_57 1000;
BA_ "GenSigTimeoutTime_ALL" SG_ 389 VCU_FS_C_58 1000;
BA_ "GenSigTimeoutTime_ALL" SG_ 389 VCU_FS_C_59 1000;
BA_ "GenSigTimeoutTime_ALL" SG_ 389 VCU_FS_C_60 1000;
BA_ "GenSigTimeoutTime_ALL" SG_ 389 VCU_FS_C_61 1000;
BA_ "GenSigTimeoutTime_ALL" SG_ 389 VCU_FS_C_62 1000;
BA_ "GenSigTimeoutTime_ALL" SG_ 389 VCU_FS_C_63 1000;
BA_ "GenSigTimeoutTime_ALL" SG_ 389 VCU_FS_C_64 1000;
BA_ "GenSigTimeoutTime_ALL" SG_ 400 CAM_CamSts 400;
BA_ "GenSigTimeoutTime_ALL" SG_ 400 CAM_AmbLi 400;
BA_ "GenSigTimeoutTime_ALL" SG_ 400 CAM_RoadIllmn 400;
BA_ "GenSigTimeoutTime_ALL" SG_ 400 CAM_Obj_TrfcStyle 400;
BA_ "GenSigTimeoutTime_ALL" SG_ 401 CAM_Obj1_ID 400;
BA_ "InvalidValue" SG_ 401 CAM_Obj1_ID "0";
BA_ "GenSigStartValue" SG_ 401 CAM_Obj1_HozlDst 511;
BA_ "GenSigTimeoutTime_ALL" SG_ 401 CAM_Obj1_HozlDst 400;
BA_ "InvalidValue" SG_ 401 CAM_Obj1_HozlDst "1FFh";
BA_ "GenSigTimeoutTime_ALL" SG_ 401 CAM_Obj1_Valid 400;
BA_ "InvalidValue" SG_ 401 CAM_Obj1_Valid "0";
BA_ "GenSigStartValue" SG_ 401 CAM_Obj1_HozlPosnRi 500;
BA_ "GenSigTimeoutTime_ALL" SG_ 401 CAM_Obj1_HozlPosnRi 400;
BA_ "InvalidValue" SG_ 401 CAM_Obj1_HozlPosnRi "3FFh";
BA_ "GenSigTimeoutTime_ALL" SG_ 401 CAM_Obj1_Typ 400;
BA_ "InvalidValue" SG_ 401 CAM_Obj1_Typ "0";
BA_ "GenSigStartValue" SG_ 401 CAM_Obj1_HozlPosnLe 500;
BA_ "GenSigTimeoutTime_ALL" SG_ 401 CAM_Obj1_HozlPosnLe 400;
BA_ "InvalidValue" SG_ 401 CAM_Obj1_HozlPosnLe "3FFh";
BA_ "GenSigStartValue" SG_ 401 CAM_Obj1_VertPosn 120;
BA_ "GenSigTimeoutTime_ALL" SG_ 401 CAM_Obj1_VertPosn 400;
BA_ "GenSigStartValue" SG_ 401 CAM_Obj1_HozlSpdLe 128;
BA_ "GenSigTimeoutTime_ALL" SG_ 401 CAM_Obj1_HozlSpdLe 400;
BA_ "InvalidValue" SG_ 401 CAM_Obj1_HozlSpdLe "null";
BA_ "GenSigStartValue" SG_ 401 CAM_Obj1_HozlSpdRi 128;
BA_ "GenSigTimeoutTime_ALL" SG_ 401 CAM_Obj1_HozlSpdRi 400;
BA_ "InvalidValue" SG_ 401 CAM_Obj1_HozlSpdRi "null";
BA_ "GenSigTimeoutTime_ALL" SG_ 404 CAM_Obj2_ID 400;
BA_ "InvalidValue" SG_ 404 CAM_Obj2_ID "0";
BA_ "GenSigStartValue" SG_ 404 CAM_Obj2_HozlDst 511;
BA_ "GenSigTimeoutTime_ALL" SG_ 404 CAM_Obj2_HozlDst 400;
BA_ "InvalidValue" SG_ 404 CAM_Obj2_HozlDst "1FFh";
BA_ "GenSigTimeoutTime_ALL" SG_ 404 CAM_Obj2_Valid 400;
BA_ "InvalidValue" SG_ 404 CAM_Obj2_Valid "0";
BA_ "GenSigStartValue" SG_ 404 CAM_Obj2_HozlPosnRi 500;
BA_ "GenSigTimeoutTime_ALL" SG_ 404 CAM_Obj2_HozlPosnRi 400;
BA_ "InvalidValue" SG_ 404 CAM_Obj2_HozlPosnRi "3FFh";
BA_ "GenSigTimeoutTime_ALL" SG_ 404 CAM_Obj2_Typ 400;
BA_ "InvalidValue" SG_ 404 CAM_Obj2_Typ "0";
BA_ "GenSigStartValue" SG_ 404 CAM_Obj2_HozlPosnLe 500;
BA_ "GenSigTimeoutTime_ALL" SG_ 404 CAM_Obj2_HozlPosnLe 400;
BA_ "InvalidValue" SG_ 404 CAM_Obj2_HozlPosnLe "3FFh";
BA_ "GenSigStartValue" SG_ 404 CAM_Obj2_VertPosn 120;
BA_ "GenSigTimeoutTime_ALL" SG_ 404 CAM_Obj2_VertPosn 400;
BA_ "GenSigStartValue" SG_ 404 CAM_Obj2_HozlSpdLe 128;
BA_ "GenSigTimeoutTime_ALL" SG_ 404 CAM_Obj2_HozlSpdLe 400;
BA_ "InvalidValue" SG_ 404 CAM_Obj2_HozlSpdLe "null";
BA_ "GenSigStartValue" SG_ 404 CAM_Obj2_HozlSpdRi 128;
BA_ "GenSigTimeoutTime_ALL" SG_ 404 CAM_Obj2_HozlSpdRi 400;
BA_ "InvalidValue" SG_ 404 CAM_Obj2_HozlSpdRi "null";
BA_ "GenSigTimeoutTime_ALL" SG_ 406 CAM_Obj3_ID 400;
BA_ "InvalidValue" SG_ 406 CAM_Obj3_ID "0";
BA_ "GenSigStartValue" SG_ 406 CAM_Obj3_HozlDst 511;
BA_ "GenSigTimeoutTime_ALL" SG_ 406 CAM_Obj3_HozlDst 400;
BA_ "InvalidValue" SG_ 406 CAM_Obj3_HozlDst "1FFh";
BA_ "GenSigTimeoutTime_ALL" SG_ 406 CAM_Obj3_Valid 400;
BA_ "InvalidValue" SG_ 406 CAM_Obj3_Valid "0";
BA_ "GenSigStartValue" SG_ 406 CAM_Obj3_HozlPosnRi 500;
BA_ "GenSigTimeoutTime_ALL" SG_ 406 CAM_Obj3_HozlPosnRi 400;
BA_ "InvalidValue" SG_ 406 CAM_Obj3_HozlPosnRi "3FFh";
BA_ "GenSigTimeoutTime_ALL" SG_ 406 CAM_Obj3_Typ 400;
BA_ "InvalidValue" SG_ 406 CAM_Obj3_Typ "0";
BA_ "GenSigStartValue" SG_ 406 CAM_Obj3_HozlPosnLe 500;
BA_ "GenSigTimeoutTime_ALL" SG_ 406 CAM_Obj3_HozlPosnLe 400;
BA_ "InvalidValue" SG_ 406 CAM_Obj3_HozlPosnLe "3FFh";
BA_ "GenSigStartValue" SG_ 406 CAM_Obj3_VertPosn 120;
BA_ "GenSigTimeoutTime_ALL" SG_ 406 CAM_Obj3_VertPosn 400;
BA_ "GenSigStartValue" SG_ 406 CAM_Obj3_HozlSpdLe 128;
BA_ "GenSigTimeoutTime_ALL" SG_ 406 CAM_Obj3_HozlSpdLe 400;
BA_ "InvalidValue" SG_ 406 CAM_Obj3_HozlSpdLe "null";
BA_ "GenSigStartValue" SG_ 406 CAM_Obj3_HozlSpdRi 128;
BA_ "GenSigTimeoutTime_ALL" SG_ 406 CAM_Obj3_HozlSpdRi 400;
BA_ "InvalidValue" SG_ 406 CAM_Obj3_HozlSpdRi "null";
BA_ "GenSigTimeoutTime_ALL" SG_ 409 CHSKM_VCU_Sts1 5000;
BA_ "InvalidValue" SG_ 409 CHSKM_VCU_Sts1 "null";
BA_ "GenSigTimeoutTime_ALL" SG_ 409 ALV_VCU_Sts1 5000;
BA_ "InvalidValue" SG_ 409 ALV_VCU_Sts1 "Fh";
BA_ "GenSigTimeoutTime_ALL" SG_ 409 VCU_BMS_HVOnOff_REQ 5000;
BA_ "InvalidValue" SG_ 409 VCU_BMS_HVOnOff_REQ "null";
BA_ "GenSigTimeoutTime_ALL" SG_ 410 CAM_Obj4_ID 400;
BA_ "InvalidValue" SG_ 410 CAM_Obj4_ID "0";
BA_ "GenSigStartValue" SG_ 410 CAM_Obj4_HozlDst 511;
BA_ "GenSigTimeoutTime_ALL" SG_ 410 CAM_Obj4_HozlDst 400;
BA_ "InvalidValue" SG_ 410 CAM_Obj4_HozlDst "1FFh";
BA_ "GenSigTimeoutTime_ALL" SG_ 410 CAM_Obj4_Valid 400;
BA_ "InvalidValue" SG_ 410 CAM_Obj4_Valid "0";
BA_ "GenSigStartValue" SG_ 410 CAM_Obj4_HozlPosnRi 500;
BA_ "GenSigTimeoutTime_ALL" SG_ 410 CAM_Obj4_HozlPosnRi 400;
BA_ "InvalidValue" SG_ 410 CAM_Obj4_HozlPosnRi "3FFh";
BA_ "GenSigTimeoutTime_ALL" SG_ 410 CAM_Obj4_Typ 400;
BA_ "InvalidValue" SG_ 410 CAM_Obj4_Typ "0";
BA_ "GenSigStartValue" SG_ 410 CAM_Obj4_HozlPosnLe 500;
BA_ "GenSigTimeoutTime_ALL" SG_ 410 CAM_Obj4_HozlPosnLe 400;
BA_ "InvalidValue" SG_ 410 CAM_Obj4_HozlPosnLe "3FFh";
BA_ "GenSigStartValue" SG_ 410 CAM_Obj4_VertPosn 120;
BA_ "GenSigTimeoutTime_ALL" SG_ 410 CAM_Obj4_VertPosn 400;
BA_ "GenSigStartValue" SG_ 410 CAM_Obj4_HozlSpdLe 128;
BA_ "GenSigTimeoutTime_ALL" SG_ 410 CAM_Obj4_HozlSpdLe 400;
BA_ "InvalidValue" SG_ 410 CAM_Obj4_HozlSpdLe "null";
BA_ "GenSigStartValue" SG_ 410 CAM_Obj4_HozlSpdRi 128;
BA_ "GenSigTimeoutTime_ALL" SG_ 410 CAM_Obj4_HozlSpdRi 400;
BA_ "InvalidValue" SG_ 410 CAM_Obj4_HozlSpdRi "null";
BA_ "GenSigTimeoutTime_ALL" SG_ 412 CAM_Obj5_ID 400;
BA_ "InvalidValue" SG_ 412 CAM_Obj5_ID "0";
BA_ "GenSigStartValue" SG_ 412 CAM_Obj5_HozlDst 511;
BA_ "GenSigTimeoutTime_ALL" SG_ 412 CAM_Obj5_HozlDst 400;
BA_ "InvalidValue" SG_ 412 CAM_Obj5_HozlDst "1FFh";
BA_ "GenSigTimeoutTime_ALL" SG_ 412 CAM_Obj5_Valid 400;
BA_ "InvalidValue" SG_ 412 CAM_Obj5_Valid "0";
BA_ "GenSigStartValue" SG_ 412 CAM_Obj5_HozlPosnRi 500;
BA_ "GenSigTimeoutTime_ALL" SG_ 412 CAM_Obj5_HozlPosnRi 400;
BA_ "InvalidValue" SG_ 412 CAM_Obj5_HozlPosnRi "3FFh";
BA_ "GenSigTimeoutTime_ALL" SG_ 412 CAM_Obj5_Typ 400;
BA_ "InvalidValue" SG_ 412 CAM_Obj5_Typ "0";
BA_ "GenSigStartValue" SG_ 412 CAM_Obj5_HozlPosnLe 500;
BA_ "GenSigTimeoutTime_ALL" SG_ 412 CAM_Obj5_HozlPosnLe 400;
BA_ "InvalidValue" SG_ 412 CAM_Obj5_HozlPosnLe "3FFh";
BA_ "GenSigStartValue" SG_ 412 CAM_Obj5_VertPosn 120;
BA_ "GenSigTimeoutTime_ALL" SG_ 412 CAM_Obj5_VertPosn 400;
BA_ "GenSigStartValue" SG_ 412 CAM_Obj5_HozlSpdLe 128;
BA_ "GenSigTimeoutTime_ALL" SG_ 412 CAM_Obj5_HozlSpdLe 400;
BA_ "InvalidValue" SG_ 412 CAM_Obj5_HozlSpdLe "null";
BA_ "GenSigStartValue" SG_ 412 CAM_Obj5_HozlSpdRi 128;
BA_ "GenSigTimeoutTime_ALL" SG_ 412 CAM_Obj5_HozlSpdRi 400;
BA_ "InvalidValue" SG_ 412 CAM_Obj5_HozlSpdRi "null";
BA_ "GenSigTimeoutTime_ALL" SG_ 413 CAM_Obj6_ID 400;
BA_ "InvalidValue" SG_ 413 CAM_Obj6_ID "0";
BA_ "GenSigStartValue" SG_ 413 CAM_Obj6_HozlDst 511;
BA_ "GenSigTimeoutTime_ALL" SG_ 413 CAM_Obj6_HozlDst 400;
BA_ "InvalidValue" SG_ 413 CAM_Obj6_HozlDst "1FFh";
BA_ "GenSigTimeoutTime_ALL" SG_ 413 CAM_Obj6_Valid 400;
BA_ "InvalidValue" SG_ 413 CAM_Obj6_Valid "0";
BA_ "GenSigStartValue" SG_ 413 CAM_Obj6_HozlPosnRi 500;
BA_ "GenSigTimeoutTime_ALL" SG_ 413 CAM_Obj6_HozlPosnRi 400;
BA_ "InvalidValue" SG_ 413 CAM_Obj6_HozlPosnRi "3FFh";
BA_ "GenSigTimeoutTime_ALL" SG_ 413 CAM_Obj6_Typ 400;
BA_ "InvalidValue" SG_ 413 CAM_Obj6_Typ "0";
BA_ "GenSigStartValue" SG_ 413 CAM_Obj6_HozlPosnLe 500;
BA_ "GenSigTimeoutTime_ALL" SG_ 413 CAM_Obj6_HozlPosnLe 400;
BA_ "InvalidValue" SG_ 413 CAM_Obj6_HozlPosnLe "3FFh";
BA_ "GenSigStartValue" SG_ 413 CAM_Obj6_VertPosn 120;
BA_ "GenSigTimeoutTime_ALL" SG_ 413 CAM_Obj6_VertPosn 400;
BA_ "GenSigStartValue" SG_ 413 CAM_Obj6_HozlSpdLe 128;
BA_ "GenSigTimeoutTime_ALL" SG_ 413 CAM_Obj6_HozlSpdLe 400;
BA_ "InvalidValue" SG_ 413 CAM_Obj6_HozlSpdLe "null";
BA_ "GenSigStartValue" SG_ 413 CAM_Obj6_HozlSpdRi 128;
BA_ "GenSigTimeoutTime_ALL" SG_ 413 CAM_Obj6_HozlSpdRi 400;
BA_ "InvalidValue" SG_ 413 CAM_Obj6_HozlSpdRi "null";
BA_ "GenSigTimeoutTime_ALL" SG_ 414 CAM_Obj7_ID 400;
BA_ "InvalidValue" SG_ 414 CAM_Obj7_ID "0";
BA_ "GenSigStartValue" SG_ 414 CAM_Obj7_HozlDst 511;
BA_ "GenSigTimeoutTime_ALL" SG_ 414 CAM_Obj7_HozlDst 400;
BA_ "InvalidValue" SG_ 414 CAM_Obj7_HozlDst "1FFh";
BA_ "GenSigTimeoutTime_ALL" SG_ 414 CAM_Obj7_Valid 400;
BA_ "InvalidValue" SG_ 414 CAM_Obj7_Valid "0";
BA_ "GenSigStartValue" SG_ 414 CAM_Obj7_HozlPosnRi 500;
BA_ "GenSigTimeoutTime_ALL" SG_ 414 CAM_Obj7_HozlPosnRi 400;
BA_ "InvalidValue" SG_ 414 CAM_Obj7_HozlPosnRi "3FFh";
BA_ "GenSigTimeoutTime_ALL" SG_ 414 CAM_Obj7_Typ 400;
BA_ "InvalidValue" SG_ 414 CAM_Obj7_Typ "0";
BA_ "GenSigStartValue" SG_ 414 CAM_Obj7_HozlPosnLe 500;
BA_ "GenSigTimeoutTime_ALL" SG_ 414 CAM_Obj7_HozlPosnLe 400;
BA_ "InvalidValue" SG_ 414 CAM_Obj7_HozlPosnLe "3FFh";
BA_ "GenSigStartValue" SG_ 414 CAM_Obj7_VertPosn 120;
BA_ "GenSigTimeoutTime_ALL" SG_ 414 CAM_Obj7_VertPosn 400;
BA_ "GenSigStartValue" SG_ 414 CAM_Obj7_HozlSpdLe 128;
BA_ "GenSigTimeoutTime_ALL" SG_ 414 CAM_Obj7_HozlSpdLe 400;
BA_ "InvalidValue" SG_ 414 CAM_Obj7_HozlSpdLe "null";
BA_ "GenSigStartValue" SG_ 414 CAM_Obj7_HozlSpdRi 128;
BA_ "GenSigTimeoutTime_ALL" SG_ 414 CAM_Obj7_HozlSpdRi 400;
BA_ "InvalidValue" SG_ 414 CAM_Obj7_HozlSpdRi "null";
BA_ "GenSigTimeoutTime_ALL" SG_ 415 CAM_Obj8_ID 400;
BA_ "InvalidValue" SG_ 415 CAM_Obj8_ID "0";
BA_ "GenSigStartValue" SG_ 415 CAM_Obj8_HozlDst 511;
BA_ "GenSigTimeoutTime_ALL" SG_ 415 CAM_Obj8_HozlDst 400;
BA_ "InvalidValue" SG_ 415 CAM_Obj8_HozlDst "1FFh";
BA_ "GenSigTimeoutTime_ALL" SG_ 415 CAM_Obj8_Valid 400;
BA_ "InvalidValue" SG_ 415 CAM_Obj8_Valid "0";
BA_ "GenSigStartValue" SG_ 415 CAM_Obj8_HozlPosnRi 500;
BA_ "GenSigTimeoutTime_ALL" SG_ 415 CAM_Obj8_HozlPosnRi 400;
BA_ "InvalidValue" SG_ 415 CAM_Obj8_HozlPosnRi "3FFh";
BA_ "GenSigTimeoutTime_ALL" SG_ 415 CAM_Obj8_Typ 400;
BA_ "InvalidValue" SG_ 415 CAM_Obj8_Typ "0";
BA_ "GenSigStartValue" SG_ 415 CAM_Obj8_HozlPosnLe 500;
BA_ "GenSigTimeoutTime_ALL" SG_ 415 CAM_Obj8_HozlPosnLe 400;
BA_ "InvalidValue" SG_ 415 CAM_Obj8_HozlPosnLe "3FFh";
BA_ "GenSigStartValue" SG_ 415 CAM_Obj8_VertPosn 120;
BA_ "GenSigTimeoutTime_ALL" SG_ 415 CAM_Obj8_VertPosn 400;
BA_ "GenSigStartValue" SG_ 415 CAM_Obj8_HozlSpdLe 128;
BA_ "GenSigTimeoutTime_ALL" SG_ 415 CAM_Obj8_HozlSpdLe 400;
BA_ "InvalidValue" SG_ 415 CAM_Obj8_HozlSpdLe "null";
BA_ "GenSigStartValue" SG_ 415 CAM_Obj8_HozlSpdRi 128;
BA_ "GenSigTimeoutTime_ALL" SG_ 415 CAM_Obj8_HozlSpdRi 400;
BA_ "InvalidValue" SG_ 415 CAM_Obj8_HozlSpdRi "null";
BA_ "GenSigTimeoutTime_ALL" SG_ 417 CHSKM_V_VEH 1000;
BA_ "InvalidValue" SG_ 417 CHSKM_V_VEH "";
BA_ "GenSigTimeoutTime_ALL" SG_ 417 ALIV_V_VEH 1000;
BA_ "InvalidValue" SG_ 417 ALIV_V_VEH "Fh";
BA_ "GenSigTimeoutTime_ALL" SG_ 417 V_VEH_COG 1000;
BA_ "InvalidValue" SG_ 417 V_VEH_COG "FFFFh";
BA_ "GenSigTimeoutTime_ALL" SG_ 417 DVCO_VEH 1000;
BA_ "InvalidValue" SG_ 417 DVCO_VEH "7h";
BA_ "GenSigStartValue" SG_ 417 QU_V_VEH_COG 8;
BA_ "GenSigTimeoutTime_ALL" SG_ 417 QU_V_VEH_COG 1000;
BA_ "InvalidValue" SG_ 417 QU_V_VEH_COG "Fh";
BA_ "GenSigTimeoutTime_ALL" SG_ 504 CHKSM_EDS_OutPut_FR 200;
BA_ "GenSigTimeoutTime_ALL" SG_ 504 ALV_EDS_OutPut_FR 200;
BA_ "InvalidValue" SG_ 504 ALV_EDS_OutPut_FR "Fh";
BA_ "GenSigTimeoutTime_ALL" SG_ 504 EDS_Work_STS_FR 200;
BA_ "InvalidValue" SG_ 504 EDS_Work_STS_FR "Fh";
BA_ "GenSigStartValue" SG_ 504 EDS_Spd_FR 20000;
BA_ "GenSigTimeoutTime_ALL" SG_ 504 EDS_Spd_FR 200;
BA_ "InvalidValue" SG_ 504 EDS_Spd_FR "FFFFh";
BA_ "GenSigTimeoutTime_ALL" SG_ 504 EDS_output_trqValid_FR 200;
BA_ "InvalidValue" SG_ 504 EDS_output_trqValid_FR "null";
BA_ "GenSigTimeoutTime_ALL" SG_ 504 EDS_MotorDriveSts_FR 200;
BA_ "InvalidValue" SG_ 504 EDS_MotorDriveSts_FR "3h";
BA_ "GenSigTimeoutTime_ALL" SG_ 504 EDS_powoff_req_FR 200;
BA_ "InvalidValue" SG_ 504 EDS_powoff_req_FR "null";
BA_ "GenSigTimeoutTime_ALL" SG_ 504 EDS_SpdValid_FR 200;
BA_ "InvalidValue" SG_ 504 EDS_SpdValid_FR "null";
BA_ "GenSigStartValue" SG_ 504 EDS_output_trq_FR 2000;
BA_ "GenSigTimeoutTime_ALL" SG_ 504 EDS_output_trq_FR 200;
BA_ "InvalidValue" SG_ 504 EDS_output_trq_FR "FFFFh";
BA_ "GenSigTimeoutTime_ALL" SG_ 504 EDS_VCU_6SO_flag_FWD 200;
BA_ "InvalidValue" SG_ 504 EDS_VCU_6SO_flag_FWD "null";
BA_ "GenSigTimeoutTime_ALL" SG_ 505 CHKSM_EDS_OutPut_RR 200;
BA_ "GenSigTimeoutTime_ALL" SG_ 505 ALV_EDS_OutPut_RR 200;
BA_ "InvalidValue" SG_ 505 ALV_EDS_OutPut_RR "Fh";
BA_ "GenSigTimeoutTime_ALL" SG_ 505 EDS_Work_STS_RR 200;
BA_ "InvalidValue" SG_ 505 EDS_Work_STS_RR "Fh";
BA_ "GenSigStartValue" SG_ 505 EDS_Spd_RR 20000;
BA_ "GenSigTimeoutTime_ALL" SG_ 505 EDS_Spd_RR 200;
BA_ "InvalidValue" SG_ 505 EDS_Spd_RR "FFFFh";
BA_ "GenSigTimeoutTime_ALL" SG_ 505 EDS_output_trqValid_RR 200;
BA_ "InvalidValue" SG_ 505 EDS_output_trqValid_RR "null";
BA_ "GenSigTimeoutTime_ALL" SG_ 505 EDS_MotorDriveSts_RR 200;
BA_ "InvalidValue" SG_ 505 EDS_MotorDriveSts_RR "3h";
BA_ "GenSigTimeoutTime_ALL" SG_ 505 EDS_powoff_req_RR 200;
BA_ "InvalidValue" SG_ 505 EDS_powoff_req_RR "null";
BA_ "GenSigTimeoutTime_ALL" SG_ 505 EDS_SpdValid_RR 200;
BA_ "InvalidValue" SG_ 505 EDS_SpdValid_RR "null";
BA_ "GenSigStartValue" SG_ 505 EDS_output_trq_RR 2000;
BA_ "GenSigTimeoutTime_ALL" SG_ 505 EDS_output_trq_RR 200;
BA_ "InvalidValue" SG_ 505 EDS_output_trq_RR "FFFFh";
BA_ "GenSigTimeoutTime_ALL" SG_ 505 EDS_VCU_6SO_flag_RWD 200;
BA_ "InvalidValue" SG_ 505 EDS_VCU_6SO_flag_RWD "null";
BA_ "GenSigSendType" SG_ 506 MHU_TouchEvtTyp 1;
BA_ "InvalidValue" SG_ 506 MHU_TouchEvtTyp "7h";
BA_ "GenSigSendType" SG_ 506 SECCAN_Drvr_Info 1;
BA_ "GenSigSendType" SG_ 506 MHU_XGestureSpd 1;
BA_ "InvalidValue" SG_ 506 MHU_XGestureSpd "FFh";
BA_ "GenSigSendType" SG_ 506 MHU_YGestureSpd 1;
BA_ "InvalidValue" SG_ 506 MHU_YGestureSpd "FFh";
BA_ "GenSigSendType" SG_ 506 MHU_Ycoordinate 1;
BA_ "InvalidValue" SG_ 506 MHU_Ycoordinate "FFFFh";
BA_ "GenSigSendType" SG_ 506 MHU_Xcoordinate 1;
BA_ "InvalidValue" SG_ 506 MHU_Xcoordinate "FFFFh";
BA_ "GenSigTimeoutTime_ALL" SG_ 515 CHKSM_Camera_rightlane 500;
BA_ "GenSigTimeoutTime_ALL" SG_ 515 ALV_Camera_rightlane 500;
BA_ "InvalidValue" SG_ 515 ALV_Camera_rightlane "Fh";
BA_ "GenSigTimeoutTime_ALL" SG_ 515 R1_LINE_TYPE 500;
BA_ "GenSigTimeoutTime_ALL" SG_ 515 R0_LINE_TYPE 500;
BA_ "GenSigTimeoutTime_ALL" SG_ 515 SECCAN_Camera_rightlane 500;
BA_ "GenSigTimeoutTime_ALL" SG_ 516 CHKSM_Camera_leftlane 500;
BA_ "GenSigTimeoutTime_ALL" SG_ 516 ALV_Camera_leftlane 500;
BA_ "InvalidValue" SG_ 516 ALV_Camera_leftlane "Fh";
BA_ "GenSigTimeoutTime_ALL" SG_ 516 L1_LINE_TYPE 500;
BA_ "InvalidValue" SG_ 516 L1_LINE_TYPE "3h";
BA_ "GenSigTimeoutTime_ALL" SG_ 516 L0_LINE_TYPE 500;
BA_ "GenSigTimeoutTime_ALL" SG_ 516 SECCAN_Camera_leftlane 500;
BA_ "GenSigTimeoutTime_ALL" SG_ 517 Checksum_0x205 200;
BA_ "InvalidValue" SG_ 517 Checksum_0x205 "null";
BA_ "GenSigTimeoutTime_ALL" SG_ 517 Rolling_Counter_0x205 200;
BA_ "InvalidValue" SG_ 517 Rolling_Counter_0x205 "Fh";
BA_ "GenSigTimeoutTime_ALL" SG_ 517 BMS_CellNumMinCellVol 200;
BA_ "InvalidValue" SG_ 517 BMS_CellNumMinCellVol "null";
BA_ "GenSigTimeoutTime_ALL" SG_ 517 BMS_CellNumMaxCellVol 200;
BA_ "InvalidValue" SG_ 517 BMS_CellNumMaxCellVol "null";
BA_ "GenSigTimeoutTime_ALL" SG_ 517 BMS_MinCellVol 200;
BA_ "InvalidValue" SG_ 517 BMS_MinCellVol "1FFFh";
BA_ "GenSigTimeoutTime_ALL" SG_ 517 BMS_MaxCellVol 200;
BA_ "InvalidValue" SG_ 517 BMS_MaxCellVol "1FFFh";
BA_ "GenSigTimeoutTime_ALL" SG_ 518 CHKSM_ADAS_ELK 500;
BA_ "InvalidValue" SG_ 518 CHKSM_ADAS_ELK "0";
BA_ "GenSigTimeoutTime_ALL" SG_ 518 ALV_ADAS_ELK 500;
BA_ "InvalidValue" SG_ 518 ALV_ADAS_ELK "Fh";
BA_ "GenSigTimeoutTime_ALL" SG_ 518 ADAS_HWA_Fautlstate 500;
BA_ "InvalidValue" SG_ 518 ADAS_HWA_Fautlstate "3h";
BA_ "GenSigTimeoutTime_ALL" SG_ 518 ADAS_ELK_check 500;
BA_ "InvalidValue" SG_ 518 ADAS_ELK_check "0";
BA_ "GenSigTimeoutTime_ALL" SG_ 518 ADAS_handsoff_Warning_Mode_2 500;
BA_ "InvalidValue" SG_ 518 ADAS_handsoff_Warning_Mode_2 "3h";
BA_ "GenSigTimeoutTime_ALL" SG_ 518 ADAS_HWA_txtpopup 500;
BA_ "InvalidValue" SG_ 518 ADAS_HWA_txtpopup "Fh";
BA_ "GenSigTimeoutTime_ALL" SG_ 518 ADAS_HWA_state 500;
BA_ "InvalidValue" SG_ 518 ADAS_HWA_state "7h";
BA_ "InvalidValue" SG_ 518 ADAS_Mode2_status "3h";
BA_ "GenSigTimeoutTime_ALL" SG_ 518 ADAS_Mode2_status 500;
BA_ "GenSigStartValue" SG_ 518 ADAS_ALC_Mode_feed 1;
BA_ "GenSigTimeoutTime_ALL" SG_ 518 ADAS_ALC_Mode_feed 500;
BA_ "InvalidValue" SG_ 518 ADAS_ALC_Mode_feed "3h";
BA_ "GenSigTimeoutTime_ALL" SG_ 518 ADAS_handsoff_txtpopup 500;
BA_ "InvalidValue" SG_ 518 ADAS_handsoff_txtpopup "3h";
BA_ "GenSigTimeoutTime_ALL" SG_ 518 ADAS_ALC_txtpopup 500;
BA_ "InvalidValue" SG_ 518 ADAS_ALC_txtpopup "Fh";
BA_ "GenSigTimeoutTime_ALL" SG_ 518 ADAS_ALC_state 500;
BA_ "InvalidValue" SG_ 518 ADAS_ALC_state "7h";
BA_ "GenSigTimeoutTime_ALL" SG_ 518 ADAS_LA_Display 500;
BA_ "InvalidValue" SG_ 518 ADAS_LA_Display "0";
BA_ "GenSigTimeoutTime_ALL" SG_ 518 ADAS_Lane_Line_Curva_Radius 500;
BA_ "InvalidValue" SG_ 518 ADAS_Lane_Line_Curva_Radius "0";
BA_ "GenSigTimeoutTime_ALL" SG_ 519 SR_Undervoltage_Fault_Sts 500;
BA_ "InvalidValue" SG_ 519 SR_Undervoltage_Fault_Sts "null";
BA_ "GenSigTimeoutTime_ALL" SG_ 519 SR_Overvoltage_Fault_Sts 500;
BA_ "InvalidValue" SG_ 519 SR_Overvoltage_Fault_Sts "null";
BA_ "GenSigTimeoutTime_ALL" SG_ 519 SR_SLEEP_RQ 500;
BA_ "InvalidValue" SG_ 519 SR_SLEEP_RQ "null";
BA_ "GenSigTimeoutTime_ALL" SG_ 519 SR_Position 500;
BA_ "InvalidValue" SG_ 519 SR_Position "null";
BA_ "GenSigTimeoutTime_ALL" SG_ 519 SR_Motor_Running_Sts 500;
BA_ "InvalidValue" SG_ 519 SR_Motor_Running_Sts "null";
BA_ "GenSigTimeoutTime_ALL" SG_ 519 SR_MotorReverse_Fault_Sts 500;
BA_ "InvalidValue" SG_ 519 SR_MotorReverse_Fault_Sts "null";
BA_ "GenSigTimeoutTime_ALL" SG_ 519 SR_Hall_Fault_Sts 500;
BA_ "InvalidValue" SG_ 519 SR_Hall_Fault_Sts "null";
BA_ "GenSigTimeoutTime_ALL" SG_ 519 SR_Normalisation_Sts 500;
BA_ "InvalidValue" SG_ 519 SR_Normalisation_Sts "null";
BA_ "GenSigTimeoutTime_ALL" SG_ 519 SR_Relay_Fault 500;
BA_ "InvalidValue" SG_ 519 SR_Relay_Fault "null";
BA_ "GenSigTimeoutTime_ALL" SG_ 519 SR_Commu_Fault_Sts 500;
BA_ "InvalidValue" SG_ 519 SR_Commu_Fault_Sts "null";
BA_ "GenSigTimeoutTime_ALL" SG_ 519 SR_Initialisation_Status 500;
BA_ "InvalidValue" SG_ 519 SR_Initialisation_Status "null";
BA_ "GenSigTimeoutTime_ALL" SG_ 519 SR_Ctrl_Result 500;
BA_ "InvalidValue" SG_ 519 SR_Ctrl_Result "null";
BA_ "GenSigTimeoutTime_ALL" SG_ 519 SR_ThermalProtection_Fault_Sts 500;
BA_ "InvalidValue" SG_ 519 SR_ThermalProtection_Fault_Sts "null";
BA_ "GenSigTimeoutTime_ALL" SG_ 519 SR_Posit_Percentage 500;
BA_ "InvalidValue" SG_ 519 SR_Posit_Percentage "7Fh";
BA_ "GenSigTimeoutTime_ALL" SG_ 519 SR_Operation_Stat 500;
BA_ "InvalidValue" SG_ 519 SR_Operation_Stat "null";
BA_ "GenSigTimeoutTime_ALL" SG_ 519 SR_Error_RSP 500;
BA_ "InvalidValue" SG_ 519 SR_Error_RSP "null";
BA_ "GenSigTimeoutTime_ALL" SG_ 519 BCM_AutoSunroof_Sts 500;
BA_ "GenSigStartValue" SG_ 519 BCM_AutoSunroof_Sts 2;
BA_ "InvalidValue" SG_ 519 BCM_AutoSunroof_Sts "3h";
BA_ "GenSigTimeoutTime_ALL" SG_ 520 SS_MotorReverse_Fault_Status 500;
BA_ "InvalidValue" SG_ 520 SS_MotorReverse_Fault_Status "null";
BA_ "GenSigTimeoutTime_ALL" SG_ 520 SS_Motor_Running_Status 500;
BA_ "InvalidValue" SG_ 520 SS_Motor_Running_Status "null";
BA_ "GenSigTimeoutTime_ALL" SG_ 520 SS_Position 500;
BA_ "InvalidValue" SG_ 520 SS_Position "null";
BA_ "GenSigTimeoutTime_ALL" SG_ 520 SS_SLEEP_RQ 500;
BA_ "InvalidValue" SG_ 520 SS_SLEEP_RQ "null";
BA_ "GenSigTimeoutTime_ALL" SG_ 520 SS_Undervoltage_Fault_Status 500;
BA_ "InvalidValue" SG_ 520 SS_Undervoltage_Fault_Status "null";
BA_ "GenSigTimeoutTime_ALL" SG_ 520 SS_Ctrl_Result 500;
BA_ "InvalidValue" SG_ 520 SS_Ctrl_Result "null";
BA_ "GenSigTimeoutTime_ALL" SG_ 520 SS_Overvoltage_Fault_Status 500;
BA_ "InvalidValue" SG_ 520 SS_Overvoltage_Fault_Status "null";
BA_ "GenSigTimeoutTime_ALL" SG_ 520 SS_Relay_Fault 500;
BA_ "InvalidValue" SG_ 520 SS_Relay_Fault "null";
BA_ "GenSigTimeoutTime_ALL" SG_ 520 SS_Normalisation_Status 500;
BA_ "InvalidValue" SG_ 520 SS_Normalisation_Status "null";
BA_ "GenSigTimeoutTime_ALL" SG_ 520 SS_Hall_Fault_Status 500;
BA_ "InvalidValue" SG_ 520 SS_Hall_Fault_Status "null";
BA_ "GenSigTimeoutTime_ALL" SG_ 520 SS_Commu_Fault_Status 500;
BA_ "InvalidValue" SG_ 520 SS_Commu_Fault_Status "null";
BA_ "GenSigTimeoutTime_ALL" SG_ 520 SS_Initialisation_Status 500;
BA_ "InvalidValue" SG_ 520 SS_Initialisation_Status "null";
BA_ "GenSigTimeoutTime_ALL" SG_ 520 SS_Posit_Percentage 500;
BA_ "InvalidValue" SG_ 520 SS_Posit_Percentage "7Fh";
BA_ "GenSigTimeoutTime_ALL" SG_ 520 SS_ThermalProtection_Flt_Sts 500;
BA_ "InvalidValue" SG_ 520 SS_ThermalProtection_Flt_Sts "null";
BA_ "GenSigTimeoutTime_ALL" SG_ 520 SS_Operation_State 500;
BA_ "InvalidValue" SG_ 520 SS_Operation_State "null";
BA_ "GenSigTimeoutTime_ALL" SG_ 520 SECCAN_SunshadeSts 500;
BA_ "InvalidValue" SG_ 520 SECCAN_SunshadeSts "null";
BA_ "GenSigTimeoutTime_ALL" SG_ 520 SS_Error_RSP 500;
BA_ "InvalidValue" SG_ 520 SS_Error_RSP "null";
BA_ "GenSigTimeoutTime_ALL" SG_ 521 CHKSM_PAS_RAEB 500;
BA_ "GenSigTimeoutTime_ALL" SG_ 521 ALV_PAS_RAEB 500;
BA_ "GenSigTimeoutTime_ALL" SG_ 521 PAS_RAEB_check 500;
BA_ "InvalidValue" SG_ 521 PAS_RAEB_check "3h";
BA_ "GenSigStartValue" SG_ 521 PAS_RAEB_Mode_Feed 1;
BA_ "GenSigTimeoutTime_ALL" SG_ 521 PAS_RAEB_Mode_Feed 500;
BA_ "InvalidValue" SG_ 521 PAS_RAEB_Mode_Feed "3h";
BA_ "GenSigStartValue" SG_ 521 PAS_RAEB_State 1;
BA_ "GenSigTimeoutTime_ALL" SG_ 521 PAS_RAEB_State 500;
BA_ "InvalidValue" SG_ 521 PAS_RAEB_State "3h";
BA_ "GenSigTimeoutTime_ALL" SG_ 521 PAS_RAEB_Warning 500;
BA_ "InvalidValue" SG_ 521 PAS_RAEB_Warning "3h";
BA_ "GenSigStartValue" SG_ 522 ETG_Lift_Gate_Status 7;
BA_ "GenSigTimeoutTime_ALL" SG_ 522 ETG_Lift_Gate_Status 500;
BA_ "InvalidValue" SG_ 522 ETG_Lift_Gate_Status "7h";
BA_ "GenSigStartValue" SG_ 522 ETG_Power_Latch_Status 7;
BA_ "GenSigTimeoutTime_ALL" SG_ 522 ETG_Power_Latch_Status 500;
BA_ "InvalidValue" SG_ 522 ETG_Power_Latch_Status "7h";
BA_ "GenSigStartValue" SG_ 522 ETG_Latch_Segment 3;
BA_ "GenSigTimeoutTime_ALL" SG_ 522 ETG_Latch_Segment 500;
BA_ "InvalidValue" SG_ 522 ETG_Latch_Segment "3h";
BA_ "GenSigTimeoutTime_ALL" SG_ 522 ETG_Opening_Percentage 500;
BA_ "InvalidValue" SG_ 522 ETG_Opening_Percentage "FFh";
BA_ "GenSigTimeoutTime_ALL" SG_ 522 ETG_DSW_Status 500;
BA_ "InvalidValue" SG_ 522 ETG_DSW_Status "null";
BA_ "GenSigTimeoutTime_ALL" SG_ 522 ETG_GSW_Status 500;
BA_ "InvalidValue" SG_ 522 ETG_GSW_Status "null";
BA_ "GenSigTimeoutTime_ALL" SG_ 522 ETG_LTS_Status 500;
BA_ "InvalidValue" SG_ 522 ETG_LTS_Status "null";
BA_ "GenSigTimeoutTime_ALL" SG_ 522 ETG_RTS_Status 500;
BA_ "InvalidValue" SG_ 522 ETG_RTS_Status "null";
BA_ "GenSigTimeoutTime_ALL" SG_ 522 ETG_HAL_Status 500;
BA_ "InvalidValue" SG_ 522 ETG_HAL_Status "null";
BA_ "GenSigTimeoutTime_ALL" SG_ 522 ETG_FUL_Status 500;
BA_ "InvalidValue" SG_ 522 ETG_FUL_Status "null";
BA_ "GenSigTimeoutTime_ALL" SG_ 522 ETG_AJR_Status 500;
BA_ "InvalidValue" SG_ 522 ETG_AJR_Status "null";
BA_ "GenSigTimeoutTime_ALL" SG_ 522 ETG_NTL_Status 500;
BA_ "InvalidValue" SG_ 522 ETG_NTL_Status "null";
BA_ "GenSigTimeoutTime_ALL" SG_ 522 ETG_ERR_Voltage 500;
BA_ "InvalidValue" SG_ 522 ETG_ERR_Voltage "null";
BA_ "GenSigTimeoutTime_ALL" SG_ 522 ETG_ERR_Left_Motor 500;
BA_ "InvalidValue" SG_ 522 ETG_ERR_Left_Motor "null";
BA_ "GenSigTimeoutTime_ALL" SG_ 522 ETG_ERR_Right_Motor 500;
BA_ "InvalidValue" SG_ 522 ETG_ERR_Right_Motor "null";
BA_ "GenSigTimeoutTime_ALL" SG_ 522 ETG_ERR_Latch 500;
BA_ "InvalidValue" SG_ 522 ETG_ERR_Latch "null";
BA_ "GenSigTimeoutTime_ALL" SG_ 522 ETG_ERR_Hall 500;
BA_ "InvalidValue" SG_ 522 ETG_ERR_Hall "null";
BA_ "GenSigTimeoutTime_ALL" SG_ 522 ETG_Lift_Motor_Stall 500;
BA_ "InvalidValue" SG_ 522 ETG_Lift_Motor_Stall "null";
BA_ "GenSigTimeoutTime_ALL" SG_ 522 ETG_Lift_Motor_AntiPinch 500;
BA_ "InvalidValue" SG_ 522 ETG_Lift_Motor_AntiPinch "null";
BA_ "GenSigTimeoutTime_ALL" SG_ 522 ETG_Lift_Motor_Thermal 500;
BA_ "InvalidValue" SG_ 522 ETG_Lift_Motor_Thermal "null";
BA_ "GenSigTimeoutTime_ALL" SG_ 522 ETG_Power_Latch_Thermal 500;
BA_ "InvalidValue" SG_ 522 ETG_Power_Latch_Thermal "null";
BA_ "GenSigTimeoutTime_ALL" SG_ 522 ETG_Abuse_Protection 500;
BA_ "InvalidValue" SG_ 522 ETG_Abuse_Protection "null";
BA_ "GenSigTimeoutTime_ALL" SG_ 523 FKS_RespError 500;
BA_ "InvalidValue" SG_ 523 FKS_RespError "null";
BA_ "GenSigTimeoutTime_ALL" SG_ 523 FKS_OpenReq 500;
BA_ "InvalidValue" SG_ 523 FKS_OpenReq "null";
BA_ "GenSigTimeoutTime_ALL" SG_ 523 FKS_HWError 500;
BA_ "InvalidValue" SG_ 523 FKS_HWError "null";
BA_ "GenSigTimeoutTime_ALL" SG_ 523 FKS_AntennaError 500;
BA_ "InvalidValue" SG_ 523 FKS_AntennaError "null";
BA_ "GenSigTimeoutTime_ALL" SG_ 523 FKS_OverVolDected 500;
BA_ "InvalidValue" SG_ 523 FKS_OverVolDected "null";
BA_ "GenSigTimeoutTime_ALL" SG_ 523 FKS_UnderVolDected 500;
BA_ "InvalidValue" SG_ 523 FKS_UnderVolDected "null";
BA_ "GenSigTimeoutTime_ALL" SG_ 523 FKS_activate_deactivate 500;
BA_ "InvalidValue" SG_ 523 FKS_activate_deactivate "null";
BA_ "GenSigTimeoutTime_ALL" SG_ 524 CHKSM_IC_ODO 500;
BA_ "InvalidValue" SG_ 524 CHKSM_IC_ODO "null";
BA_ "GenSigTimeoutTime_ALL" SG_ 524 ALIV_IC_ODO 500;
BA_ "InvalidValue" SG_ 524 ALIV_IC_ODO "Fh";
BA_ "GenSigTimeoutTime_ALL" SG_ 524 MHU_Odometer_IC 500;
BA_ "InvalidValue" SG_ 524 MHU_Odometer_IC "FFFFFh";
BA_ "GenSigTimeoutTime_ALL" SG_ 525 CHKSM_IDB_STATUS 200;
BA_ "InvalidValue" SG_ 525 CHKSM_IDB_STATUS "null";
BA_ "GenSigTimeoutTime_ALL" SG_ 525 ALV_IDB_STATUS 200;
BA_ "InvalidValue" SG_ 525 ALV_IDB_STATUS "Fh";
BA_ "GenSigTimeoutTime_ALL" SG_ 525 ESPTransRequestType 200;
BA_ "InvalidValue" SG_ 525 ESPTransRequestType "null";
BA_ "GenSigTimeoutTime_ALL" SG_ 525 ABSFault 200;
BA_ "InvalidValue" SG_ 525 ABSFault "null";
BA_ "GenSigTimeoutTime_ALL" SG_ 525 ABSActive 200;
BA_ "InvalidValue" SG_ 525 ABSActive "null";
BA_ "GenSigTimeoutTime_ALL" SG_ 525 VehicleSpd 200;
BA_ "InvalidValue" SG_ 525 VehicleSpd "null";
BA_ "GenSigTimeoutTime_ALL" SG_ 525 ESC_VehicleStandstill 200;
BA_ "InvalidValue" SG_ 525 ESC_VehicleStandstill "null";
BA_ "GenSigTimeoutTime_ALL" SG_ 525 MCPressureSts 200;
BA_ "InvalidValue" SG_ 525 MCPressureSts "null";
BA_ "GenSigTimeoutTime_ALL" SG_ 525 VehicleSpdSts 200;
BA_ "InvalidValue" SG_ 525 VehicleSpdSts "null";
BA_ "GenSigStartValue" SG_ 525 MCPressure 21;
BA_ "GenSigTimeoutTime_ALL" SG_ 525 MCPressure 200;
BA_ "InvalidValue" SG_ 525 MCPressure "FFh";
BA_ "GenSigTimeoutTime_ALL" SG_ 525 ESC_Braking_effort 200;
BA_ "InvalidValue" SG_ 525 ESC_Braking_effort "1";
BA_ "GenSigTimeoutTime_ALL" SG_ 525 BRAKE_LightonRequestEPBi 200;
BA_ "InvalidValue" SG_ 525 BRAKE_LightonRequestEPBi "null";
BA_ "GenSigTimeoutTime_ALL" SG_ 525 VDCActive 200;
BA_ "InvalidValue" SG_ 525 VDCActive "null";
BA_ "GenSigTimeoutTime_ALL" SG_ 525 TCSActive 200;
BA_ "InvalidValue" SG_ 525 TCSActive "null";
BA_ "GenSigTimeoutTime_ALL" SG_ 525 TCSAvailable 200;
BA_ "InvalidValue" SG_ 525 TCSAvailable "null";
BA_ "GenSigTimeoutTime_ALL" SG_ 525 IDBActive 200;
BA_ "InvalidValue" SG_ 525 IDBActive "null";
BA_ "GenSigTimeoutTime_ALL" SG_ 525 IDBFault 200;
BA_ "InvalidValue" SG_ 525 IDBFault "null";
BA_ "GenSigTimeoutTime_ALL" SG_ 525 ESC_VehicleHoldStat 200;
BA_ "InvalidValue" SG_ 525 ESC_VehicleHoldStat "null";
BA_ "GenSigTimeoutTime_ALL" SG_ 525 IDB_Power_Stage 200;
BA_ "InvalidValue" SG_ 525 IDB_Power_Stage "null";
BA_ "GenSigTimeoutTime_ALL" SG_ 525 ESC_BrakeReleasedFailsafe 200;
BA_ "InvalidValue" SG_ 525 ESC_BrakeReleasedFailsafe "null";
BA_ "GenSigTimeoutTime_ALL" SG_ 526 Chksum_PAS_APA_txt 500;
BA_ "GenSigTimeoutTime_ALL" SG_ 526 Alive_PAS_APA_txt 500;
BA_ "GenSigTimeoutTime_ALL" SG_ 526 PAS_APA_ReqInfoDispTxt2 500;
BA_ "GenSigTimeoutTime_ALL" SG_ 526 PAS_APA_ReqInfoDispTxt1 500;
BA_ "GenSigTimeoutTime_ALL" SG_ 526 PAS_APA_ReqInfoDispTxt4 500;
BA_ "GenSigTimeoutTime_ALL" SG_ 526 PAS_APA_ReqInfoDispTxt3 500;
BA_ "GenSigTimeoutTime_ALL" SG_ 526 PAS_RP_ReqInfoDispTxt1 500;
BA_ "GenSigTimeoutTime_ALL" SG_ 526 PAS_RP_ReqInfoDispTxt2 500;
BA_ "GenSigTimeoutTime_ALL" SG_ 527 CHKSM_ADAS_BCM_Status 500;
BA_ "InvalidValue" SG_ 527 CHKSM_ADAS_BCM_Status "null";
BA_ "GenSigTimeoutTime_ALL" SG_ 527 ALIVE_ADAS_BCM_Status 500;
BA_ "InvalidValue" SG_ 527 ALIVE_ADAS_BCM_Status "Fh";
BA_ "GenSigTimeoutTime_ALL" SG_ 527 ADAS_BCM_HeadlightReq 500;
BA_ "GenSigTimeoutTime_ALL" SG_ 527 ADAS_BCM_FoldMirrorReq 500;
BA_ "GenSigTimeoutTime_ALL" SG_ 527 ADAS_BCM_Status 500;
BA_ "InvalidValue" SG_ 527 ADAS_BCM_Status "null";
BA_ "GenSigTimeoutTime_ALL" SG_ 527 ADAS_BCM_IndicatorlightReq 500;
BA_ "InvalidValue" SG_ 527 ADAS_BCM_IndicatorlightReq "null";
BA_ "GenSigTimeoutTime_ALL" SG_ 527 SECCAN_ADAS_BCM_Sts 500;
BA_ "GenSigTimeoutTime_ALL" SG_ 531 CHSKM_VCU_POD_reqDCDC 500;
BA_ "InvalidValue" SG_ 531 CHSKM_VCU_POD_reqDCDC "";
BA_ "GenSigTimeoutTime_ALL" SG_ 531 ALV_VCU_POD_reqDCDC 500;
BA_ "InvalidValue" SG_ 531 ALV_VCU_POD_reqDCDC "Fh";
BA_ "GenSigTimeoutTime_ALL" SG_ 531 VCU_enableDCDC 500;
BA_ "InvalidValue" SG_ 531 VCU_enableDCDC "3h";
BA_ "GenSigStartValue" SG_ 531 VCU_vDCDCRequest 224;
BA_ "GenSigTimeoutTime_ALL" SG_ 531 VCU_vDCDCRequest 500;
BA_ "InvalidValue" SG_ 531 VCU_vDCDCRequest "FFFFh";
BA_ "GenSigTimeoutTime_ALL" SG_ 531 VCU_iDCDCRequest_lim 500;
BA_ "InvalidValue" SG_ 531 VCU_iDCDCRequest_lim "FFFFh";
BA_ "GenSigTimeoutTime_ALL" SG_ 532 Checksum_0x214 500;
BA_ "GenSigTimeoutTime_ALL" SG_ 532 Rolling_Counter_0x214 500;
BA_ "InvalidValue" SG_ 532 Rolling_Counter_0x214 "Fh";
BA_ "GenSigTimeoutTime_ALL" SG_ 532 BMS_Display_SOC 500;
BA_ "InvalidValue" SG_ 532 BMS_Display_SOC "3FFh";
BA_ "InvalidValue" SG_ 532 BMS_SOCE "3FFFh";
BA_ "GenSigTimeoutTime_ALL" SG_ 532 BMS_SOCE 500;
BA_ "GenSigTimeoutTime_ALL" SG_ 533 Checksum_0x215 500;
BA_ "InvalidValue" SG_ 533 Checksum_0x215 "null";
BA_ "GenSigTimeoutTime_ALL" SG_ 533 Rolling_Counter_0x215 500;
BA_ "InvalidValue" SG_ 533 Rolling_Counter_0x215 "Fh";
BA_ "GenSigTimeoutTime_ALL" SG_ 533 BMS_BatBalance_ERR 500;
BA_ "InvalidValue" SG_ 533 BMS_BatBalance_ERR "null";
BA_ "GenSigTimeoutTime_ALL" SG_ 533 BMS_Balance_STS 500;
BA_ "InvalidValue" SG_ 533 BMS_Balance_STS "null";
BA_ "GenSigTimeoutTime_ALL" SG_ 533 BMS_IGN_Sts 500;
BA_ "InvalidValue" SG_ 533 BMS_IGN_Sts "null";
BA_ "GenSigTimeoutTime_ALL" SG_ 533 BMS_HWCrash_Sts 500;
BA_ "InvalidValue" SG_ 533 BMS_HWCrash_Sts "null";
BA_ "GenSigTimeoutTime_ALL" SG_ 533 BMS_HVIL_STS 500;
BA_ "InvalidValue" SG_ 533 BMS_HVIL_STS "3h";
BA_ "GenSigTimeoutTime_ALL" SG_ 533 BMS_HVOnOff_STS 500;
BA_ "InvalidValue" SG_ 533 BMS_HVOnOff_STS "null";
BA_ "GenSigTimeoutTime_ALL" SG_ 533 BMS_ERR_LEV 500;
BA_ "InvalidValue" SG_ 533 BMS_ERR_LEV "null";
BA_ "GenSigTimeoutTime_ALL" SG_ 533 BMS_SocActual_EST 500;
BA_ "InvalidValue" SG_ 533 BMS_SocActual_EST "3FFh";
BA_ "GenSigTimeoutTime_ALL" SG_ 533 BMS_Sys_STS 500;
BA_ "InvalidValue" SG_ 533 BMS_Sys_STS "8h";
BA_ "GenSigTimeoutTime_ALL" SG_ 533 BMS_ISU_Status 500;
BA_ "InvalidValue" SG_ 533 BMS_ISU_Status "null";
BA_ "GenSigStartValue" SG_ 533 BMS_SOH 54;
BA_ "GenSigTimeoutTime_ALL" SG_ 533 BMS_SOH 500;
BA_ "InvalidValue" SG_ 533 BMS_SOH "FFh";
BA_ "GenSigStartValue" SG_ 533 BMS_SOE 54;
BA_ "GenSigTimeoutTime_ALL" SG_ 533 BMS_SOE 500;
BA_ "InvalidValue" SG_ 533 BMS_SOE "FFh";
BA_ "GenSigTimeoutTime_ALL" SG_ 533 BMS_HV_Sts 500;
BA_ "GenSigTimeoutTime_ALL" SG_ 534 Checksum_0x216 500;
BA_ "InvalidValue" SG_ 534 Checksum_0x216 "null";
BA_ "GenSigTimeoutTime_ALL" SG_ 534 Rolling_Counter_0x216 500;
BA_ "InvalidValue" SG_ 534 Rolling_Counter_0x216 "Fh";
BA_ "GenSigTimeoutTime_ALL" SG_ 534 BMS_RemainChargeTime 500;
BA_ "InvalidValue" SG_ 534 BMS_RemainChargeTime "3FFFh";
BA_ "GenSigTimeoutTime_ALL" SG_ 534 BMS_ChgVoltage_REQ 500;
BA_ "InvalidValue" SG_ 534 BMS_ChgVoltage_REQ "3FFFh";
BA_ "GenSigTimeoutTime_ALL" SG_ 534 BMS_ChgCurrent_REQ 500;
BA_ "InvalidValue" SG_ 534 BMS_ChgCurrent_REQ "FFFh";
BA_ "GenSigStartValue" SG_ 538 DMS_HeadPitch 255;
BA_ "GenSigTimeoutTime_ALL" SG_ 538 DMS_HeadPitch 500;
BA_ "InvalidValue" SG_ 538 DMS_HeadPitch "FFh";
BA_ "GenSigStartValue" SG_ 538 DMS_HeadRoll 255;
BA_ "GenSigTimeoutTime_ALL" SG_ 538 DMS_HeadRoll 500;
BA_ "InvalidValue" SG_ 538 DMS_HeadRoll "FFh";
BA_ "GenSigStartValue" SG_ 538 DMS_HeadYaw 255;
BA_ "GenSigTimeoutTime_ALL" SG_ 538 DMS_HeadYaw 500;
BA_ "InvalidValue" SG_ 538 DMS_HeadYaw "FFh";
BA_ "GenSigStartValue" SG_ 538 DMS_HeadX 2047;
BA_ "GenSigTimeoutTime_ALL" SG_ 538 DMS_HeadX 500;
BA_ "InvalidValue" SG_ 538 DMS_HeadX "7FFh";
BA_ "GenSigStartValue" SG_ 538 DMS_HeadY 2047;
BA_ "GenSigTimeoutTime_ALL" SG_ 538 DMS_HeadY 500;
BA_ "InvalidValue" SG_ 538 DMS_HeadY "7FFh";
BA_ "GenSigStartValue" SG_ 538 DMS_HeadZ 2047;
BA_ "GenSigTimeoutTime_ALL" SG_ 538 DMS_HeadZ 500;
BA_ "InvalidValue" SG_ 538 DMS_HeadZ "7FFh";
BA_ "GenSigTimeoutTime_ALL" SG_ 539 BMS_faultnumber 50000;
BA_ "GenSigTimeoutTime_ALL" SG_ 540 CHKSM_FCAM_AEB 500;
BA_ "InvalidValue" SG_ 540 ALV_FCAM_AEB "Fh";
BA_ "GenSigTimeoutTime_ALL" SG_ 540 ALV_FCAM_AEB 500;
BA_ "InvalidValue" SG_ 540 FCAM_AEB_Warning "3h";
BA_ "GenSigTimeoutTime_ALL" SG_ 540 FCAM_AEB_Warning 500;
BA_ "InvalidValue" SG_ 540 FCAM_AEB_State "3h";
BA_ "GenSigTimeoutTime_ALL" SG_ 540 FCAM_AEB_State 500;
BA_ "GenSigStartValue" SG_ 540 FCAM_AEB_State 1;
BA_ "InvalidValue" SG_ 540 FCAM_AEB_Mode_Feed "3h";
BA_ "GenSigTimeoutTime_ALL" SG_ 540 FCAM_AEB_Mode_Feed 500;
BA_ "GenSigStartValue" SG_ 540 FCAM_AEB_Mode_Feed 1;
BA_ "InvalidValue" SG_ 540 FCAM_AEB_check "3h";
BA_ "GenSigTimeoutTime_ALL" SG_ 540 FCAM_AEB_check 500;
BA_ "GenSigTimeoutTime_ALL" SG_ 540 SECCAN_FCAM_AEB 500;
BA_ "GenSigSendType" SG_ 544 MHU_SET_CCUR_AirCondition 2;
BA_ "InvalidValue" SG_ 544 MHU_SET_CCUR_AirCondition "3h";
BA_ "GenSigSendType" SG_ 544 MHU_SET_CCUR_AutoAC 2;
BA_ "InvalidValue" SG_ 544 MHU_SET_CCUR_AutoAC "3h";
BA_ "GenSigSendType" SG_ 544 MHU_SET_CCUR_RearLock 2;
BA_ "InvalidValue" SG_ 544 MHU_SET_CCUR_RearLock "3h";
BA_ "GenSigSendType" SG_ 544 MHU_SET_CCUR_MaxAc 2;
BA_ "InvalidValue" SG_ 544 MHU_SET_CCUR_MaxAc "3h";
BA_ "GenSigSendType" SG_ 544 MHU_SET_CCUR_FanSpeed 2;
BA_ "GenSigStartValue" SG_ 544 MHU_SET_CCUR_FanSpeed 3;
BA_ "InvalidValue" SG_ 544 MHU_SET_CCUR_FanSpeed "7h";
BA_ "GenSigSendType" SG_ 544 MHU_SET_CCUR_Recirculation 2;
BA_ "GenSigStartValue" SG_ 544 MHU_SET_CCUR_Recirculation 1;
BA_ "InvalidValue" SG_ 544 MHU_SET_CCUR_Recirculation "3h";
BA_ "GenSigSendType" SG_ 544 MHU_SET_CCUR_Ion 2;
BA_ "InvalidValue" SG_ 544 MHU_SET_CCUR_Ion "3h";
BA_ "GenSigSendType" SG_ 544 MHU_SET_CCUR_FlapPosition 2;
BA_ "InvalidValue" SG_ 544 MHU_SET_CCUR_FlapPosition "4h";
BA_ "GenSigSendType" SG_ 544 MHU_SET_CCUR_SyncClimateZone 2;
BA_ "InvalidValue" SG_ 544 MHU_SET_CCUR_SyncClimateZone "3h";
BA_ "GenSigSendType" SG_ 544 MHU_SET_CCUR_TempRear 2;
BA_ "GenSigStartValue" SG_ 544 MHU_SET_CCUR_TempRear 40;
BA_ "InvalidValue" SG_ 544 MHU_SET_CCUR_TempRear "FFh";
BA_ "GenSigSendType" SG_ 544 MHU_SET_CCUR_FrontDefrost 2;
BA_ "InvalidValue" SG_ 544 MHU_SET_CCUR_FrontDefrost "3h";
BA_ "GenSigStartValue" SG_ 545 DrvSeatMsgStrLvl 1;
BA_ "GenSigTimeoutTime_ALL" SG_ 545 DrvSeatMsgStrLvl 800;
BA_ "InvalidValue" SG_ 545 DrvSeatMsgStrLvl "7h";
BA_ "GenSigStartValue" SG_ 545 PassSeatMsgStrLvl 1;
BA_ "GenSigTimeoutTime_ALL" SG_ 545 PassSeatMsgStrLvl 800;
BA_ "InvalidValue" SG_ 545 PassSeatMsgStrLvl "7h";
BA_ "GenSigStartValue" SG_ 545 RearDrvSeatMsgStrLvl 1;
BA_ "GenSigTimeoutTime_ALL" SG_ 545 RearDrvSeatMsgStrLvl 800;
BA_ "InvalidValue" SG_ 545 RearDrvSeatMsgStrLvl "7h";
BA_ "GenSigStartValue" SG_ 545 RearPassSeatMsgStrLvl 1;
BA_ "GenSigTimeoutTime_ALL" SG_ 545 RearPassSeatMsgStrLvl 800;
BA_ "InvalidValue" SG_ 545 RearPassSeatMsgStrLvl "7h";
BA_ "GenSigTimeoutTime_ALL" SG_ 545 DrvSeatMsgMode 800;
BA_ "InvalidValue" SG_ 545 DrvSeatMsgMode "7h";
BA_ "GenSigTimeoutTime_ALL" SG_ 545 PassSeatMsgMode 800;
BA_ "InvalidValue" SG_ 545 PassSeatMsgMode "7h";
BA_ "GenSigTimeoutTime_ALL" SG_ 545 RearDrvSeatMsgMode 800;
BA_ "InvalidValue" SG_ 545 RearDrvSeatMsgMode "7h";
BA_ "GenSigTimeoutTime_ALL" SG_ 545 RearPassSeatMsgMode 800;
BA_ "InvalidValue" SG_ 545 RearPassSeatMsgMode "7h";
BA_ "GenSigTimeoutTime_ALL" SG_ 546 DrvSeatMsgModeStat 800;
BA_ "InvalidValue" SG_ 546 DrvSeatMsgModeStat "7h";
BA_ "GenSigTimeoutTime_ALL" SG_ 546 PassSeatMsgModeStat 800;
BA_ "InvalidValue" SG_ 546 PassSeatMsgModeStat "7h";
BA_ "GenSigTimeoutTime_ALL" SG_ 546 RearDrvSeatMsgModeStat 800;
BA_ "InvalidValue" SG_ 546 RearDrvSeatMsgModeStat "7h";
BA_ "GenSigTimeoutTime_ALL" SG_ 546 RearPassSeatMsgModeStat 800;
BA_ "InvalidValue" SG_ 546 RearPassSeatMsgModeStat "7h";
BA_ "GenSigTimeoutTime_ALL" SG_ 546 LSSM_ALINResErr 800;
BA_ "InvalidValue" SG_ 546 LSSM_ALINResErr "null";
BA_ "GenSigTimeoutTime_ALL" SG_ 546 LSSM_APumpFail 800;
BA_ "InvalidValue" SG_ 546 LSSM_APumpFail "null";
BA_ "GenSigStartValue" SG_ 546 DrvSeatMsgStrLvlStat 1;
BA_ "GenSigTimeoutTime_ALL" SG_ 546 DrvSeatMsgStrLvlStat 800;
BA_ "InvalidValue" SG_ 546 DrvSeatMsgStrLvlStat "7h";
BA_ "GenSigTimeoutTime_ALL" SG_ 546 LSSM_BLINResErr 800;
BA_ "InvalidValue" SG_ 546 LSSM_BLINResErr "null";
BA_ "GenSigTimeoutTime_ALL" SG_ 546 LSSM_BPumpFail 800;
BA_ "InvalidValue" SG_ 546 LSSM_BPumpFail "null";
BA_ "GenSigStartValue" SG_ 546 PassSeatMsgStrLvlStat 1;
BA_ "GenSigTimeoutTime_ALL" SG_ 546 PassSeatMsgStrLvlStat 800;
BA_ "InvalidValue" SG_ 546 PassSeatMsgStrLvlStat "7h";
BA_ "GenSigTimeoutTime_ALL" SG_ 546 LSSM_CLINResErr 800;
BA_ "InvalidValue" SG_ 546 LSSM_CLINResErr "null";
BA_ "GenSigTimeoutTime_ALL" SG_ 546 LSSM_CPumpFail 800;
BA_ "InvalidValue" SG_ 546 LSSM_CPumpFail "null";
BA_ "GenSigStartValue" SG_ 546 RearDrvSeatMsgStrLvlStat 1;
BA_ "GenSigTimeoutTime_ALL" SG_ 546 RearDrvSeatMsgStrLvlStat 800;
BA_ "InvalidValue" SG_ 546 RearDrvSeatMsgStrLvlStat "7h";
BA_ "GenSigTimeoutTime_ALL" SG_ 546 LSSM_DLINResErr 800;
BA_ "InvalidValue" SG_ 546 LSSM_DLINResErr "null";
BA_ "GenSigTimeoutTime_ALL" SG_ 546 LSSM_DPumpFail 800;
BA_ "InvalidValue" SG_ 546 LSSM_DPumpFail "null";
BA_ "GenSigStartValue" SG_ 546 RearPassSeatMsgStrLvlStat 1;
BA_ "GenSigTimeoutTime_ALL" SG_ 546 RearPassSeatMsgStrLvlStat 800;
BA_ "InvalidValue" SG_ 546 RearPassSeatMsgStrLvlStat "7h";
BA_ "GenSigTimeoutTime_ALL" SG_ 549 Checksum_0x225 200;
BA_ "InvalidValue" SG_ 549 Checksum_0x225 "null";
BA_ "GenSigTimeoutTime_ALL" SG_ 549 Rolling_Counter_0x225 200;
BA_ "InvalidValue" SG_ 549 Rolling_Counter_0x225 "Fh";
BA_ "GenSigTimeoutTime_ALL" SG_ 549 CDM_bAcvCanComStblMon 200;
BA_ "InvalidValue" SG_ 549 CDM_bAcvCanComStblMon "null";
BA_ "GenSigTimeoutTime_ALL" SG_ 549 FRMo_bErrHvbatStReqExtMon 200;
BA_ "InvalidValue" SG_ 549 FRMo_bErrHvbatStReqExtMon "null";
BA_ "GenSigTimeoutTime_ALL" SG_ 549 FRMo_bErrChrgnAllwdExtMon 200;
BA_ "InvalidValue" SG_ 549 FRMo_bErrChrgnAllwdExtMon "null";
BA_ "GenSigTimeoutTime_ALL" SG_ 549 FRMo_bErrVehCrashStExtMon 200;
BA_ "InvalidValue" SG_ 549 FRMo_bErrVehCrashStExtMon "null";
BA_ "GenSigTimeoutTime_ALL" SG_ 549 CDM_bErrComctnLossCanMon 200;
BA_ "InvalidValue" SG_ 549 CDM_bErrComctnLossCanMon "null";
BA_ "GenSigTimeoutTime_ALL" SG_ 549 CTCMon_bErrCtctrSopcMon 200;
BA_ "InvalidValue" SG_ 549 CTCMon_bErrCtctrSopcMon "null";
BA_ "GenSigTimeoutTime_ALL" SG_ 549 CTCMon_bInvldCtctrHisdIFbMon 200;
BA_ "InvalidValue" SG_ 549 CTCMon_bInvldCtctrHisdIFbMon "null";
BA_ "GenSigTimeoutTime_ALL" SG_ 549 CTCMon_bInvldCtctrLosdUFbMon 200;
BA_ "InvalidValue" SG_ 549 CTCMon_bInvldCtctrLosdUFbMon "null";
BA_ "GenSigTimeoutTime_ALL" SG_ 549 CTM_bErrCellTDifMaxMon 200;
BA_ "InvalidValue" SG_ 549 CTM_bErrCellTDifMaxMon "null";
BA_ "GenSigTimeoutTime_ALL" SG_ 549 CTM_bErrCellTMaxMon 200;
BA_ "InvalidValue" SG_ 549 CTM_bErrCellTMaxMon "null";
BA_ "GenSigTimeoutTime_ALL" SG_ 549 CTM_bErrCellTMinMon 200;
BA_ "InvalidValue" SG_ 549 CTM_bErrCellTMinMon "null";
BA_ "GenSigTimeoutTime_ALL" SG_ 549 CTM_bErrThrwyPredMon 200;
BA_ "InvalidValue" SG_ 549 CTM_bErrThrwyPredMon "null";
BA_ "GenSigTimeoutTime_ALL" SG_ 549 CUM_bErrCellUDifMaxMon 200;
BA_ "InvalidValue" SG_ 549 CUM_bErrCellUDifMaxMon "null";
BA_ "GenSigTimeoutTime_ALL" SG_ 549 CUM_bErrCellUMaxMon 200;
BA_ "InvalidValue" SG_ 549 CUM_bErrCellUMaxMon "null";
BA_ "GenSigTimeoutTime_ALL" SG_ 549 CUM_bErrCellUMinMon 200;
BA_ "InvalidValue" SG_ 549 CUM_bErrCellUMinMon "null";
BA_ "GenSigTimeoutTime_ALL" SG_ 549 CUM_bErrCellUProtnMaxNvMon 200;
BA_ "InvalidValue" SG_ 549 CUM_bErrCellUProtnMaxNvMon "null";
BA_ "GenSigTimeoutTime_ALL" SG_ 549 CUM_bErrCellUProtnMinNvMon 200;
BA_ "InvalidValue" SG_ 549 CUM_bErrCellUProtnMinNvMon "null";
BA_ "GenSigTimeoutTime_ALL" SG_ 549 CUM_bErrPackUImplyMon 200;
BA_ "InvalidValue" SG_ 549 CUM_bErrPackUImplyMon "null";
BA_ "GenSigTimeoutTime_ALL" SG_ 549 EHPMon_bRdyHvilMon 200;
BA_ "InvalidValue" SG_ 549 EHPMon_bRdyHvilMon "null";
BA_ "GenSigTimeoutTime_ALL" SG_ 549 EHPMon_bErrWlddNegNvMon 200;
BA_ "InvalidValue" SG_ 549 EHPMon_bErrWlddNegNvMon "null";
BA_ "GenSigTimeoutTime_ALL" SG_ 549 EHPMon_bErrWlddPosNvMon 200;
BA_ "InvalidValue" SG_ 549 EHPMon_bErrWlddPosNvMon "null";
BA_ "GenSigTimeoutTime_ALL" SG_ 549 EHPMon_bErrWlddPrechNvMon 200;
BA_ "InvalidValue" SG_ 549 EHPMon_bErrWlddPrechNvMon "null";
BA_ "GenSigTimeoutTime_ALL" SG_ 549 EHPMon_bErrHvilMon 200;
BA_ "InvalidValue" SG_ 549 EHPMon_bErrHvilMon "null";
BA_ "GenSigTimeoutTime_ALL" SG_ 549 EHPMon_bErrHvilShoMon 200;
BA_ "InvalidValue" SG_ 549 EHPMon_bErrHvilShoMon "null";
BA_ "GenSigTimeoutTime_ALL" SG_ 549 EHPMon_bErrPackIslnRNvMon 200;
BA_ "InvalidValue" SG_ 549 EHPMon_bErrPackIslnRNvMon "null";
BA_ "GenSigTimeoutTime_ALL" SG_ 549 EHPMon_bErrVehCrashNvMon 200;
BA_ "InvalidValue" SG_ 549 EHPMon_bErrVehCrashNvMon "null";
BA_ "GenSigTimeoutTime_ALL" SG_ 549 EHPMon_bErrVehIslnRNvMon 200;
BA_ "InvalidValue" SG_ 549 EHPMon_bErrVehIslnRNvMon "null";
BA_ "GenSigTimeoutTime_ALL" SG_ 549 FRMo_bErrMemStorgNvMon 200;
BA_ "InvalidValue" SG_ 549 FRMo_bErrMemStorgNvMon "null";
BA_ "GenSigTimeoutTime_ALL" SG_ 549 L1IM_bErrClmp30MaxMonInp 200;
BA_ "InvalidValue" SG_ 549 L1IM_bErrClmp30MaxMonInp "null";
BA_ "GenSigTimeoutTime_ALL" SG_ 549 L1IM_bErrClmp30MinMonInp 200;
BA_ "InvalidValue" SG_ 549 L1IM_bErrClmp30MinMonInp "null";
BA_ "GenSigTimeoutTime_ALL" SG_ 549 L1IM_bErrCtctrDtrtMonInp 200;
BA_ "InvalidValue" SG_ 549 L1IM_bErrCtctrDtrtMonInp "null";
BA_ "GenSigTimeoutTime_ALL" SG_ 549 L1IM_bErrUActImplyMonInp 200;
BA_ "InvalidValue" SG_ 549 L1IM_bErrUActImplyMonInp "null";
BA_ "GenSigTimeoutTime_ALL" SG_ 549 MCCM_bAcvMdulCtlrStsMon 200;
BA_ "InvalidValue" SG_ 549 MCCM_bAcvMdulCtlrStsMon "null";
BA_ "GenSigTimeoutTime_ALL" SG_ 549 MCCM_bErrLntecSngFltMon 200;
BA_ "InvalidValue" SG_ 549 MCCM_bErrLntecSngFltMon "null";
BA_ "GenSigTimeoutTime_ALL" SG_ 549 MCCM_bErrLntecLtntFltMon 200;
BA_ "InvalidValue" SG_ 549 MCCM_bErrLntecLtntFltMon "null";
BA_ "GenSigTimeoutTime_ALL" SG_ 549 MCCM_bErrMdulCellSnsrCfgMon 200;
BA_ "InvalidValue" SG_ 549 MCCM_bErrMdulCellSnsrCfgMon "null";
BA_ "GenSigTimeoutTime_ALL" SG_ 549 MCCM_bErrMdulCtlrComMon 200;
BA_ "InvalidValue" SG_ 549 MCCM_bErrMdulCtlrComMon "null";
BA_ "GenSigTimeoutTime_ALL" SG_ 549 MCCM_bErrSnsrTEltlMon 200;
BA_ "InvalidValue" SG_ 549 MCCM_bErrSnsrTEltlMon "null";
BA_ "GenSigTimeoutTime_ALL" SG_ 549 MCCM_bWarnSnsrTEltlMon 200;
BA_ "InvalidValue" SG_ 549 MCCM_bWarnSnsrTEltlMon "null";
BA_ "GenSigTimeoutTime_ALL" SG_ 549 PCM_bRdySnsrIMon 200;
BA_ "InvalidValue" SG_ 549 PCM_bRdySnsrIMon "null";
BA_ "GenSigTimeoutTime_ALL" SG_ 549 PCM_bErrPackEFlowMaxLimMon 200;
BA_ "InvalidValue" SG_ 549 PCM_bErrPackEFlowMaxLimMon "null";
BA_ "GenSigTimeoutTime_ALL" SG_ 549 PCM_bErrPackIChDchaMaxLimMon 200;
BA_ "InvalidValue" SG_ 549 PCM_bErrPackIChDchaMaxLimMon "null";
BA_ "GenSigTimeoutTime_ALL" SG_ 549 PCM_bErrSnsrIImplyMon 200;
BA_ "InvalidValue" SG_ 549 PCM_bErrSnsrIImplyMon "null";
BA_ "GenSigTimeoutTime_ALL" SG_ 549 FRMo_bErrSnsrI1ExtMon 200;
BA_ "InvalidValue" SG_ 549 FRMo_bErrSnsrI1ExtMon "null";
BA_ "GenSigTimeoutTime_ALL" SG_ 549 PCM_bInvldSnsrI1Mon 200;
BA_ "InvalidValue" SG_ 549 PCM_bInvldSnsrI1Mon "null";
BA_ "GenSigTimeoutTime_ALL" SG_ 549 PCM_bInvldSnsrI2Mon 200;
BA_ "InvalidValue" SG_ 549 PCM_bInvldSnsrI2Mon "null";
BA_ "GenSigTimeoutTime_ALL" SG_ 549 FRMo_bErrSopcLvl3Mon 200;
BA_ "InvalidValue" SG_ 549 FRMo_bErrSopcLvl3Mon "null";
BA_ "GenSigTimeoutTime_ALL" SG_ 549 BMS_FRMo_Reserved_1 200;
BA_ "InvalidValue" SG_ 549 BMS_FRMo_Reserved_1 "null";
BA_ "GenSigTimeoutTime_ALL" SG_ 549 BMS_FRMo_Reserved_2 200;
BA_ "InvalidValue" SG_ 549 BMS_FRMo_Reserved_2 "null";
BA_ "GenSigTimeoutTime_ALL" SG_ 549 BMS_FRMo_Reserved_3 200;
BA_ "InvalidValue" SG_ 549 BMS_FRMo_Reserved_3 "null";
BA_ "GenSigTimeoutTime_ALL" SG_ 549 BMS_FRMo_Reserved_4 200;
BA_ "InvalidValue" SG_ 549 BMS_FRMo_Reserved_4 "null";
BA_ "GenSigTimeoutTime_ALL" SG_ 549 BMS_FRMo_Reserved_5 200;
BA_ "InvalidValue" SG_ 549 BMS_FRMo_Reserved_5 "null";
BA_ "GenSigTimeoutTime_ALL" SG_ 561 NDoorFLOutsideHandleFailure 200;
BA_ "InvalidValue" SG_ 561 NDoorFLOutsideHandleFailure "null";
BA_ "GenSigTimeoutTime_ALL" SG_ 561 NDoorLatchFLFailure 200;
BA_ "InvalidValue" SG_ 561 NDoorLatchFLFailure "null";
BA_ "GenSigTimeoutTime_ALL" SG_ 565 CHKSM_TRM_STATUS 500;
BA_ "InvalidValue" SG_ 565 CHKSM_TRM_STATUS "null";
BA_ "GenSigTimeoutTime_ALL" SG_ 565 ALIVE_TRM_STATUS 500;
BA_ "InvalidValue" SG_ 565 ALIVE_TRM_STATUS "Fh";
BA_ "GenSigTimeoutTime_ALL" SG_ 565 TowingDetected 500;
BA_ "InvalidValue" SG_ 565 TowingDetected "3h";
BA_ "GenSigTimeoutTime_ALL" SG_ 565 TrailerDetected 500;
BA_ "InvalidValue" SG_ 565 TrailerDetected "3h";
BA_ "GenSigStartValue" SG_ 569 NDoorRROutsideHandleFailure 1;
BA_ "GenSigTimeoutTime_ALL" SG_ 569 NDoorRROutsideHandleFailure 200;
BA_ "InvalidValue" SG_ 569 NDoorRROutsideHandleFailure "null";
BA_ "GenSigTimeoutTime_ALL" SG_ 569 NDoorLatchRRFailure 200;
BA_ "InvalidValue" SG_ 569 NDoorLatchRRFailure "null";
BA_ "InvalidValue" SG_ 570 IDB_WheelDirection_FR "3h";
BA_ "GenSigTimeoutTime_ALL" SG_ 570 IDB_WheelDirection_FR 1000;
BA_ "InvalidValue" SG_ 570 IDB_WheelDirection_FL "3h";
BA_ "GenSigTimeoutTime_ALL" SG_ 570 IDB_WheelDirection_FL 1000;
BA_ "InvalidValue" SG_ 570 IDB_WheelSpeedRC_FL "FFFEh";
BA_ "GenSigTimeoutTime_ALL" SG_ 570 IDB_WheelSpeedRC_FL 1000;
BA_ "InvalidValue" SG_ 570 IDB_WheelSpeedRC_FR "FFFEh";
BA_ "GenSigTimeoutTime_ALL" SG_ 570 IDB_WheelSpeedRC_FR 1000;
BA_ "GenSigTimeoutTime_ALL" SG_ 570 SECCAN_IDB_WheelSts_FR 1000;
BA_ "InvalidValue" SG_ 571 IDB_WheelDirection_RR "3h";
BA_ "GenSigTimeoutTime_ALL" SG_ 571 IDB_WheelDirection_RR 1000;
BA_ "InvalidValue" SG_ 571 IDB_WheelDirection_RL "3h";
BA_ "GenSigTimeoutTime_ALL" SG_ 571 IDB_WheelDirection_RL 1000;
BA_ "InvalidValue" SG_ 571 IDB_WheelSpeedRC_RL "FFFEh";
BA_ "GenSigTimeoutTime_ALL" SG_ 571 IDB_WheelSpeedRC_RL 1000;
BA_ "InvalidValue" SG_ 571 IDB_WheelSpeedRC_RR "FFFEh";
BA_ "GenSigTimeoutTime_ALL" SG_ 571 IDB_WheelSpeedRC_RR 1000;
BA_ "GenSigTimeoutTime_ALL" SG_ 571 SECCAN_IDB_WheelSts_RR 1000;
BA_ "GenSigTimeoutTime_ALL" SG_ 581 Checksum_0x245 200;
BA_ "InvalidValue" SG_ 581 Checksum_0x245 "null";
BA_ "GenSigTimeoutTime_ALL" SG_ 581 Rolling_Counter_0x245 200;
BA_ "InvalidValue" SG_ 581 Rolling_Counter_0x245 "Fh";
BA_ "GenSigStartValue" SG_ 581 BMS_ProbeNumMaxCellTemp 1;
BA_ "GenSigTimeoutTime_ALL" SG_ 581 BMS_ProbeNumMaxCellTemp 200;
BA_ "InvalidValue" SG_ 581 BMS_ProbeNumMaxCellTemp "null";
BA_ "GenSigStartValue" SG_ 581 BMS_MinCellTemp 80;
BA_ "GenSigTimeoutTime_ALL" SG_ 581 BMS_MinCellTemp 200;
BA_ "InvalidValue" SG_ 581 BMS_MinCellTemp "FFh";
BA_ "GenSigTimeoutTime_ALL" SG_ 581 BMS_ProbeNumMinCellTemp 200;
BA_ "InvalidValue" SG_ 581 BMS_ProbeNumMinCellTemp "null";
BA_ "GenSigStartValue" SG_ 581 BMS_PackTemp 80;
BA_ "GenSigTimeoutTime_ALL" SG_ 581 BMS_PackTemp 200;
BA_ "InvalidValue" SG_ 581 BMS_PackTemp "FFh";
BA_ "GenSigStartValue" SG_ 581 BMS_MaxCellTemp 80;
BA_ "GenSigTimeoutTime_ALL" SG_ 581 BMS_MaxCellTemp 200;
BA_ "InvalidValue" SG_ 581 BMS_MaxCellTemp "FFh";
BA_ "GenSigStartValue" SG_ 581 BMS_MaxMinDiffCellTemp 80;
BA_ "GenSigTimeoutTime_ALL" SG_ 581 BMS_MaxMinDiffCellTemp 200;
BA_ "InvalidValue" SG_ 581 BMS_MaxMinDiffCellTemp "FFh";
BA_ "GenSigTimeoutTime_ALL" SG_ 584 NDoorFROutsideHandleFailure 200;
BA_ "InvalidValue" SG_ 584 NDoorFROutsideHandleFailure "null";
BA_ "GenSigTimeoutTime_ALL" SG_ 584 NDoorLatchFRFailure 200;
BA_ "InvalidValue" SG_ 584 NDoorLatchFRFailure "null";
BA_ "GenSigTimeoutTime_ALL" SG_ 585 CHSKM_BMS_CoolntInletOutletTmp 50000;
BA_ "InvalidValue" SG_ 585 CHSKM_BMS_CoolntInletOutletTmp "null";
BA_ "GenSigTimeoutTime_ALL" SG_ 585 ALV_BMS_CoolntInletOutletTmp 50000;
BA_ "InvalidValue" SG_ 585 ALV_BMS_CoolntInletOutletTmp "Fh";
BA_ "GenSigStartValue" SG_ 585 BMS_CoolantInletTemp 80;
BA_ "GenSigTimeoutTime_ALL" SG_ 585 BMS_CoolantInletTemp 50000;
BA_ "InvalidValue" SG_ 585 BMS_CoolantInletTemp "null";
BA_ "GenSigStartValue" SG_ 585 BMS_CoolantOutletTemp 80;
BA_ "GenSigTimeoutTime_ALL" SG_ 585 BMS_CoolantOutletTemp 50000;
BA_ "InvalidValue" SG_ 585 BMS_CoolantOutletTemp "null";
BA_ "GenSigStartValue" SG_ 585 BMS_BDUTemp1 80;
BA_ "GenSigTimeoutTime_ALL" SG_ 585 BMS_BDUTemp1 50000;
BA_ "GenSigStartValue" SG_ 585 BMS_BDUTemp2 80;
BA_ "GenSigTimeoutTime_ALL" SG_ 585 BMS_BDUTemp2 50000;
BA_ "GenSigTimeoutTime_ALL" SG_ 588 CHSKM_BMS_VCU_THMReq 50000;
BA_ "InvalidValue" SG_ 588 CHSKM_BMS_VCU_THMReq "null";
BA_ "GenSigTimeoutTime_ALL" SG_ 588 ALV_BMS_VCU_THMReq 50000;
BA_ "InvalidValue" SG_ 588 ALV_BMS_VCU_THMReq "Fh";
BA_ "GenSigTimeoutTime_ALL" SG_ 588 BMS_FlowRate_Req 50000;
BA_ "InvalidValue" SG_ 588 BMS_FlowRate_Req "FFh";
BA_ "GenSigTimeoutTime_ALL" SG_ 588 BMS_CoolPwrDemand 50000;
BA_ "InvalidValue" SG_ 588 BMS_CoolPwrDemand "FFFh";
BA_ "GenSigTimeoutTime_ALL" SG_ 588 BMS_HeatPwrDemand 50000;
BA_ "InvalidValue" SG_ 588 BMS_HeatPwrDemand "FFFh";
BA_ "GenSigTimeoutTime_ALL" SG_ 588 BMS_VCU_PTCOnOff_Req 50000;
BA_ "InvalidValue" SG_ 588 BMS_VCU_PTCOnOff_Req "null";
BA_ "GenSigTimeoutTime_ALL" SG_ 588 BMS_VCU_ValveOnOff_Req 50000;
BA_ "InvalidValue" SG_ 588 BMS_VCU_ValveOnOff_Req "null";
BA_ "GenSigTimeoutTime_ALL" SG_ 588 BMS_PreHeatCoolReq 50000;
BA_ "InvalidValue" SG_ 588 BMS_PreHeatCoolReq "3h";
BA_ "GenSigTimeoutTime_ALL" SG_ 596 CRC_AVL_RPM_WHL_REAR 200;
BA_ "InvalidValue" SG_ 596 CRC_AVL_RPM_WHL_REAR "null";
BA_ "GenSigTimeoutTime_ALL" SG_ 596 ALIV_AVL_RPM_WHL_REAR 200;
BA_ "InvalidValue" SG_ 596 ALIV_AVL_RPM_WHL_REAR "Fh";
BA_ "GenSigStartValue" SG_ 596 AVL_RPM_WHL_RLH 32819;
BA_ "GenSigTimeoutTime_ALL" SG_ 596 AVL_RPM_WHL_RLH 200;
BA_ "GenSigStartValue" SG_ 596 AVL_RPM_WHL_RRH 32819;
BA_ "GenSigTimeoutTime_ALL" SG_ 596 AVL_RPM_WHL_RRH 200;
BA_ "GenSigTimeoutTime_ALL" SG_ 596 QU_AVL_RPM_WHL_RLH 200;
BA_ "InvalidValue" SG_ 596 QU_AVL_RPM_WHL_RLH "Fh";
BA_ "GenSigTimeoutTime_ALL" SG_ 596 QU_AVL_RPM_WHL_RRH 200;
BA_ "InvalidValue" SG_ 596 QU_AVL_RPM_WHL_RRH "Fh";
BA_ "GenSigTimeoutTime_ALL" SG_ 597 CRC_AVL_RPM_WHL_FRONT 200;
BA_ "InvalidValue" SG_ 597 CRC_AVL_RPM_WHL_FRONT "null";
BA_ "GenSigTimeoutTime_ALL" SG_ 597 ALIV_AVL_RPM_WHL_FRONT 200;
BA_ "InvalidValue" SG_ 597 ALIV_AVL_RPM_WHL_FRONT "Fh";
BA_ "GenSigStartValue" SG_ 597 AVL_RPM_WHL_FLH 32819;
BA_ "GenSigTimeoutTime_ALL" SG_ 597 AVL_RPM_WHL_FLH 200;
BA_ "GenSigStartValue" SG_ 597 AVL_RPM_WHL_FRH 32819;
BA_ "GenSigTimeoutTime_ALL" SG_ 597 AVL_RPM_WHL_FRH 200;
BA_ "GenSigTimeoutTime_ALL" SG_ 597 QU_AVL_RPM_WHL_FLH 200;
BA_ "InvalidValue" SG_ 597 QU_AVL_RPM_WHL_FLH "Fh";
BA_ "GenSigTimeoutTime_ALL" SG_ 597 QU_AVL_RPM_WHL_FRH 200;
BA_ "InvalidValue" SG_ 597 QU_AVL_RPM_WHL_FRH "Fh";
BA_ "GenSigTimeoutTime_ALL" SG_ 620 HU_PASDirSel 500;
BA_ "InvalidValue" SG_ 620 HU_PASDirSel "0";
BA_ "GenSigTimeoutTime_ALL" SG_ 620 HU_AutPrkgSlotSel 500;
BA_ "InvalidValue" SG_ 620 HU_AutPrkgSlotSel "0";
BA_ "GenSigTimeoutTime_ALL" SG_ 640 ANRC_PrkgRiSlotDst2_Y 250;
BA_ "InvalidValue" SG_ 640 ANRC_PrkgRiSlotDst2_Y "FFE";
BA_ "GenSigTimeoutTime_ALL" SG_ 640 ANRC_PrkgRiSlot2_VehAngal 250;
BA_ "InvalidValue" SG_ 640 ANRC_PrkgRiSlot2_VehAngal "1FF";
BA_ "GenSigTimeoutTime_ALL" SG_ 640 ANRC_PrkgRiSlotDst2_X 250;
BA_ "InvalidValue" SG_ 640 ANRC_PrkgRiSlotDst2_X "FFE";
BA_ "GenSigTimeoutTime_ALL" SG_ 641 NDoorRLOutsideHandleFailure 200;
BA_ "InvalidValue" SG_ 641 NDoorRLOutsideHandleFailure "null";
BA_ "GenSigTimeoutTime_ALL" SG_ 641 NDoorLatchRLFailure 200;
BA_ "InvalidValue" SG_ 641 NDoorLatchRLFailure "null";
BA_ "InvalidValue" SG_ 642 ANRC_PrkgLeSlotDst1_Y "FFE";
BA_ "GenSigTimeoutTime_ALL" SG_ 642 ANRC_PrkgLeSlotDst1_Y 250;
BA_ "InvalidValue" SG_ 642 ANRC_PrkgLeSlot1_VehAngal "1FF";
BA_ "GenSigTimeoutTime_ALL" SG_ 642 ANRC_PrkgLeSlot1_VehAngal 250;
BA_ "InvalidValue" SG_ 642 ANRC_PrkgLeSlotDst1_X "FFE";
BA_ "GenSigTimeoutTime_ALL" SG_ 642 ANRC_PrkgLeSlotDst1_X 250;
BA_ "InvalidValue" SG_ 643 ANRC_PrkgLeSlotDst2_Y "FFE";
BA_ "GenSigTimeoutTime_ALL" SG_ 643 ANRC_PrkgLeSlotDst2_Y 250;
BA_ "InvalidValue" SG_ 643 ANRC_PrkgLeSlot2_VehAngal "1FF";
BA_ "GenSigTimeoutTime_ALL" SG_ 643 ANRC_PrkgLeSlot2_VehAngal 250;
BA_ "InvalidValue" SG_ 643 ANRC_PrkgLeSlotDst2_X "FFE";
BA_ "GenSigTimeoutTime_ALL" SG_ 643 ANRC_PrkgLeSlotDst2_X 250;
BA_ "InvalidValue" SG_ 644 ANRC_PrkgRiSlotDst3_Y "FFE";
BA_ "GenSigTimeoutTime_ALL" SG_ 644 ANRC_PrkgRiSlotDst3_Y 250;
BA_ "InvalidValue" SG_ 644 ANRC_PrkgRiSlot3_VehAngal "1FF";
BA_ "GenSigTimeoutTime_ALL" SG_ 644 ANRC_PrkgRiSlot3_VehAngal 250;
BA_ "InvalidValue" SG_ 644 ANRC_PrkgRiSlotDst3_X "FFE";
BA_ "GenSigTimeoutTime_ALL" SG_ 644 ANRC_PrkgRiSlotDst3_X 250;
BA_ "GenSigTimeoutTime_ALL" SG_ 649 CHKSM_IDB_ZF2 200;
BA_ "InvalidValue" SG_ 649 ALIVE_IDB_ZF2 "Fh";
BA_ "GenSigTimeoutTime_ALL" SG_ 649 ALIVE_IDB_ZF2 200;
BA_ "InvalidValue" SG_ 649 AxOutStatus "1h";
BA_ "GenSigTimeoutTime_ALL" SG_ 649 AxOutStatus 200;
BA_ "InvalidValue" SG_ 649 QU_VYAW_VEH "Fh";
BA_ "GenSigTimeoutTime_ALL" SG_ 649 QU_VYAW_VEH 200;
BA_ "GenSigStartValue" SG_ 649 QU_VYAW_VEH 8;
BA_ "InvalidValue" SG_ 649 AyOutStatus "1h";
BA_ "GenSigTimeoutTime_ALL" SG_ 649 AyOutStatus 200;
BA_ "InvalidValue" SG_ 649 AcceleratorY "FFFh";
BA_ "GenSigTimeoutTime_ALL" SG_ 649 AcceleratorY 200;
BA_ "GenSigStartValue" SG_ 649 AcceleratorY 795;
BA_ "InvalidValue" SG_ 649 AcceleratorX "FFFh";
BA_ "GenSigTimeoutTime_ALL" SG_ 649 AcceleratorX 200;
BA_ "InvalidValue" SG_ 649 VYAW_VEH "FFFFh";
BA_ "GenSigTimeoutTime_ALL" SG_ 649 VYAW_VEH 200;
BA_ "GenSigStartValue" SG_ 649 VYAW_VEH 32768;
BA_ "GenSigTimeoutTime_ALL" SG_ 654 CHKSM_APM_WINDOW_POS 500;
BA_ "InvalidValue" SG_ 654 CHKSM_APM_WINDOW_POS "null";
BA_ "GenSigTimeoutTime_ALL" SG_ 654 ALV_APM_WINDOW_POS 500;
BA_ "InvalidValue" SG_ 654 ALV_APM_WINDOW_POS "Fh";
BA_ "GenSigTimeoutTime_ALL" SG_ 654 Window_PosFL 500;
BA_ "InvalidValue" SG_ 654 Window_PosFL "7h";
BA_ "GenSigTimeoutTime_ALL" SG_ 654 Window_Warning 500;
BA_ "InvalidValue" SG_ 654 Window_Warning "3h";
BA_ "GenSigTimeoutTime_ALL" SG_ 654 Wndow_PosRL 500;
BA_ "InvalidValue" SG_ 654 Wndow_PosRL "7h";
BA_ "GenSigTimeoutTime_ALL" SG_ 654 Window_PosFR 500;
BA_ "InvalidValue" SG_ 654 Window_PosFR "7h";
BA_ "GenSigTimeoutTime_ALL" SG_ 654 Global_close 500;
BA_ "InvalidValue" SG_ 654 Global_close "3h";
BA_ "GenSigTimeoutTime_ALL" SG_ 654 Global_open 500;
BA_ "InvalidValue" SG_ 654 Global_open "3h";
BA_ "GenSigTimeoutTime_ALL" SG_ 654 Window_PosRR 500;
BA_ "InvalidValue" SG_ 654 Window_PosRR "7h";
VAL_ 387 VCU_FS_B_1 0 "No error" 1 "Error";
VAL_ 387 VCU_FS_B_2 0 "No error" 1 "Error";
VAL_ 387 VCU_FS_B_3 0 "No error" 1 "Error";
VAL_ 387 VCU_FS_B_4 0 "No error" 1 "Error";
VAL_ 387 VCU_FS_B_5 0 "No error" 1 "Error";
VAL_ 387 VCU_FS_B_6 0 "No error" 1 "Error";
VAL_ 387 VCU_FS_B_7 0 "No error" 1 "Error";
VAL_ 387 VCU_FS_B_8 0 "No error" 1 "Error";
VAL_ 387 VCU_FS_B_9 0 "No error" 1 "Error";
VAL_ 387 VCU_FS_B_10 0 "No error" 1 "Error";
VAL_ 387 VCU_FS_B_11 0 "No error" 1 "Error";
VAL_ 387 VCU_FS_B_12 0 "No error" 1 "Error";
VAL_ 387 VCU_FS_B_13 0 "No error" 1 "Error";
VAL_ 387 VCU_FS_B_14 0 "No error" 1 "Error";
VAL_ 387 VCU_FS_B_15 0 "No error" 1 "Error";
VAL_ 387 VCU_FS_B_16 0 "No error" 1 "Error";
VAL_ 387 VCU_FS_B_17 0 "No error" 1 "Error";
VAL_ 387 VCU_FS_B_18 0 "No error" 1 "Error";
VAL_ 387 VCU_FS_B_19 0 "No error" 1 "Error";
VAL_ 387 VCU_FS_B_20 0 "No error" 1 "Error";
VAL_ 387 VCU_FS_B_21 0 "No error" 1 "Error";
VAL_ 387 VCU_FS_B_22 0 "No error" 1 "Error";
VAL_ 387 VCU_FS_B_23 0 "No error" 1 "Error";
VAL_ 387 VCU_FS_B_24 0 "No error" 1 "Error";
VAL_ 387 VCU_FS_B_25 0 "No error" 1 "Error";
VAL_ 387 VCU_FS_B_26 0 "No error" 1 "Error";
VAL_ 387 VCU_FS_B_27 0 "No error" 1 "Error";
VAL_ 387 VCU_FS_B_28 0 "No error" 1 "Error";
VAL_ 387 VCU_FS_B_29 0 "No error" 1 "Error";
VAL_ 387 VCU_FS_B_30 0 "No error" 1 "Error";
VAL_ 387 VCU_FS_B_31 0 "No error" 1 "Error";
VAL_ 387 VCU_FS_B_32 0 "No error" 1 "Error";
VAL_ 387 VCU_FS_B_33 0 "No error" 1 "Error";
VAL_ 387 VCU_FS_B_34 0 "No error" 1 "Error";
VAL_ 387 VCU_FS_B_35 0 "No error" 1 "Error";
VAL_ 387 VCU_FS_B_36 0 "No error" 1 "Error";
VAL_ 387 VCU_FS_B_37 0 "No error" 1 "Error";
VAL_ 387 VCU_FS_B_38 0 "No error" 1 "Error";
VAL_ 387 VCU_FS_B_39 0 "No error" 1 "Error";
VAL_ 387 VCU_FS_B_40 0 "No error" 1 "Error";
VAL_ 387 VCU_FS_B_41 0 "No error" 1 "Error";
VAL_ 387 VCU_FS_B_42 0 "No error" 1 "Error";
VAL_ 387 VCU_FS_B_43 0 "No error" 1 "Error";
VAL_ 387 VCU_FS_B_44 0 "No error" 1 "Error";
VAL_ 387 VCU_FS_B_45 0 "No error" 1 "Error";
VAL_ 387 VCU_FS_B_46 0 "No error" 1 "Error";
VAL_ 387 VCU_FS_B_47 0 "No error" 1 "Error";
VAL_ 387 VCU_FS_B_48 0 "No error" 1 "Error";
VAL_ 387 VCU_FS_B_49 0 "No error" 1 "Error";
VAL_ 387 VCU_FS_B_50 0 "No error" 1 "Error";
VAL_ 387 VCU_FS_B_51 0 "No error" 1 "Error";
VAL_ 387 VCU_FS_B_52 0 "No error" 1 "Error";
VAL_ 387 VCU_FS_B_53 0 "No error" 1 "Error";
VAL_ 387 VCU_FS_B_54 0 "No error" 1 "Error";
VAL_ 387 VCU_FS_B_55 0 "No error" 1 "Error";
VAL_ 387 VCU_FS_B_56 0 "No error" 1 "Error";
VAL_ 387 VCU_FS_B_57 0 "No error" 1 "Error";
VAL_ 387 VCU_FS_B_58 0 "No error" 1 "Error";
VAL_ 387 VCU_FS_B_59 0 "No error" 1 "Error";
VAL_ 387 VCU_FS_B_60 0 "No error" 1 "Error";
VAL_ 387 VCU_FS_B_61 0 "No error" 1 "Error";
VAL_ 387 VCU_FS_B_62 0 "No error" 1 "Error";
VAL_ 387 VCU_FS_B_63 0 "No error" 1 "Error";
VAL_ 387 VCU_FS_B_64 0 "No error" 1 "Error";
VAL_ 388 FCAM_BCM_IndicatorlightReq 0 "No request" 1 "Left" 2 "Right" 3 "Hazard" 4 "Turn Indicator Off" ;
VAL_ 389 VCU_FS_C_1 0 "normal" 1 "error" ;
VAL_ 389 VCU_FS_C_2 0 "normal" 1 "error" ;
VAL_ 389 VCU_FS_C_3 0 "normal" 1 "error" ;
VAL_ 389 VCU_FS_C_4 0 "normal" 1 "error" ;
VAL_ 389 VCU_FS_C_5 0 "normal" 1 "error" ;
VAL_ 389 VCU_FS_C_6 0 "normal" 1 "error" ;
VAL_ 389 VCU_FS_C_7 0 "normal" 1 "error" ;
VAL_ 389 VCU_FS_C_8 0 "normal" 1 "error" ;
VAL_ 389 VCU_FS_C_9 0 "normal" 1 "error" ;
VAL_ 389 VCU_FS_C_10 0 "normal" 1 "error" ;
VAL_ 389 VCU_FS_C_11 0 "normal" 1 "error" ;
VAL_ 389 VCU_FS_C_12 0 "normal" 1 "error" ;
VAL_ 389 VCU_FS_C_13 0 "normal" 1 "error" ;
VAL_ 389 VCU_FS_C_14 0 "normal" 1 "error" ;
VAL_ 389 VCU_FS_C_15 0 "normal" 1 "error" ;
VAL_ 389 VCU_FS_C_16 0 "normal" 1 "error" ;
VAL_ 389 VCU_FS_C_17 0 "normal" 1 "error" ;
VAL_ 389 VCU_FS_C_18 0 "normal" 1 "error" ;
VAL_ 389 VCU_FS_C_19 0 "normal" 1 "error" ;
VAL_ 389 VCU_FS_C_20 0 "normal" 1 "error" ;
VAL_ 389 VCU_FS_C_21 0 "normal" 1 "error" ;
VAL_ 389 VCU_FS_C_22 0 "normal" 1 "error" ;
VAL_ 389 VCU_FS_C_23 0 "normal" 1 "error" ;
VAL_ 389 VCU_FS_C_24 0 "normal" 1 "error" ;
VAL_ 389 VCU_FS_C_25 0 "normal" 1 "error" ;
VAL_ 389 VCU_FS_C_26 0 "normal" 1 "error" ;
VAL_ 389 VCU_FS_C_27 0 "normal" 1 "error" ;
VAL_ 389 VCU_FS_C_28 0 "normal" 1 "error" ;
VAL_ 389 VCU_FS_C_29 0 "normal" 1 "error" ;
VAL_ 389 VCU_FS_C_30 0 "normal" 1 "error" ;
VAL_ 389 VCU_FS_C_31 0 "normal" 1 "error" ;
VAL_ 389 VCU_FS_C_32 0 "normal" 1 "error" ;
VAL_ 389 VCU_FS_C_33 0 "normal" 1 "error" ;
VAL_ 389 VCU_FS_C_34 0 "normal" 1 "error" ;
VAL_ 389 VCU_FS_C_35 0 "normal" 1 "error" ;
VAL_ 389 VCU_FS_C_36 0 "normal" 1 "error" ;
VAL_ 389 VCU_FS_C_37 0 "normal" 1 "error" ;
VAL_ 389 VCU_FS_C_38 0 "normal" 1 "error" ;
VAL_ 389 VCU_FS_C_39 0 "normal" 1 "error" ;
VAL_ 389 VCU_FS_C_40 0 "normal" 1 "error" ;
VAL_ 389 VCU_FS_C_41 0 "normal" 1 "error" ;
VAL_ 389 VCU_FS_C_42 0 "normal" 1 "error" ;
VAL_ 389 VCU_FS_C_43 0 "normal" 1 "error" ;
VAL_ 389 VCU_FS_C_44 0 "normal" 1 "error" ;
VAL_ 389 VCU_FS_C_45 0 "normal" 1 "error" ;
VAL_ 389 VCU_FS_C_46 0 "normal" 1 "error" ;
VAL_ 389 VCU_FS_C_47 0 "normal" 1 "error" ;
VAL_ 389 VCU_FS_C_48 0 "normal" 1 "error" ;
VAL_ 389 VCU_FS_C_49 0 "normal" 1 "error" ;
VAL_ 389 VCU_FS_C_50 0 "normal" 1 "error" ;
VAL_ 389 VCU_FS_C_51 0 "normal" 1 "error" ;
VAL_ 389 VCU_FS_C_52 0 "normal" 1 "error" ;
VAL_ 389 VCU_FS_C_53 0 "normal" 1 "error" ;
VAL_ 389 VCU_FS_C_54 0 "normal" 1 "error" ;
VAL_ 389 VCU_FS_C_55 0 "normal" 1 "error" ;
VAL_ 389 VCU_FS_C_56 0 "normal" 1 "error" ;
VAL_ 389 VCU_FS_C_57 0 "normal" 1 "error" ;
VAL_ 389 VCU_FS_C_58 0 "normal" 1 "error" ;
VAL_ 389 VCU_FS_C_59 0 "normal" 1 "error" ;
VAL_ 389 VCU_FS_C_60 0 "normal" 1 "error" ;
VAL_ 389 VCU_FS_C_61 0 "normal" 1 "error" ;
VAL_ 389 VCU_FS_C_62 0 "normal" 1 "error" ;
VAL_ 389 VCU_FS_C_63 0 "normal" 1 "error" ;
VAL_ 389 VCU_FS_C_64 0 "normal" 1 "error" ;
VAL_ 400 CAM_CamSts 0 "Not Available for ADB" 1 "Available for ADB" 2 "Camera Fault" 3 "reserved" ;
VAL_ 400 CAM_AmbLi 0 "Not Active for HighBeam (Day)" 1 "Active for Highbeam (Night)" ;
VAL_ 400 CAM_RoadIllmn 0 "Road illumination Not Detected" 1 "Road illumination Detected" ;
VAL_ 400 CAM_Obj_TrfcStyle 0 "Unknown" 1 "Right Hand Traffic" 2 "Left Hand Traffic" 3 "Not Available" ;
VAL_ 401 CAM_Obj1_Valid 0 "Invalid" 1 "Valid" ;
VAL_ 401 CAM_Obj1_Typ 0 "Unknown" 1 "Oncoming Object" 2 "Preceding Object" 3 "Reflective Object " ;
VAL_ 404 CAM_Obj2_Valid 0 "Invalid" 1 "Valid" ;
VAL_ 404 CAM_Obj2_Typ 0 "Unknown" 1 "Oncoming Object" 2 "Preceding Object" 3 "Reflective Object " ;
VAL_ 406 CAM_Obj3_Valid 0 "Invalid" 1 "Valid" ;
VAL_ 406 CAM_Obj3_Typ 0 "Unknown" 1 "Oncoming Object" 2 "Preceding Object" 3 "Reflective Object " ;
VAL_ 409 VCU_BMS_HVOnOff_REQ 0 "forbid" 1 "allow";
VAL_ 410 CAM_Obj4_Valid 0 "Invalid" 1 "Valid" ;
VAL_ 410 CAM_Obj4_Typ 0 "Unknown" 1 "Oncoming Object" 2 "Preceding Object" 3 "Reflective Object " ;
VAL_ 412 CAM_Obj5_Valid 0 "Invalid" 1 "Valid" ;
VAL_ 412 CAM_Obj5_Typ 0 "Unknown" 1 "Oncoming Object" 2 "Preceding Object" 3 "Reflective Object " ;
VAL_ 413 CAM_Obj6_Valid 0 "Invalid" 1 "Valid" ;
VAL_ 413 CAM_Obj6_Typ 0 "Unknown" 1 "Oncoming Object" 2 "Preceding Object" 3 "Reflective Object " ;
VAL_ 414 CAM_Obj7_Valid 0 "Invalid" 1 "Valid" ;
VAL_ 414 CAM_Obj7_Typ 0 "Unknown" 1 "Oncoming Object" 2 "Preceding Object" 3 "Reflective Object " ;
VAL_ 415 CAM_Obj8_Valid 0 "Invalid" 1 "Valid" ;
VAL_ 415 CAM_Obj8_Typ 0 "Unknown" 1 "Oncoming Object" 2 "Preceding Object" 3 "Reflective Object " ;
VAL_ 417 DVCO_VEH 0 "Vehicle is stationary" 1 "Vehicle is moving forward" 2 "Vehicle is reversing" 3 "Vehicle is moving " 4 "Vehicle is stationary rear axle rol" 5 "Vehicle is stationary all axle roll" 6 "Vehicle is stationary Front axle roll" 7 "Signal invalid";
VAL_ 417 QU_V_VEH_COG 1 "Signal value is valid and secured and plausible" 2 "Reserved" 3 "Reserved" 4 "Reserved" 6 "Reserved" 7 "Reserved" 8 "Init" 9 "Reserved" 10 "Signal value is valid" 11 "Signal quality or monitoring limited" 12 "Reserved" 14 "Signal value is invalid" 15 "Signal invalid";
VAL_ 504 EDS_Work_STS_FR 0 "default" 1 "init" 2 "standby" 3 "precharge" 4 "normal" 5 "HVReady" 6 "6SO" 11 "shut down" 12 "after run" 13 "Failure" 14 "power off" 15 "invaild";
VAL_ 504 EDS_output_trqValid_FR 0 "invalid" 1 "valid";
VAL_ 504 EDS_MotorDriveSts_FR 0 "Zero control" 1 "Drive control" 2 "regen control" 3 "Invaild";
VAL_ 504 EDS_powoff_req_FR 0 "(No request)" 1 "(Request high voltage power down)";
VAL_ 504 EDS_SpdValid_FR 0 "invalid" 1 "valid";
VAL_ 504 EDS_VCU_6SO_flag_FWD 0 "OFF" 1 "ON";
VAL_ 505 EDS_Work_STS_RR 0 "default" 1 "init" 2 "standby" 3 "precharge" 4 "normal" 5 "HVReady" 6 "6SO" 11 "shut down" 12 "after run" 13 "Failure" 14 "power off" 15 "invaild";
VAL_ 505 EDS_output_trqValid_RR 0 "invalid" 1 "valid";
VAL_ 505 EDS_MotorDriveSts_RR 0 "Zero control" 1 "Drive control" 2 "regen control" 3 "Invaild";
VAL_ 505 EDS_powoff_req_RR 0 "(No request)" 1 "(Request high voltage power down)";
VAL_ 505 EDS_SpdValid_RR 0 "invalid" 1 "valid";
VAL_ 505 EDS_VCU_6SO_flag_RWD 0 "OFF" 1 "ON";
VAL_ 506 MHU_TouchEvtTyp 0 "One finger single click" 1 "One finger double click" 2 "One finger long press" 3 "One finger moving" 4 "Rotate" 5 "Release";
VAL_ 515 R1_LINE_TYPE 0 "No display" 1 "Solid Line" 2 "Dashed Line" 3 "Roadside";
VAL_ 515 R0_LINE_TYPE 0 "No display" 1 "solid line" 2 "dashed line" 3 "Roadside";
VAL_ 516 L1_LINE_TYPE 0 "NoDisplay" 1 "Solid Line" 2 "Dashed Line" 3 "Roadside";
VAL_ 516 L0_LINE_TYPE 0 "No display" 1 "solid line" 2 "dashed line" 3 "Roadside";
VAL_ 518 ADAS_HWA_Fautlstate 0 "no_error" 1 "HWA" 2 "fault" 3 "Reserved" ;
VAL_ 518 ADAS_ELK_check 0 "Available" 1 "Fault" 2 "Automatic deactivation" 3 "OFF-Manual Deactivation" ;
VAL_ 518 ADAS_handsoff_Warning_Mode_2 0 "No Warning!" 1 "Level 1" 2 "Level 2" 3 "Level 3" 4 "reserved" 5 "reserved" 6 "reserved" 7 "reserved" ;
VAL_ 518 ADAS_HWA_txtpopup 0 "-" 1 "None (Feature On)" 2 "None (Feature Off)" 3 "Please take over steering VinPilot error" 4 "VinPilot is unavailable Conditions not met" 5 "VinPilot is unavailable See Fault Details for more info" 6 "Take over driving now! VinPilot is Off" ;
VAL_ 518 ADAS_HWA_state 0 "Off" 1 "Stand_by" 2 "Active" 3 "Override" 4 "Passive" 5 "Active_suspend" 6 "Fault" ;
VAL_ 518 ADAS_Mode2_status 0 "Off Mode" 1 "Mode2_Standby" 2 "Mode2_Active" 3 "Mode2_Passive" ;
VAL_ 518 ADAS_handsoff_txtpopup 0 "Please Hold the Steering Wheel!" 1 "Please Hold the Steering Wheel Immediately!" 2 "Reserved" 3 "Reserved" ;
VAL_ 518 ADAS_ALC_txtpopup 0 "-" 1 "Initiating Lane Changeâ?¦" 2 "Lane Change in progressâ?¦" 3 "Lane Change Timeout Target lane unavailable" 4 "Lane Change Cancelled" 5 "Lane Change Cancelled Returning to lane center" 6 "Lane Change is unavailable Use steering wheel to change lanes" 7 "Take over driving now! Lane Change System Error" ;
VAL_ 518 ADAS_ALC_state 0 "Off" 1 "Stand_by" 2 "Active" 3 "Override" 4 "Passive" 5 "Active_suspend" 6 "Fault" ;
VAL_ 518 ADAS_LA_Display 0 "left none,right none" 1 "left white,right none" 2 "left none,right white" 3 "left white,right white" 4 "left Blue,right none" 5 "left none,right blue" 6 "left blue,right blue" 7 "left none, right red" 8 "left red,right none" 9 "left white,right red" 10 "left red,right white" 11 "left blue,right red" 12 "left red,right blue" 13 "left gray,right none" 14 "left none,right gray" 15 "left gray,right gray" ;
VAL_ 518 ADAS_ALC_Mode_feed 0 "OFF" 1 "ON" 2 "Reserved" 3 "Reserved";
VAL_ 519 SR_Undervoltage_Fault_Sts 0 "Normal" 1 "Fault";
VAL_ 519 SR_Overvoltage_Fault_Sts 0 "Normal" 1 "Fault";
VAL_ 519 SR_SLEEP_RQ 0 "Sleep Not Ready" 1 "Ready to Sleep";
VAL_ 519 SR_Position 0 "Unknown -Default" 1 "All Closed" 2 "All Closed To Tilt" 3 "Tilt" 4 "Tilt to Half Open" 5 "Half Open" 6 "Half Open to Open" 7 "ALL Open";
VAL_ 519 SR_Motor_Running_Sts 0 "Stop" 1 "Open Direction" 2 "Close Direction" 3 "Not Used";
VAL_ 519 SR_MotorReverse_Fault_Sts 0 "Normal" 1 "Fault";
VAL_ 519 SR_Hall_Fault_Sts 0 "Normal" 1 "Fault";
VAL_ 519 SR_Normalisation_Sts 0 "Normalised" 1 "Not normalised";
VAL_ 519 SR_Relay_Fault 0 "Normal" 1 "Fault";
VAL_ 519 SR_Commu_Fault_Sts 0 "Normal" 1 "Fault";
VAL_ 519 SR_Initialisation_Status 0 "Initialised" 1 "Not initialised";
VAL_ 519 SR_Ctrl_Result 0 "No Response" 1 "Running" 2 "Succeed" 3 "Failed";
VAL_ 519 SR_ThermalProtection_Fault_Sts 0 "Normal" 1 "Fault";
VAL_ 519 SR_Posit_Percentage 127 "Invalid";
VAL_ 519 SR_Operation_Stat 0 "Idle/Not pressed" 1 "Manual Slide Open" 2 "Manual Slide Closed" 3 "ManualTilt Open" 4 "Manual Tilt Closed" 5 "Auto Slide Open" 6 "Auto Slide Closed" 7 "Auto Tilt Open" 8 "Auto Tilt Closed";
VAL_ 519 SR_Error_RSP 0 "No Error" 1 "Error";
VAL_ 519 BCM_AutoSunroof_Sts 0 "OFF" 1 "Glass Only" 2 "Glass & Shade" 3 "Signal invalid";
VAL_ 520 SS_MotorReverse_Fault_Status 0 "Normal" 1 "Fault";
VAL_ 520 SS_Motor_Running_Status 0 "Stop" 1 "Open direction" 2 "Close direction" 3 "Not Used";
VAL_ 520 SS_Position 0 "Unknown-Default" 1 "All Closed" 2 "All Closed to Ajar" 3 "Ajar" 4 "Ajar to Half Open" 5 "Half Open" 6 "Half Open to Open" 7 "All Open";
VAL_ 520 SS_SLEEP_RQ 0 "Sleep Not Ready" 1 "Ready to Sleep";
VAL_ 520 SS_Undervoltage_Fault_Status 0 "Normal" 1 "Fault";
VAL_ 520 SS_Ctrl_Result 0 "No Response" 1 "Running" 2 "Succeed" 3 "Failed";
VAL_ 520 SS_Overvoltage_Fault_Status 0 "Normal" 1 "Fault";
VAL_ 520 SS_Relay_Fault 0 "Normal" 1 "Fault";
VAL_ 520 SS_Normalisation_Status 0 "Normalised" 1 "Not normalised";
VAL_ 520 SS_Hall_Fault_Status 0 "Normal" 1 "Fault";
VAL_ 520 SS_Commu_Fault_Status 0 "Normal" 1 "Fault";
VAL_ 520 SS_Initialisation_Status 0 "Normal" 1 "Fault";
VAL_ 520 SS_Posit_Percentage 127 "Invalid";
VAL_ 520 SS_ThermalProtection_Flt_Sts 0 "Normal" 1 "Fault";
VAL_ 520 SS_Operation_State 0 "Idle/Not pressed" 1 "Stop" 2 "Tilt Man" 3 "Tilt Auto" 4 "Close Man" 5 "Close Auto" 6 "Open Man" 7 "Open Auto";
VAL_ 520 SS_Error_RSP 0 "No Error" 1 "Error";
VAL_ 521 PAS_RAEB_check 0 "Available" 1 "Temporarily not available" 2 "Permanently not available" ;
VAL_ 521 PAS_RAEB_Mode_Feed 0 "Off" 1 "On" ;
VAL_ 521 PAS_RAEB_State 0 "Off" 1 "Inactive" 2 "Ready" 3 "PreFill" 4 "AEB Active" 5 "Standstill" 6 "Finished With Override" 7 "Finished Without Override" 8 "Error" 9 "Reserved" 10 "Reserved" 11 "Reserved" 12 "Reserved" 13 "Reserved" 14 "Reserved" 15 "Reserved" ;
VAL_ 521 PAS_RAEB_Warning 0 "No warning" 1 "Braking" 2 "Postfeedback" ;
VAL_ 522 ETG_Lift_Gate_Status 0 "Fully closed" 1 "Fully opened" 2 "Stoped halfway" 3 "Ready to open" 4 "Opening" 5 "Ready to close" 6 "Closing" 7 "SNA (Signal not available)";
VAL_ 522 ETG_Power_Latch_Status 0 "uninitialized" 1 "Stoped" 2 "Cinching" 3 "Cinching reset" 4 "Releasing" 5 "Releasing reset" 7 "SNA";
VAL_ 522 ETG_Latch_Segment 0 "Full latch" 1 "Half latch" 2 "Open latch" 3 "SNA";
VAL_ 522 ETG_DSW_Status 0 "Not active" 1 "Active";
VAL_ 522 ETG_GSW_Status 0 "Not active" 1 "Active";
VAL_ 522 ETG_LTS_Status 0 "Not active" 1 "Active";
VAL_ 522 ETG_RTS_Status 0 "Not active" 1 "Active";
VAL_ 522 ETG_HAL_Status 0 "Low level" 1 "High level";
VAL_ 522 ETG_FUL_Status 0 "Low level" 1 "High level";
VAL_ 522 ETG_AJR_Status 0 "Low level" 1 "High level";
VAL_ 522 ETG_NTL_Status 0 "Low level" 1 "High level";
VAL_ 522 ETG_ERR_Voltage 0 "Normal" 1 "Under voltage" 2 "Over voltage";
VAL_ 522 ETG_ERR_Left_Motor 0 "Normal" 1 "Open circuit" 2 "short circuit";
VAL_ 522 ETG_ERR_Right_Motor 0 "Normal" 1 "Open circuit" 2 "short circuit";
VAL_ 522 ETG_ERR_Latch 0 "Normal" 1 "Open circuit" 2 "short circuit";
VAL_ 522 ETG_ERR_Hall 0 "Normal" 1 "Hall power short circuit" 2 "Hall position out of range" 3 "Hall signal out of sync";
VAL_ 522 ETG_Lift_Motor_Stall 0 "Not active" 1 "Active";
VAL_ 522 ETG_Lift_Motor_AntiPinch 0 "Not active" 1 "Active";
VAL_ 522 ETG_Lift_Motor_Thermal 0 "Not active" 1 "Active";
VAL_ 522 ETG_Power_Latch_Thermal 0 "Not active" 1 "Active";
VAL_ 522 ETG_Abuse_Protection 0 "Not active" 1 "Active";
VAL_ 523 FKS_RespError 0 "Ok" 1 "Error active";
VAL_ 523 FKS_OpenReq 0 "Idle" 1 "Operation Request" 2 "Invalid" 3 "Invalid";
VAL_ 523 FKS_HWError 0 "No Error" 1 "Error";
VAL_ 523 FKS_AntennaError 0 "No Error" 1 "Bottom or Top Sensor not connected" 2 "Bottom sensor short to Power or GND" 3 "Top sensor short to Power or GND";
VAL_ 523 FKS_OverVolDected 0 "No Error" 1 "Error";
VAL_ 523 FKS_UnderVolDected 0 "No Error" 1 "Error";
VAL_ 523 FKS_activate_deactivate 0 "Deactivated" 1 "Activated" 2 "Reserved" 3 "Signal invalid";
VAL_ 525 ESPTransRequestType 0 "No action" 1 "Inhibit upshift" 2 "Inhibit downshift" 3 "Hold gear";
VAL_ 525 ABSFault 0 "No fault" 1 "Fault";
VAL_ 525 ABSActive 0 "Inactive" 1 "Active";
VAL_ 525 ESC_VehicleStandstill 0 "NO_VEHICLE_STANDSTILL" 1 "VEHICLE_STANDSTILL";
VAL_ 525 MCPressureSts 0 "Valid" 1 "Invalid";
VAL_ 525 VehicleSpdSts 0 "Valid" 1 "Invalid";
VAL_ 525 ESC_Braking_effort 0 "No brake force generated" 1 "Brake force generated";
VAL_ 525 BRAKE_LightonRequestEPBi 0 "Brake light OFF" 1 "Brake light ON" 2 "Reserved" 3 "Signal not available";
VAL_ 525 VDCActive 0 "Inactive" 1 "Active";
VAL_ 525 TCSActive 0 "Inactive" 1 "Active";
VAL_ 525 TCSAvailable 0 "Avialable" 1 "Unavailable";
VAL_ 525 IDBActive 0 "Inactive" 1 "Active";
VAL_ 525 IDBFault 0 "No fault" 1 "Fault";
VAL_ 525 ESC_VehicleHoldStat 0 "No vehicle hold" 1 "vehicle hold" 2 "reserved" 3 "reserved";
VAL_ 525 IDB_Power_Stage 0 "Motor Max Power 150Kw" 1 "Motor Max Power 300Kw" 2 "Reserved" 3 "Reserved" 15 "Invalid";
VAL_ 525 ESC_BrakeReleasedFailsafe 0 "No need to release brakes because of failsafe situation" 1 "ESC is releasing the brakes because of failsafe";
VAL_ 526 PAS_APA_ReqInfoDispTxt2 0 "No_Request" 1 "Req_Recover_Press_Pause" 2 "Req_Recover_Press_brake" 3 "Req_Recover_Close_Doors" 4 "Req_Recover_FoundObstacleInTrajectory" 5 "Req_Recover_DMS_Release" 6 "Req_Recover_driver_seatbelt_unbuckle" 7 "Req_Recover_EPB_Applied" 8 "Req_Recover_Luggage Door Open" 9 "Req_Recover_RD_Far" 10 "Req_Recover_Steering Wheel Hands-On" 11 "Req_Recover_Doors_unlock" 12 "Req_Recover_Unfold_Mirror" 13 "Req_Recover_Engine_Front_Door" 14 "Reserved" 15 "Reserved" ;
VAL_ 526 PAS_APA_ReqInfoDispTxt1 0 "No_Request" 1 "PAS internal failure." 2 "Related external ECU failure." 3 "Conflict with other functions." 4 "Vehicle speed is higher than limit." 5 "Powertrain system is not ready." 6 "Towing or Trailer detected." 7 "Reserved" ;
VAL_ 526 PAS_APA_ReqInfoDispTxt4 0 "No Request" 1 "Req_Mode Select" 2 "Req_Gear_D" 3 "Req_Slow_Down" 4 "Req_Stop" 5 "Req_ParkingSlot_Select" 6 "Req_Close_Trunk" 7 "Req_Close front_hood_lid" 8 "Reserved" 9 "Req_Buckle_Seat_Belt" 10 "Req_Unfold_Mirror" 11 "Req_Press_Brake_Pedal" 12 "Req_Release_Brake" 13 "Req_Select_Pull_out_Direction" 14 "Req_Press_ParkingSwitch" 15 "Req_Press_Resume" 16 "Req_Perform_DMS" 17 "Req_Leave_Vehicle" 18 "Req_Connect_RD" 19 "Req_Secure_Vehicle" 20 "Req_Select_PAS_RPA" 21 "Req_DMS_Resume" 22 "Req_SearchingProcess" 23 "Req_Close Door (all doors)" 24 "Req_Function off" 25 "Req Gear_P and EPB_Applied" 26 "Req_Steering Wheel_HandOff" 27 "Reserved" 28 "Reserved" 29 "Reserved" 30 "Reserved" 31 "Reserved" ;
VAL_ 526 PAS_APA_ReqInfoDispTxt3 0 "No Request" 1 "Req_Quit_Standby_Timeout" 2 "Req_Quit_Standby_DistanceDeactivation" 3 "Req_Quit_Pause_Timeout" 4 "Req_Quit_Trajectory" 5 "Req_Quit_Space_Limit" 6 "Req_Quit_Speed_High" 7 "Req_Quit_Accelerator_pedal_pressed" 8 "Req_Quit_ACC" 9 "Req_Quit_HWA" 10 "Req_Quit_driver_seatbelt_unbuckle" 11 "Req_Quit_Driver_Door_opened" 12 "Req_Quit_Deactivation_Button_Pressed" 13 "Req_Quit_Driver_Gear_Intervention" 14 "Req_Quit_Gear_Interrupt" 15 "Req_Quit_EPB_Applied" 16 "Req_Quit_Vehicle Block" 17 "Req_Quit_Steering_Wheel_Intervention" 18 "Req_Quit_PAS_Failure" 19 "Req_Quit_External_ECU_failure" 20 "Req_Quit_No_Pull" 21 "Req_Quit_Engine_Front_Door_Open" 22 "Req_Quit_External_ECU_active" 23 "Req_Quit_Driver_Seatbelt_Buckle" 24 "Req_Quit_Passenger_Seatbelt_Unbuckle" 25 "Req_Quit_RD_Low_Batt" 26 "Req_Quit_RD_Offline" 27 "Req_Quit_RPA_Page_Off" 28 "Req_Quit_RD_Failure" 29 "Req_Quit_RD_Deactivation_Request" 30 "Req_Quit_Remote_Connection_Timeout" 31 "Req_Quit_Function_Safety" 32 "Req_Quit_Move times overflow" 33 "Req_Quit_Recover_Interrupt_Times_Overflow" 34 "Req_Quit_Luggage Door Open" 35 "Req_Quit_Surround_View" 36 "Req_Quit_MovingControl_Timeout" 37 "Req_Quit_Unsafe_Behavior" 38 "Req_Quit_Door_Lock" 39 "Req_Quit_Slope_exceed_limitation" ;
VAL_ 526 PAS_RP_ReqInfoDispTxt1 0 "No Request" 1 "Req_Quit_Standby_Timeout" 2 "Req_Quit_Standby_DistanceDeactivation" 3 "Req_Quit_Pause_Timeout" 4 "Req_Quit_Trajectory" 5 "Req_Quit_Space_Limit" 6 "Req_Quit_Speed_High" 7 "Req_Quit_Accelerator_pedal_pressed" 8 "Req_Quit_ACC" 9 "Req_Quit_HWA" 10 "Req_Quit_driver_seatbelt_unbuckle" 11 "Req_Quit_Driver_Door_opened" 12 "Req_Quit_Deactivation_Button_Pressed" 13 "Req_Quit_Driver_Gear_Intervention" 14 "Req_Quit_Gear_Interrupt" 15 "Req_Quit_EPB_Applied" 16 "Req_Quit_Vehicle Block" 17 "Req_Quit_Steering_Wheel_Intervention" 18 "Req_Quit_PAS_Failure" 19 "Req_Quit_External_ECU_failure" 20 "Req_Quit_No_Pull" 21 "Req_Quit_Engine_Front_Door_Open" 22 "Req_Quit_External_ECU_active" 23 "Req_Quit_Driver_Seatbelt_Buckle" 24 "Req_Quit_Passenger_Seatbelt_Unbuckle" 25 "Req_Quit_RD_Low_Batt" 26 "Req_Quit_RD_Offline" 27 "Req_Quit_RPA_Page_Off" 28 "Req_Quit_RD_Failure" 29 "Req_Quit_RD_Deactivation_Request" 30 "Req_Quit_Remote_Connection_Timeout" 31 "Req_Quit_Function_Safety" 32 "Req_Quit_Move times overflow" 33 "Req_Quit_Recover_Interrupt_Times_Overflow" 34 "Req_Quit_Luggage Door Open" 35 "Req_Quit_Surround_View" 36 "Req_Quit_MovingControl_Timeout" 37 "Req_Quit_Unsafe_Behavior" 38 "Req_Quit_Door_Lock" ;
VAL_ 526 PAS_RP_ReqInfoDispTxt2 0 "No Request" 1 "Req_Mode Select" 2 "Req_Gear_D" 3 "Req_Slow_Down" 4 "Req_Stop" 5 "Req_ParkingSlot_Select" 6 "Req_Close_Trunk" 7 "Req_Close front_hood_lid" 8 "Reserved" 9 "Req_Buckle_Seat_Belt" 10 "Req_Unfold_Mirror" 11 "Req_Press_Brake_Pedal" 12 "Req_Release_Brake" 13 "Req_Select_Pull_out_Direction" 14 "Req_Press_ParkingSwitch" 15 "Req_Press_Resume" 16 "Req_Perform_DMS" 17 "Req_Leave_Vehicle" 18 "Req_Connect_RD" 19 "Req_Secure_Vehicle" 20 "Req_Select_PAS_RPA" 21 "Req_DMS_Resume" 22 "Req_SearchingProcess" 23 "Req_Close Door (all doors)" 24 "Req_Function off" 25 "Req Gear_P and EPB_Applied" 26 "Req_Steering Wheel_HandOff" 27 "Reserved" 28 "Reserved" 29 "Reserved" 30 "Reserved" 31 "Reserved" ;
VAL_ 527 ADAS_BCM_HeadlightReq 0 "No request" 1 "Request turn on" ;
VAL_ 527 ADAS_BCM_FoldMirrorReq 0 "No request" 1 "Fold in" 2 "Fold out" 3 "Reserved" ;
VAL_ 527 ADAS_BCM_Status 0 "Off" 1 "Standby" 2 "Enable" 3 "Active" 4 "Finished" 5 "Suspend" 6 "Abort" 7 "Failed" ;
VAL_ 527 ADAS_BCM_IndicatorlightReq 0 "No request" 1 "Left" 2 "Right" 3 "Hazard" 4 "Turn Indicator Off" ;
VAL_ 531 VCU_enableDCDC 0 "Request OFF" 1 "Request ON";
VAL_ 533 BMS_BatBalance_ERR 0 "Error" 1 "normal";
VAL_ 533 BMS_Balance_STS 0 "Inactive" 1 "active";
VAL_ 533 BMS_IGN_Sts 0 "OFF" 1 "ON";
VAL_ 533 BMS_HWCrash_Sts 0 "No Crash" 1 "Crash";
VAL_ 533 BMS_HVIL_STS 0 "Closed" 1 "Open & short to battery" 2 "short to ground" 3 "Signal invalid";
VAL_ 533 BMS_HVOnOff_STS 0 "HV Off" 1 "Precharge" 2 "HV On" 3 "Fail to HV on";
VAL_ 533 BMS_ERR_LEV 0 "No error" 1 "Warning" 2 "Limp Home" 3 "Power down without FTTI" 4 "Delay power down with FTTI" 5 "Emergency off condition" 6 "Fault, needs to shutdown and wakeup" 7 "Battery locked - reserved";
VAL_ 533 BMS_Sys_STS 0 "Initialization of power on, self-checking" 1 "Self-check passes, can be high-voltage" 2 "Successful High Voltage Power Up" 3 "Successful Power Down of HV" 4 "Power Down process" 5 "Successful Power Down" 6 "BCU Sleep mode" 7 "Failure, unable to operate" 8 "Invalid";
VAL_ 533 BMS_ISU_Status 0 "Normal (> 250 kOhms)" 1 "Level1 (<250 kOhms ~ >100 kOhms)" 3 "Level3 (<100 kOhms)";
VAL_ 533 BMS_HV_Sts 0 "HV Off" 1 "Pre Charge" 2 "HV On" 3 "Super_Fast_Charge" 4 "AC Charge" 5 "Undefined" 6 "Undefined" 7 "Undefined" 8 "Undefined" 9 "Undefined";
VAL_ 538 DMS_HeadPitch 255 "Invalid" ;
VAL_ 538 DMS_HeadRoll 255 "Invalid" ;
VAL_ 538 DMS_HeadYaw 255 "Invalid" ;
VAL_ 538 DMS_HeadX 2047 "Invalid" ;
VAL_ 538 DMS_HeadY 2047 "Invalid" ;
VAL_ 538 DMS_HeadZ 2047 "Invalid" ;
VAL_ 540 FCAM_AEB_Warning 0 "No warning" 1 "Braking" 2 "Post Feedback" ;
VAL_ 540 FCAM_AEB_State 0 "OFF State" 1 "Stand by Mode" 2 "Active Mode" 3 "Hold Mode" ;
VAL_ 540 FCAM_AEB_Mode_Feed 0 "Off" 1 "ON" ;
VAL_ 540 FCAM_AEB_check 0 "Available" 1 "Temporarily not available" 2 "Permanently not available" ;
VAL_ 544 MHU_SET_CCUR_AirCondition 0 "Not pressed" 1 "Pressed" 2 "Reserved" 3 "Signal invalid";
VAL_ 544 MHU_SET_CCUR_AutoAC 0 "Not pressed" 1 "Pressed" 2 "Reserved" 3 "Signal invalid";
VAL_ 544 MHU_SET_CCUR_RearLock 0 "Not pressed" 1 "Pressed" 2 "Reserved" 3 "Signal invalid";
VAL_ 544 MHU_SET_CCUR_MaxAc 0 "Not pressed" 1 "Pressed" 2 "Reserved" 3 "Signal invalid";
VAL_ 544 MHU_SET_CCUR_FanSpeed 0 "OFF" 1 "Level1" 2 "Level2" 3 "Level3" 4 "Level4" 5 "Level5" 6 "Level6" 7 "Signal invalid";
VAL_ 544 MHU_SET_CCUR_Recirculation 0 "Inside" 1 "Outside" 2 "Auto" 3 "Signal invalid";
VAL_ 544 MHU_SET_CCUR_Ion 0 "Not pressed" 1 "Pressed" 2 "Reserved" 3 "Signal invalid" ;
VAL_ 544 MHU_SET_CCUR_FlapPosition 0 "OFF" 1 "Face" 2 "Face and Feet" 3 "Feet" 4 "Feet and Defrost" 5 "Defrost" 6 "Default" 7 "Signal Invalid";
VAL_ 544 MHU_SET_CCUR_SyncClimateZone 0 "Not pressed" 1 "Pressed" 2 "Reserved" 3 "Signal invalid";
VAL_ 544 MHU_SET_CCUR_TempRear 32 "16" 33 "16.5" 34 "17" 35 "17.5" 36 "18" 37 "18.5" 38 "19" 39 "19.5" 40 "20" 41 "20.5" 42 "21" 43 "21.5" 44 "22" 45 "22.5" 46 "23" 47 "23.5" 48 "24" 49 "24.5" 50 "25" 51 "25.5" 52 "26" 53 "26.5" 54 "27" 55 "27.5" 56 "28" 57 "28.5" 58 "29" 59 "29.5" 60 "30" 61 "30.5" 62 "31" 63 "31.5" 64 "32" 255 "Invalid Value";
VAL_ 544 MHU_SET_CCUR_FrontDefrost 0 "Not pressed" 1 "Pressed" 2 "Reserved" 3 "Signal invalid";
VAL_ 545 DrvSeatMsgStrLvl 0 "OFF" 1 "Initial value" 2 "Level 1(Weak)" 3 "Level 2(General)" 4 "Level 3(Strong)" 5 "Not used" 6 "Not used" 7 "Not used";
VAL_ 545 PassSeatMsgStrLvl 0 "OFF" 1 "Intial value" 2 "Level 1 (Weak)" 3 "Level 2 (General)" 4 "Level 3 (Strong)" 5 "Not used" 6 "Not used" 7 "Not used";
VAL_ 545 RearDrvSeatMsgStrLvl 0 "Invalid" 1 "Initial value" 2 "Level 1 (Weak)" 3 "Level 2 (General)" 4 "Level 3 (Strong)" 5 "Not used" 6 "Not used" 7 "Not used";
VAL_ 545 RearPassSeatMsgStrLvl 0 "OFF" 1 "Initial value" 2 "Level 1(Weak)" 3 "Level 2(General)" 4 "Level 3(Strong)" 5 "Not used" 6 "Not used" 7 "Not used";
VAL_ 545 DrvSeatMsgMode 0 "OFF" 1 "Wave Mode" 2 "Cat Paw Mode" 3 "Cross Mode" 4 "Relieve Mode" 5 "Jump Mode" 6 "Invalid" 7 "Not used";
VAL_ 545 PassSeatMsgMode 0 "OFF" 1 "Wave Mode" 2 "Cat Paw Mode" 3 "Cross Mode" 4 "Relieve Mode" 5 "Jump Mode" 6 "Invalid" 7 "Not used";
VAL_ 545 RearDrvSeatMsgMode 0 "OFF" 1 "Wave Mode" 2 "Cat Paw Mode" 3 "Cross Mode" 4 "Relieve Mode" 5 "Jump Mode" 6 "Invalid" 7 "Not used";
VAL_ 545 RearPassSeatMsgMode 0 "OFF" 1 "Wave mode" 2 "Cat Paw Mode" 3 "Cross Mode" 4 "Relieve Mode" 5 "Jump Mode" 6 "invalid" 7 "Not used";
VAL_ 546 DrvSeatMsgModeStat 0 "OFF" 1 "Wave Mode" 2 "Cat Paw Mode" 3 "Cross Mode" 4 "Relieve Mode" 5 "Jump Mode" 6 "Invalid" 7 "Not used";
VAL_ 546 PassSeatMsgModeStat 0 "OFF" 1 "Wave Mode" 2 "Cat Paw Mode" 3 "Cross Mode" 4 "Relieve Mode" 5 "Jump Mode" 6 "Invalid" 7 "Not used";
VAL_ 546 RearDrvSeatMsgModeStat 0 "OFF" 1 "Wave mode" 2 "Cat Paw Mode" 3 "Cross Mode" 4 "Relieve Mode" 5 "Jump Mode" 6 "invalid" 7 "Not used";
VAL_ 546 RearPassSeatMsgModeStat 0 "OFF" 1 "Wave mode" 2 "Cat Paw Mode" 3 "Cross Mode" 4 "Relieve Mode" 5 "Jump Mode" 6 "invalid" 7 "Not used";
VAL_ 546 LSSM_ALINResErr 0 "No Error" 1 "Error";
VAL_ 546 LSSM_APumpFail 0 "Invalid" 1 "No Error" 2 "Error" 3 "Reserved";
VAL_ 546 DrvSeatMsgStrLvlStat 0 "OFF" 1 "Initial value" 2 "Level 1(Weak)" 3 "Level 2(General)" 4 "Level 3(Strong)" 5 "Not used" 6 "Not used" 7 "Not used";
VAL_ 546 LSSM_BLINResErr 0 "No Error" 1 "Error";
VAL_ 546 LSSM_BPumpFail 0 "Invalid" 1 "No Error" 2 "Error" 3 "Reserved";
VAL_ 546 PassSeatMsgStrLvlStat 0 "Invalid" 1 "Initial value" 2 "Level 1 (Weak)" 3 "Level 2 (General)" 4 "Level 3 (Strong)" 5 "Not used" 6 "Not used" 7 "Not used";
VAL_ 546 LSSM_CLINResErr 0 "No Error" 1 "Error";
VAL_ 546 LSSM_CPumpFail 0 "Invalid" 1 "No Error" 2 "Error" 3 "Reserved";
VAL_ 546 RearDrvSeatMsgStrLvlStat 0 "Invalid" 1 "Initial value" 2 "Level 1 (Weak)" 3 "Level 2 (General)" 4 "Level 3 (Strong)" 5 "Not used" 6 "Not used" 7 "Not used";
VAL_ 546 LSSM_DLINResErr 0 "No Error" 1 "Error";
VAL_ 546 LSSM_DPumpFail 0 "Invalid" 1 "No Error" 2 "Error" 3 "Reserved";
VAL_ 546 RearPassSeatMsgStrLvlStat 0 "OFF" 1 "Initial value" 2 "Level 1(Weak)" 3 "Level 2(General)" 4 "Level 3(Strong)" 5 "Not used" 6 "Not used" 7 "Not used";
VAL_ 549 CDM_bAcvCanComStblMon 0 "No error" 1 "Error";
VAL_ 549 FRMo_bErrHvbatStReqExtMon 0 "No error" 1 "Error";
VAL_ 549 FRMo_bErrChrgnAllwdExtMon 0 "No error" 1 "Error";
VAL_ 549 FRMo_bErrVehCrashStExtMon 0 "No error" 1 "Error";
VAL_ 549 CDM_bErrComctnLossCanMon 0 "No error" 1 "Error";
VAL_ 549 CTCMon_bErrCtctrSopcMon 0 "No error" 1 "Error";
VAL_ 549 CTCMon_bInvldCtctrHisdIFbMon 0 "No error" 1 "Error";
VAL_ 549 CTCMon_bInvldCtctrLosdUFbMon 0 "No error" 1 "Error";
VAL_ 549 CTM_bErrCellTDifMaxMon 0 "No error" 1 "Error";
VAL_ 549 CTM_bErrCellTMaxMon 0 "No error" 1 "Error";
VAL_ 549 CTM_bErrCellTMinMon 0 "No error" 1 "Error";
VAL_ 549 CTM_bErrThrwyPredMon 0 "No error" 1 "Error";
VAL_ 549 CUM_bErrCellUDifMaxMon 0 "No error" 1 "Error";
VAL_ 549 CUM_bErrCellUMaxMon 0 "No error" 1 "Error";
VAL_ 549 CUM_bErrCellUMinMon 0 "No error" 1 "Error";
VAL_ 549 CUM_bErrCellUProtnMaxNvMon 0 "No error" 1 "Error";
VAL_ 549 CUM_bErrCellUProtnMinNvMon 0 "No error" 1 "Error";
VAL_ 549 CUM_bErrPackUImplyMon 0 "No error" 1 "Error";
VAL_ 549 EHPMon_bRdyHvilMon 0 "No error" 1 "Error";
VAL_ 549 EHPMon_bErrWlddNegNvMon 0 "No error" 1 "Error";
VAL_ 549 EHPMon_bErrWlddPosNvMon 0 "No error" 1 "Error";
VAL_ 549 EHPMon_bErrWlddPrechNvMon 0 "No error" 1 "Error";
VAL_ 549 EHPMon_bErrHvilMon 0 "No error" 1 "Error";
VAL_ 549 EHPMon_bErrHvilShoMon 0 "No error" 1 "Error";
VAL_ 549 EHPMon_bErrPackIslnRNvMon 0 "No error" 1 "Error";
VAL_ 549 EHPMon_bErrVehCrashNvMon 0 "No error" 1 "Error";
VAL_ 549 EHPMon_bErrVehIslnRNvMon 0 "No error" 1 "Error";
VAL_ 549 FRMo_bErrMemStorgNvMon 0 "No error" 1 "Error";
VAL_ 549 L1IM_bErrClmp30MaxMonInp 0 "No error" 1 "Error";
VAL_ 549 L1IM_bErrClmp30MinMonInp 0 "No error" 1 "Error";
VAL_ 549 L1IM_bErrCtctrDtrtMonInp 0 "No error" 1 "Error";
VAL_ 549 L1IM_bErrUActImplyMonInp 0 "No error" 1 "Error";
VAL_ 549 MCCM_bAcvMdulCtlrStsMon 0 "No error" 1 "Error";
VAL_ 549 MCCM_bErrLntecSngFltMon 0 "No error" 1 "Error";
VAL_ 549 MCCM_bErrLntecLtntFltMon 0 "No error" 1 "Error";
VAL_ 549 MCCM_bErrMdulCellSnsrCfgMon 0 "No error" 1 "Error";
VAL_ 549 MCCM_bErrMdulCtlrComMon 0 "No error" 1 "Error";
VAL_ 549 MCCM_bErrSnsrTEltlMon 0 "No error" 1 "Error";
VAL_ 549 MCCM_bWarnSnsrTEltlMon 0 "No error" 1 "Error";
VAL_ 549 PCM_bRdySnsrIMon 0 "No error" 1 "Error";
VAL_ 549 PCM_bErrPackEFlowMaxLimMon 0 "No error" 1 "Error";
VAL_ 549 PCM_bErrPackIChDchaMaxLimMon 0 "No error" 1 "Error";
VAL_ 549 PCM_bErrSnsrIImplyMon 0 "No error" 1 "Error";
VAL_ 549 FRMo_bErrSnsrI1ExtMon 0 "No error" 1 "Error";
VAL_ 549 PCM_bInvldSnsrI1Mon 0 "No error" 1 "Error";
VAL_ 549 PCM_bInvldSnsrI2Mon 0 "No error" 1 "Error";
VAL_ 549 FRMo_bErrSopcLvl3Mon 0 "No error" 1 "Error";
VAL_ 549 BMS_FRMo_Reserved_1 0 "No error" 1 "Error";
VAL_ 549 BMS_FRMo_Reserved_2 0 "No error" 1 "Error";
VAL_ 549 BMS_FRMo_Reserved_3 0 "No error" 1 "Error";
VAL_ 549 BMS_FRMo_Reserved_4 0 "No error" 1 "Error";
VAL_ 549 BMS_FRMo_Reserved_5 0 "No error" 1 "Error";
VAL_ 561 NDoorFLOutsideHandleFailure 0 "Default (No Failure)" 1 "EEPROM, ROM and DSP self-test" 2 "Magnetic field is too low" 3 "Magnetic field is too high" 4 "Overvoltage" 5 "Undervoltage" 6 "A/D converter clipping" 7 "Reserved";
VAL_ 561 NDoorLatchFLFailure 0 "no fault" 1 "fault code" 2 "fault code" 3 "fault code" 4 "fault code" 5 "fault code" 6 "fault code" 63 "fault code";
VAL_ 565 TowingDetected 0 "Towing not detected" 1 "Towing detected" 3 "Invalid";
VAL_ 565 TrailerDetected 0 "Trailer not detected" 1 "Trailer detected" 3 "Invalid";
VAL_ 569 NDoorRROutsideHandleFailure 0 "Default (No Failure)" 1 "EEPROM, ROM and DSP self-test" 2 "Magnetic field is too low" 3 "Magnetic field is too high" 4 "Overvoltage" 5 "Undervoltage" 6 "A/D converter clipping" 7 "Reserved";
VAL_ 569 NDoorLatchRRFailure 0 "No Fault" 1 "Fault Code" 2 "Fault Code" 3 "Fault Code" 4 "Fault Code" 5 "Fault Code" 6 "Fault Code" 7 "Fault Code" 8 "Fault Code" 9 "Fault Code" 10 "Fault Code" 11 "Fault Code" 12 "Fault Code" 13 "Fault Code" 14 "Fault Code" 127 "Fault Code";
VAL_ 570 IDB_WheelDirection_FR 0 "Standstill" 1 "Forward" 2 "Backward" 3 "Invalid" ;
VAL_ 570 IDB_WheelDirection_FL 0 "Standstill" 1 "Forward" 2 "Backward" 3 "Invalid" ;
VAL_ 571 IDB_WheelDirection_RR 0 "Standstill" 1 "Forward" 2 "Backward" 3 "Invalid" ;
VAL_ 571 IDB_WheelDirection_RL 0 "Standstill" 1 "Forward" 2 "Backward" 3 "Invalid" ;
VAL_ 581 BMS_ProbeNumMaxCellTemp 0 "Invalid" 62 "Error" 63 "Invalid";
VAL_ 581 BMS_ProbeNumMinCellTemp 0 "Invalid" 62 "Error" 63 "Invalid";
VAL_ 584 NDoorFROutsideHandleFailure 0 "Default (No Failure)" 1 "EEPROM, ROM and DSP self-test" 2 "Magnetic field is too low" 3 "Magnetic field is too high" 4 "Overvoltage" 5 "Undervoltage" 6 "A/D converter clipping" 7 "Reserved";
VAL_ 584 NDoorLatchFRFailure 0 "No Fault" 1 "Fault Code" 2 "Fault Code" 3 "Fault Code" 4 "Fault Code" 5 "Fault Code" 6 "Fault Code" 7 "Fault Code" 8 "Fault Code" 9 "Fault Code" 10 "Fault Code" 11 "Fault Code" 12 "Fault Code" 13 "Fault Code" 14 "Fault Code" 127 "Fault Code";
VAL_ 588 BMS_VCU_PTCOnOff_Req 0 "OFF" 1 "ON";
VAL_ 588 BMS_VCU_ValveOnOff_Req 0 "close" 1 "open";
VAL_ 588 BMS_PreHeatCoolReq 0 "Precondition OFF" 1 "Precondition Heating ON" 2 "Precondition Cooling ON" 3 "Invalid value";
VAL_ 596 QU_AVL_RPM_WHL_RLH 1 "Signal value is valid and secured and checked for plausibility" 2 "Reserved" 3 "Reserved" 4 "Substitute value is set in the useful signal" 6 "Signal value is invalid (Electrical fault, can be repaired)" 7 "Reserved" 8 "initialization" 9 "Reserved" 10 "Reserved" 11 "Signal quality or monitoring restricted, state / status temporary" 12 "Substitute value is set in the useful signal State / status temporary" 14 "Signal value is invalid (Electrical fault, can not repaired)" 15 "Signal invalid";
VAL_ 596 QU_AVL_RPM_WHL_RRH 1 "Signal value is valid and secured and checked for plausibility" 2 "Reserved" 3 "Reserved" 4 "Substitute value is set in the useful signal" 6 "Signal value is invalid (Electrical fault, can be repaired)" 7 "Reserved" 8 "initialization" 9 "Reserved" 10 "Reserved" 11 "Signal quality or monitoring restricted, state / status temporary" 12 "Substitute value is set in the useful signal State / status temporary" 14 "Signal value is invalid (Electrical fault, can not repaired)" 15 "Signal invalid";
VAL_ 597 QU_AVL_RPM_WHL_FLH 1 "Signal value is valid and secured and checked for plausibility" 2 "Reserved" 3 "Reserved" 4 "Substitute value is set in the useful signal" 6 "Signal value is invalid (Electrical fault, can be repaired)" 7 "Reserved" 8 "initialization" 9 "Reserved" 10 "Reserved" 11 "Signal quality or monitoring restricted, state / status temporary" 12 "Substitute value is set in the useful signal State / status temporary" 14 "Signal value is invalid (Electrical fault, can not repaired)" 15 "Signal invalid";
VAL_ 597 QU_AVL_RPM_WHL_FRH 1 "Signal value is valid and secured and checked for plausibility" 2 "Reserved" 3 "Reserved" 4 "Substitute value is set in the useful signal" 6 "Signal value is invalid (Electrical fault, can be repaired)" 7 "Reserved" 8 "initialization" 9 "Reserved" 10 "Reserved" 11 "Signal quality or monitoring restricted, state / status temporary" 12 "Substitute value is set in the useful signal State / status temporary" 14 "Signal value is invalid (Electrical fault, can not repaired)" 15 "Signal invalid";
VAL_ 620 HU_PASDirSel 0 "No Park Slot" 1 "FrntLeCrss" 2 "FrntLePrl" 3 "Frnt" 4 "FrntRiCrss" 5 "FrntRiPrl" 6 "Bck" 7 "BckLe" 8 "BckRi" 9 "Reserved" 10 "Reserved" 11 "Reserved" 12 "Reserved" 13 "Reserved" 14 "Reserved" 15 "SNA" ;
VAL_ 620 HU_AutPrkgSlotSel 0 "No slot" 1 "Left ID1" 2 "Left ID2" 3 "Left ID3" 4 "Right ID1" 5 "Right ID2" 6 "Right ID3" 7 "SNA" ;
VAL_ 641 NDoorRLOutsideHandleFailure 0 "Default (No Failure)" 1 "EEPROM, ROM and DSP self-test" 2 "Magnetic field is too low" 3 "Magnetic field is too high" 4 "Overvoltage" 5 "Undervoltage" 6 "A/D converter clipping" 7 "Reserved";
VAL_ 641 NDoorLatchRLFailure 0 "no fault" 1 "fault code" 2 "fault code" 3 "fault code" 4 "fault code" 5 "fault code" 6 "fault code" 63 "fault code";
VAL_ 649 AxOutStatus 0 "Valid" 1 "Invalid" ;
VAL_ 649 QU_VYAW_VEH 0 "Description for the value '0x0'" 1 "Description for the value '0x1'" ;
VAL_ 649 AyOutStatus 0 "Valid" 1 "Invalid" ;
VAL_ 649 AcceleratorY 16533 "Invalid" ;
VAL_ 649 AcceleratorX 16533 "Invalid" ;
VAL_ 654 Window_PosFL 0 "Closed (top)" 1 "Open (bottom)" 2 "Between 80% to closed" 3 "Between open to 80%" 4 "Reserved" 5 "Reserved" 6 "Reserved" 7 "Signal Invalid";
VAL_ 654 Window_Warning 0 "Not active" 1 "Active" 2 "Reserved" 3 "Signal Invalid";
VAL_ 654 Wndow_PosRL 0 "Closed (top)" 1 "Open (bottom)" 2 "Between 80% to closed" 3 "Between open to 80%" 4 "Reserved" 5 "Reserved" 6 "Reserved" 7 "Signal Invalid";
VAL_ 654 Window_PosFR 0 "Closed (top)" 1 "Open (bottom)" 2 "Between 80% to closed" 3 "Between open to 80%" 4 "Reserved" 5 "Reserved" 6 "Reserved" 7 "Signal Invalid";
VAL_ 654 Global_close 0 "Deactivated" 1 "Activated" 2 "Reserved" 3 "Signal Invalid";
VAL_ 654 Global_open 0 "Deactivated" 1 "Activated" 2 "Reserved" 3 "Signal Invalid";
VAL_ 654 Window_PosRR 0 "Closed (top)" 1 "Open (bottom)" 2 "Between 80% to closed" 3 "Between open to 80%" 4 "Reserved" 5 "Reserved" 6 "Reserved" 7 "Signal Invalid";

SIG_GROUP_  532 SG_BMS_2_MHU 1 : BMS_Display_SOC Checksum_0x214 Rolling_Counter_0x214;
